VERSION ""

NS_ :

BS_:

BU_: Turbocharger OnBoardDataLogger OffBoardDiagnosticTool2 OffBoardDiagnosticTool1 FileServer ParkingBrakeController SeatControl2 FanDriveController SteeringColumnUnit CommunicationUnitRadio CommunicationUnitSatellite CommunicationUnitCellular PropulsionBatteryCharger ChassisController2 ChassisController1 EngineValveControl AuxiliaryHeater2 AuxiliaryHeater1 ClutchUnit RampControl InformationSystem1 SuspensionSystemController2 OilSensor VehicleDynamicStability ExhaustEmissionController TransmissionDisplay2 TransmissionDisplay1 ClimateControl2 WaterPumpController RearAxleSteeringController LightingOperatorControl SeatController1 IgnitionController2 IgnitionController1 TirePressureController CabController2 CabController1 PneumaticSystemController SuspensionSystemController1 HydraulicPumpController EnduranceBrakingSystem RetarderExhaustEngine2 OnBoardDiagnosticUnit HeadwayController RetarderExhaustEngine1 CabDisplay1 ManagementComputer VirtualTerminal OffVehicleGateway PowerTakeOffFront HitchControl AuxiliaryValveControl BodyController TractorTrailerBridge1 StarterSystem ElectricalSystem VehicleSecurity VehicleNavigation AerodynamicControl ElectricalChargingSystem ClimateControl1 TripRecorder InstrumentCluster SuspensionDriveAxle2 SuspensionDriveAxle1 SuspensionSteerAxle SteeringController FuelSystem CruiseControl RetarderDriveline RetarderEngine BrakesDriveAxle2 BrakesDriveAxle1 BrakesSystemController BrakesSteerAxle AxleDrive2 AxleDrive1 AxleSteering PowerTakeOff ShiftConsoleSecondary ShiftConsolePrimary Transmission2 Transmission1 Engine2 Engine1
VAL_TABLE_ vtsig_Disable_VGT_Braking 3 "Description for the value '0x3'" 2 "Error" 1 "True" 0 "False" ;
VAL_TABLE_ vtsig_CoastModeStatus 3 "Not Available" 2 "Error" 1 "Enabled" 0 "Disabled" ;
VAL_TABLE_ vtsig_TransmissionType 15 "Legacy Trans" 0 "Fuel Eco Trans" ;

BO_ 3221225472 VECTOR__INDEPENDENT_SIG_MSG: 0 Vector__XXX
 SG_ TransCoastModeStatus : 0|2@1+ (1,0) [0|0] "" Vector__XXX
 SG_ TrailerWeight : 0|16@1+ (2,0) [0|128510] "kg" Vector__XXX
 SG_ ReferenceTirePressSetting : 0|8@1+ (8,0) [0|2000] "kPa" Vector__XXX
 SG_ ReferenceTirePress : 0|8@1+ (8,0) [0|2000] "kPa" Vector__XXX
 SG_ TirePressThresholdDetection : 0|3@1+ (1,0) [0|7] "" Vector__XXX
 SG_ TireAirLeakageRate : 0|16@1+ (0.1,0) [0|6425.5] "Pa/s" Vector__XXX
 SG_ CTIWheelEndElectricalFault : 0|2@1+ (1,0) [0|3] "" Vector__XXX
 SG_ CTITireStatus : 0|2@1+ (1,0) [0|3] "" Vector__XXX
 SG_ CTIWheelSensorStatus : 0|2@1+ (1,0) [0|3] "" Vector__XXX
 SG_ TireTemp : 0|16@1+ (0.03125,-273) [-273|1734.96875] "deg C" Vector__XXX
 SG_ TirePress : 0|8@1+ (4,0) [0|1000] "kPa" Vector__XXX
 SG_ DTC2 : 0|32@1+ (1,0) [0|4294967295] "" Vector__XXX
 SG_ DTC3 : 0|32@1+ (1,0) [0|4294967295] "" Vector__XXX
 SG_ DTC4 : 0|32@1+ (1,0) [0|4294967295] "" Vector__XXX
 SG_ SPNConversionMethod_DTC2 : 0|1@1+ (1,0) [0|1] "" Vector__XXX
 SG_ FMI_DTC6 : 0|5@1+ (1,0) [0|32] "" Vector__XXX
 SG_ SPNConversionMethod_DTC7 : 0|1@1+ (1,0) [0|1] "" Vector__XXX
 SG_ SPN3_DTC7 : 0|3@1+ (1,0) [0|7] "" Vector__XXX

BO_ 2565935153 B2_SA_31: 3 Vector__XXX
 SG_ BrakeSwitch2 : 16|2@1+ (1,0) [0|3] "" Vector__XXX
 SG_ DemandedBrakeApplicationPressure : 0|16@1+ (0.1,0) [0|6425.5] "kPa" Vector__XXX

BO_ 2565935127 B2_SA_17: 3 Vector__XXX
 SG_ BrakeSwitch2 : 16|2@1+ (1,0) [0|3] "" Vector__XXX
 SG_ DemandedBrakeApplicationPressure : 0|16@1+ (0.1,0) [0|6425.5] "kPa" Vector__XXX

BO_ 2565935121 B2_SA_11: 3 Vector__XXX
 SG_ BrakeSwitch2 : 16|2@1+ (1,0) [0|3] "" Vector__XXX
 SG_ DemandedBrakeApplicationPressure : 0|16@1+ (0.1,0) [0|6425.5] "kPa" Vector__XXX

BO_ 2565935115 B2_SA_0B: 3 Vector__XXX
 SG_ BrakeSwitch2 : 16|2@1+ (1,0) [0|3] "" Vector__XXX
 SG_ DemandedBrakeApplicationPressure : 0|16@1+ (0.1,0) [0|6425.5] "kPa" Vector__XXX

BO_ 2565935104 B2_SA_00: 3 Vector__XXX
 SG_ BrakeSwitch2 : 16|2@1+ (1,0) [0|3] "" Vector__XXX
 SG_ DemandedBrakeApplicationPressure : 0|16@1+ (0.1,0) [0|6425.5] "kPa" Vector__XXX

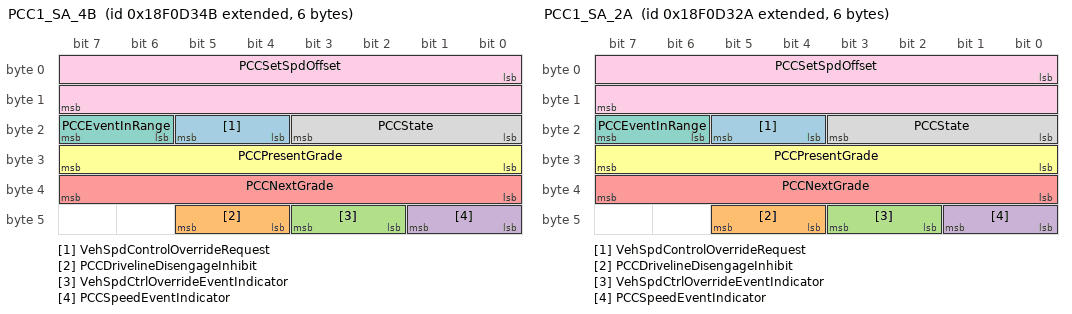
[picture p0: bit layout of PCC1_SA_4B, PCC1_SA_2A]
BO_ 2565919563 PCC1_SA_4B: 6 Vector__XXX
 SG_ VehSpdControlOverrideRequest : 20|2@1- (1,0) [0|0] "" Vector__XXX
 SG_ PCCDrivelineDisengageInhibit : 44|2@1- (1,0) [0|0] "" Vector__XXX
 SG_ VehSpdCtrlOverrideEventIndicator : 42|2@1- (1,0) [0|0] "" Vector__XXX
 SG_ PCCSpeedEventIndicator : 40|2@1- (1,0) [0|0] "" Vector__XXX
 SG_ PCCNextGrade : 32|8@1+ (0.125,-16) [0|0] "" Vector__XXX
 SG_ PCCPresentGrade : 24|8@1+ (0.125,-16) [0|0] "" Vector__XXX
 SG_ PCCEventInRange : 22|2@1- (1,0) [0|0] "" Vector__XXX
 SG_ PCCState : 16|4@1- (1,0) [0|0] "" Vector__XXX
 SG_ PCCSetSpdOffset : 0|16@1- (0.00390625,-125) [-125|126] "km/h" Vector__XXX

BO_ 2565919530 PCC1_SA_2A: 6 Vector__XXX
 SG_ VehSpdControlOverrideRequest : 20|2@1- (1,0) [0|0] "" Vector__XXX
 SG_ PCCDrivelineDisengageInhibit : 44|2@1- (1,0) [0|0] "" Vector__XXX
 SG_ VehSpdCtrlOverrideEventIndicator : 42|2@1- (1,0) [0|0] "" Vector__XXX
 SG_ PCCSpeedEventIndicator : 40|2@1- (1,0) [0|0] "" Vector__XXX
 SG_ PCCNextGrade : 32|8@1+ (0.125,-16) [0|0] "" Vector__XXX
 SG_ PCCPresentGrade : 24|8@1+ (0.125,-16) [0|0] "" Vector__XXX
 SG_ PCCEventInRange : 22|2@1- (1,0) [0|0] "" Vector__XXX
 SG_ PCCState : 16|4@1- (1,0) [0|0] "" Vector__XXX
 SG_ PCCSetSpdOffset : 0|16@1- (0.00390625,-125) [-125|126] "km/h" Vector__XXX

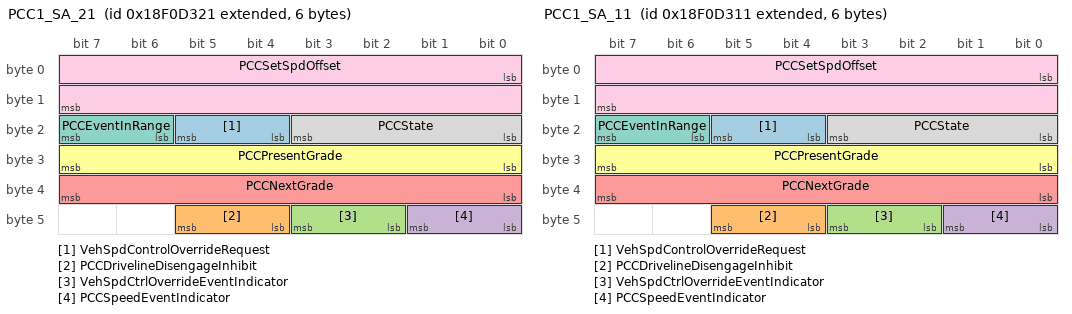
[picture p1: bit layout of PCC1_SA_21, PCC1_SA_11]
BO_ 2565919521 PCC1_SA_21: 6 Vector__XXX
 SG_ VehSpdControlOverrideRequest : 20|2@1- (1,0) [0|0] "" Vector__XXX
 SG_ PCCDrivelineDisengageInhibit : 44|2@1- (1,0) [0|0] "" Vector__XXX
 SG_ VehSpdCtrlOverrideEventIndicator : 42|2@1- (1,0) [0|0] "" Vector__XXX
 SG_ PCCSpeedEventIndicator : 40|2@1- (1,0) [0|0] "" Vector__XXX
 SG_ PCCNextGrade : 32|8@1+ (0.125,-16) [0|0] "" Vector__XXX
 SG_ PCCPresentGrade : 24|8@1+ (0.125,-16) [0|0] "" Vector__XXX
 SG_ PCCEventInRange : 22|2@1- (1,0) [0|0] "" Vector__XXX
 SG_ PCCState : 16|4@1- (1,0) [0|0] "" Vector__XXX
 SG_ PCCSetSpdOffset : 0|16@1- (0.00390625,-125) [-125|126] "km/h" Vector__XXX

BO_ 2565919505 PCC1_SA_11: 6 Vector__XXX
 SG_ VehSpdControlOverrideRequest : 20|2@1- (1,0) [0|0] "" Vector__XXX
 SG_ PCCDrivelineDisengageInhibit : 44|2@1- (1,0) [0|0] "" Vector__XXX
 SG_ VehSpdCtrlOverrideEventIndicator : 42|2@1- (1,0) [0|0] "" Vector__XXX
 SG_ PCCSpeedEventIndicator : 40|2@1- (1,0) [0|0] "" Vector__XXX
 SG_ PCCNextGrade : 32|8@1+ (0.125,-16) [0|0] "" Vector__XXX
 SG_ PCCPresentGrade : 24|8@1+ (0.125,-16) [0|0] "" Vector__XXX
 SG_ PCCEventInRange : 22|2@1- (1,0) [0|0] "" Vector__XXX
 SG_ PCCState : 16|4@1- (1,0) [0|0] "" Vector__XXX
 SG_ PCCSetSpdOffset : 0|16@1- (0.00390625,-125) [-125|126] "km/h" Vector__XXX

BO_ 2566705667 DM54_SA_03: 54 Vector__XXX
 SG_ DM54_SPNConversionMethod_DTC8 : 271|1@1+ (1,0) [0|1] "" Vector__XXX
 SG_ DM54_OccurenceCount_DTC8 : 264|7@1+ (1,0) [0|126] "" Vector__XXX
 SG_ DM54_SPN3_DTC8 : 261|3@1+ (1,0) [0|7] "" Vector__XXX
 SG_ DM54_FMI_DTC8 : 256|5@1+ (1,0) [0|32] "" Vector__XXX
 SG_ DM54_SPN2_DTC8 : 248|8@1+ (1,0) [0|255] "" Vector__XXX
 SG_ DM54_SPN1_DTC8 : 240|8@1+ (1,0) [0|255] "" Vector__XXX
 SG_ DM54_SPNConversionMethod_DTC7 : 239|1@1+ (1,0) [0|1] "" Vector__XXX
 SG_ DM54_OccurenceCount_DTC7 : 232|7@1+ (1,0) [0|126] "" Vector__XXX
 SG_ DM54_SPN3_DTC7 : 229|3@1+ (1,0) [0|7] "" Vector__XXX
 SG_ DM54_FMI_DTC7 : 224|5@1+ (1,0) [0|32] "" Vector__XXX
 SG_ DM54_SPN2_DTC7 : 216|8@1+ (1,0) [0|255] "" Vector__XXX
 SG_ DM54_SPN1_DTC7 : 208|8@1+ (1,0) [0|255] "" Vector__XXX
 SG_ DM54_SPNConversionMethod_DTC6 : 207|1@1+ (1,0) [0|1] "" Vector__XXX
 SG_ DM54_OccurenceCount_DTC6 : 200|7@1+ (1,0) [0|126] "" Vector__XXX
 SG_ DM54_SPN3_DTC6 : 197|3@1+ (1,0) [0|7] "" Vector__XXX
 SG_ DM54_FMI_DTC6 : 192|5@1+ (1,0) [0|32] "" Vector__XXX
 SG_ DM54_SPN2_DTC6 : 184|8@1+ (1,0) [0|255] "" Vector__XXX
 SG_ DM54_SPN1_DTC6 : 176|8@1+ (1,0) [0|255] "" Vector__XXX
 SG_ DM54_SPNConversionMethod_DTC5 : 175|1@1+ (1,0) [0|1] "" Vector__XXX
 SG_ DM54_OccurenceCount_DTC5 : 168|7@1+ (1,0) [0|126] "" Vector__XXX
 SG_ DM54_SPN3_DTC5 : 165|3@1+ (1,0) [0|7] "" Vector__XXX
 SG_ DM54_FMI_DTC5 : 160|5@1+ (1,0) [0|32] "" Vector__XXX
 SG_ DM54_SPN2_DTC5 : 152|8@1+ (1,0) [0|255] "" Vector__XXX
 SG_ DM54_SPN1_DTC5 : 144|8@1+ (1,0) [0|255] "" Vector__XXX
 SG_ DM54_SPNConversionMethod_DTC4 : 143|1@1+ (1,0) [0|1] "" Vector__XXX
 SG_ DM54_OccurenceCount_DTC4 : 136|7@1+ (1,0) [0|126] "" Vector__XXX
 SG_ DM54_SPN3_DTC4 : 133|3@1+ (1,0) [0|7] "" Vector__XXX
 SG_ DM54_FMI_DTC4 : 128|5@1+ (1,0) [0|32] "" Vector__XXX
 SG_ DM54_SPN2_DTC4 : 120|8@1+ (1,0) [0|255] "" Vector__XXX
 SG_ DM54_SPN1_DTC4 : 112|8@1+ (1,0) [0|255] "" Vector__XXX
 SG_ DM54_SPNConversionMethod_DTC3 : 111|1@1+ (1,0) [0|1] "" Vector__XXX
 SG_ DM54_OccurenceCount_DTC3 : 104|7@1+ (1,0) [0|126] "" Vector__XXX
 SG_ DM54_SPN3_DTC3 : 101|3@1+ (1,0) [0|7] "" Vector__XXX
 SG_ DM54_FMI_DTC3 : 96|5@1+ (1,0) [0|32] "" Vector__XXX
 SG_ DM54_SPN2_DTC3 : 88|8@1+ (1,0) [0|255] "" Vector__XXX
 SG_ DM54_SPN1_DTC3 : 80|8@1+ (1,0) [0|255] "" Vector__XXX
 SG_ DM54_SPNConversionMethod_DTC2 : 79|1@1+ (1,0) [0|1] "" Vector__XXX
 SG_ DM54_OccurenceCount_DTC2 : 72|7@1+ (1,0) [0|126] "" Vector__XXX
 SG_ DM54_SPN3_DTC2 : 69|3@1+ (1,0) [0|7] "" Vector__XXX
 SG_ DM54_FMI_DTC2 : 64|5@1+ (1,0) [0|32] "" Vector__XXX
 SG_ DM54_SPN2_DTC2 : 56|8@1+ (1,0) [0|255] "" Vector__XXX
 SG_ DM54_SPN1_DTC2 : 48|8@1+ (1,0) [0|255] "" Vector__XXX
 SG_ DM54_SPNConversionMethod_DTC1 : 47|1@1+ (1,0) [0|1] "" Vector__XXX
 SG_ DM54_OccurenceCount_DTC1 : 40|7@1+ (1,0) [0|126] "" Vector__XXX
 SG_ DM54_SPN3_DTC1 : 37|3@1+ (1,0) [0|7] "" Vector__XXX
 SG_ DM54_FMI_DTC1 : 32|5@1+ (1,0) [0|32] "" Vector__XXX
 SG_ DM54_SPN2_DTC1 : 24|8@1+ (1,0) [0|255] "" Vector__XXX
 SG_ DM54_SPN1_DTC1 : 16|8@1+ (1,0) [0|255] "" Vector__XXX
 SG_ DM54FlashMalfuncIndicatorLamp : 14|2@1+ (1,0) [0|3] "" Vector__XXX
 SG_ DM54FlashRedStopLamp : 12|2@1+ (1,0) [0|3] "" Vector__XXX
 SG_ DM54FlashAmberWarningLamp : 10|2@1+ (1,0) [0|3] "" Vector__XXX
 SG_ DM54FlashProtectLamp : 8|2@1+ (1,0) [0|3] "" Vector__XXX
 SG_ DM54MalfunctionIndicateLampState : 6|2@1+ (1,0) [0|3] "" Vector__XXX
 SG_ DM54RedStopLampState : 4|2@1+ (1,0) [0|3] "" Vector__XXX
 SG_ DM54AmberWarningLampStatus : 2|2@1+ (1,0) [0|3] "" Vector__XXX
 SG_ DM54ProtectLampStatus : 0|2@1+ (1,0) [0|3] "" Vector__XXX

BO_ 2566705411 DM53_SA_03: 54 Vector__XXX
 SG_ DM53_SPNConversionMethod_DTC8 : 271|1@1+ (1,0) [0|1] "" Vector__XXX
 SG_ DM53_OccurenceCount_DTC8 : 264|7@1+ (1,0) [0|126] "" Vector__XXX
 SG_ DM53_SPN3_DTC8 : 261|3@1+ (1,0) [0|7] "" Vector__XXX
 SG_ DM53_FMI_DTC8 : 256|5@1+ (1,0) [0|32] "" Vector__XXX
 SG_ DM53_SPN2_DTC8 : 248|8@1+ (1,0) [0|255] "" Vector__XXX
 SG_ DM53_SPN1_DTC8 : 240|8@1+ (1,0) [0|255] "" Vector__XXX
 SG_ DM53_SPNConversionMethod_DTC7 : 239|1@1+ (1,0) [0|1] "" Vector__XXX
 SG_ DM53_OccurenceCount_DTC7 : 232|7@1+ (1,0) [0|126] "" Vector__XXX
 SG_ DM53_SPN3_DTC7 : 229|3@1+ (1,0) [0|7] "" Vector__XXX
 SG_ DM53_FMI_DTC7 : 224|5@1+ (1,0) [0|32] "" Vector__XXX
 SG_ DM53_SPN2_DTC7 : 216|8@1+ (1,0) [0|255] "" Vector__XXX
 SG_ DM53_SPN1_DTC7 : 208|8@1+ (1,0) [0|255] "" Vector__XXX
 SG_ DM53_SPNConversionMethod_DTC6 : 207|1@1+ (1,0) [0|1] "" Vector__XXX
 SG_ DM53_OccurenceCount_DTC6 : 200|7@1+ (1,0) [0|126] "" Vector__XXX
 SG_ DM53_SPN3_DTC6 : 197|3@1+ (1,0) [0|7] "" Vector__XXX
 SG_ DM53_FMI_DTC6 : 192|5@1+ (1,0) [0|32] "" Vector__XXX
 SG_ DM53_SPN2_DTC6 : 184|8@1+ (1,0) [0|255] "" Vector__XXX
 SG_ DM53_SPN1_DTC6 : 176|8@1+ (1,0) [0|255] "" Vector__XXX
 SG_ DM53_SPNConversionMethod_DTC5 : 175|1@1+ (1,0) [0|1] "" Vector__XXX
 SG_ DM53_OccurenceCount_DTC5 : 168|7@1+ (1,0) [0|126] "" Vector__XXX
 SG_ DM53_SPN3_DTC5 : 165|3@1+ (1,0) [0|7] "" Vector__XXX
 SG_ DM53_FMI_DTC5 : 160|5@1+ (1,0) [0|32] "" Vector__XXX
 SG_ DM53_SPN2_DTC5 : 152|8@1+ (1,0) [0|255] "" Vector__XXX
 SG_ DM53_SPN1_DTC5 : 144|8@1+ (1,0) [0|255] "" Vector__XXX
 SG_ DM53_SPNConversionMethod_DTC4 : 143|1@1+ (1,0) [0|1] "" Vector__XXX
 SG_ DM53_OccurenceCount_DTC4 : 136|7@1+ (1,0) [0|126] "" Vector__XXX
 SG_ DM53_SPN3_DTC4 : 133|3@1+ (1,0) [0|7] "" Vector__XXX
 SG_ DM53_FMI_DTC4 : 128|5@1+ (1,0) [0|32] "" Vector__XXX
 SG_ DM53_SPN2_DTC4 : 120|8@1+ (1,0) [0|255] "" Vector__XXX
 SG_ DM53_SPN1_DTC4 : 112|8@1+ (1,0) [0|255] "" Vector__XXX
 SG_ DM53_SPNConversionMethod_DTC3 : 111|1@1+ (1,0) [0|1] "" Vector__XXX
 SG_ DM53_OccurenceCount_DTC3 : 104|7@1+ (1,0) [0|126] "" Vector__XXX
 SG_ DM53_SPN3_DTC3 : 101|3@1+ (1,0) [0|7] "" Vector__XXX
 SG_ DM53_FMI_DTC3 : 96|5@1+ (1,0) [0|32] "" Vector__XXX
 SG_ DM53_SPN2_DTC3 : 88|8@1+ (1,0) [0|255] "" Vector__XXX
 SG_ DM53_SPN1_DTC3 : 80|8@1+ (1,0) [0|255] "" Vector__XXX
 SG_ DM53_SPNConversionMethod_DTC2 : 79|1@1+ (1,0) [0|1] "" Vector__XXX
 SG_ DM53_OccurenceCount_DTC2 : 72|7@1+ (1,0) [0|126] "" Vector__XXX
 SG_ DM53_SPN3_DTC2 : 69|3@1+ (1,0) [0|7] "" Vector__XXX
 SG_ DM53_FMI_DTC2 : 64|5@1+ (1,0) [0|32] "" Vector__XXX
 SG_ DM53_SPN2_DTC2 : 56|8@1+ (1,0) [0|255] "" Vector__XXX
 SG_ DM53_SPN1_DTC2 : 48|8@1+ (1,0) [0|255] "" Vector__XXX
 SG_ DM53_SPNConversionMethod_DTC1 : 47|1@1+ (1,0) [0|1] "" Vector__XXX
 SG_ DM53_OccurenceCount_DTC1 : 40|7@1+ (1,0) [0|126] "" Vector__XXX
 SG_ DM53_SPN3_DTC1 : 37|3@1+ (1,0) [0|7] "" Vector__XXX
 SG_ DM53_FMI_DTC1 : 32|5@1+ (1,0) [0|32] "" Vector__XXX
 SG_ DM53_SPN2_DTC1 : 24|8@1+ (1,0) [0|255] "" Vector__XXX
 SG_ DM53_SPN1_DTC1 : 16|8@1+ (1,0) [0|255] "" Vector__XXX
 SG_ DM53FlashMalfuncIndicatorLamp : 14|2@1+ (1,0) [0|3] "" Vector__XXX
 SG_ DM53FlashRedStopLamp : 12|2@1+ (1,0) [0|3] "" Vector__XXX
 SG_ DM53FlashAmberWarningLamp : 10|2@1+ (1,0) [0|3] "" Vector__XXX
 SG_ DM53FlashProtectLamp : 8|2@1+ (1,0) [0|3] "" Vector__XXX
 SG_ DM53MalfunctionIndicateLampState : 6|2@1+ (1,0) [0|3] "" Vector__XXX
 SG_ DM53RedStopLampState : 4|2@1+ (1,0) [0|3] "" Vector__XXX
 SG_ DM53AmberWarningLampStatus : 2|2@1+ (1,0) [0|3] "" Vector__XXX
 SG_ DM53ProtectLampStatus : 0|2@1+ (1,0) [0|3] "" Vector__XXX

BO_ 2565935358 B2: 3 Vector__XXX
 SG_ BrakeSwitch2 : 16|2@1+ (1,0) [0|3] "" Vector__XXX
 SG_ DemandedBrakeApplicationPressure : 0|16@1+ (0.1,0) [0|6425.5] "kPa" Vector__XXX

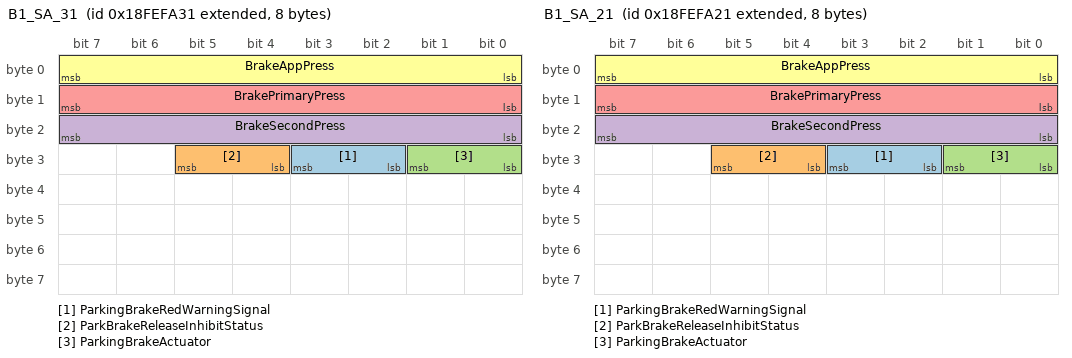
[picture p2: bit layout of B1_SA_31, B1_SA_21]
BO_ 2566847025 B1_SA_31: 8 Vector__XXX
 SG_ ParkingBrakeRedWarningSignal : 26|2@1+ (1,0) [0|3] "" Vector__XXX
 SG_ ParkBrakeReleaseInhibitStatus : 28|2@1+ (1,0) [0|3] "" Vector__XXX
 SG_ ParkingBrakeActuator : 24|2@1+ (1,0) [0|3] "" Vector__XXX
 SG_ BrakeSecondPress : 16|8@1+ (4,0) [0|1000] "kPa" Vector__XXX
 SG_ BrakePrimaryPress : 8|8@1+ (4,0) [0|1000] "kPa" Vector__XXX
 SG_ BrakeAppPress : 0|8@1+ (4,0) [0|1000] "kPa" Vector__XXX

BO_ 2566847009 B1_SA_21: 8 Vector__XXX
 SG_ ParkingBrakeRedWarningSignal : 26|2@1+ (1,0) [0|3] "" Vector__XXX
 SG_ ParkBrakeReleaseInhibitStatus : 28|2@1+ (1,0) [0|3] "" Vector__XXX
 SG_ ParkingBrakeActuator : 24|2@1+ (1,0) [0|3] "" Vector__XXX
 SG_ BrakeSecondPress : 16|8@1+ (4,0) [0|1000] "kPa" Vector__XXX
 SG_ BrakePrimaryPress : 8|8@1+ (4,0) [0|1000] "kPa" Vector__XXX
 SG_ BrakeAppPress : 0|8@1+ (4,0) [0|1000] "kPa" Vector__XXX

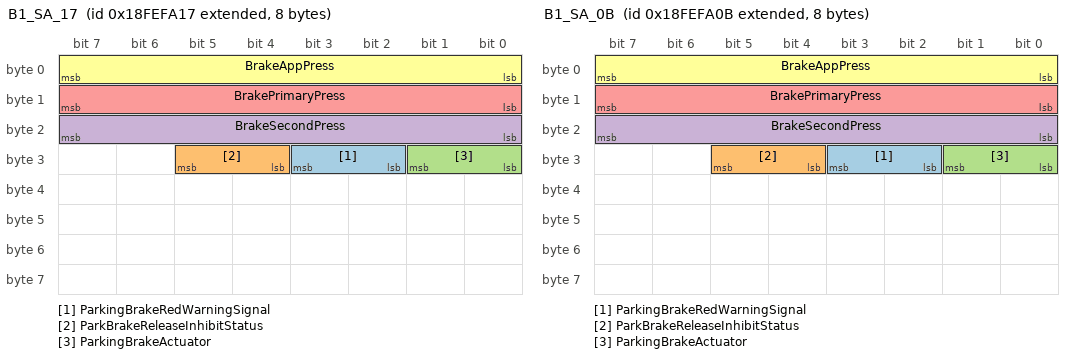
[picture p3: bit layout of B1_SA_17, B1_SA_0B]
BO_ 2566846999 B1_SA_17: 8 Vector__XXX
 SG_ ParkingBrakeRedWarningSignal : 26|2@1+ (1,0) [0|3] "" Vector__XXX
 SG_ ParkBrakeReleaseInhibitStatus : 28|2@1+ (1,0) [0|3] "" Vector__XXX
 SG_ ParkingBrakeActuator : 24|2@1+ (1,0) [0|3] "" Vector__XXX
 SG_ BrakeSecondPress : 16|8@1+ (4,0) [0|1000] "kPa" Vector__XXX
 SG_ BrakePrimaryPress : 8|8@1+ (4,0) [0|1000] "kPa" Vector__XXX
 SG_ BrakeAppPress : 0|8@1+ (4,0) [0|1000] "kPa" Vector__XXX

BO_ 2566846987 B1_SA_0B: 8 Vector__XXX
 SG_ ParkingBrakeRedWarningSignal : 26|2@1+ (1,0) [0|3] "" Vector__XXX
 SG_ ParkBrakeReleaseInhibitStatus : 28|2@1+ (1,0) [0|3] "" Vector__XXX
 SG_ ParkingBrakeActuator : 24|2@1+ (1,0) [0|3] "" Vector__XXX
 SG_ BrakeSecondPress : 16|8@1+ (4,0) [0|1000] "kPa" Vector__XXX
 SG_ BrakePrimaryPress : 8|8@1+ (4,0) [0|1000] "kPa" Vector__XXX
 SG_ BrakeAppPress : 0|8@1+ (4,0) [0|1000] "kPa" Vector__XXX

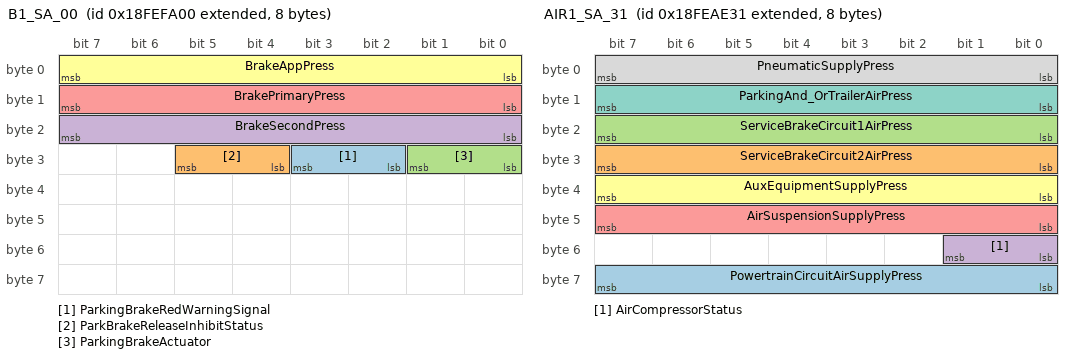
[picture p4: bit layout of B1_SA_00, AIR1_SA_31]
BO_ 2566846976 B1_SA_00: 8 Vector__XXX
 SG_ ParkingBrakeRedWarningSignal : 26|2@1+ (1,0) [0|3] "" Vector__XXX
 SG_ ParkBrakeReleaseInhibitStatus : 28|2@1+ (1,0) [0|3] "" Vector__XXX
 SG_ ParkingBrakeActuator : 24|2@1+ (1,0) [0|3] "" Vector__XXX
 SG_ BrakeSecondPress : 16|8@1+ (4,0) [0|1000] "kPa" Vector__XXX
 SG_ BrakePrimaryPress : 8|8@1+ (4,0) [0|1000] "kPa" Vector__XXX
 SG_ BrakeAppPress : 0|8@1+ (4,0) [0|1000] "kPa" Vector__XXX

BO_ 2566827569 AIR1_SA_31: 8 Vector__XXX
 SG_ PowertrainCircuitAirSupplyPress : 56|8@1+ (8,0) [0|2000] "kPa" Vector__XXX
 SG_ ServiceBrakeCircuit2AirPress : 24|8@1+ (8,0) [0|2000] "kPa" Vector__XXX
 SG_ ServiceBrakeCircuit1AirPress : 16|8@1+ (8,0) [0|2000] "kPa" Vector__XXX
 SG_ AirCompressorStatus : 48|2@1+ (1,0) [0|3] "" Vector__XXX
 SG_ AirSuspensionSupplyPress : 40|8@1+ (8,0) [0|2000] "kPa" Vector__XXX
 SG_ AuxEquipmentSupplyPress : 32|8@1+ (8,0) [0|2000] "kPa" Vector__XXX
 SG_ ParkingAnd_OrTrailerAirPress : 8|8@1+ (8,0) [0|2000] "kPa" Vector__XXX
 SG_ PneumaticSupplyPress : 0|8@1+ (8,0) [0|2000] "kPa" Vector__XXX

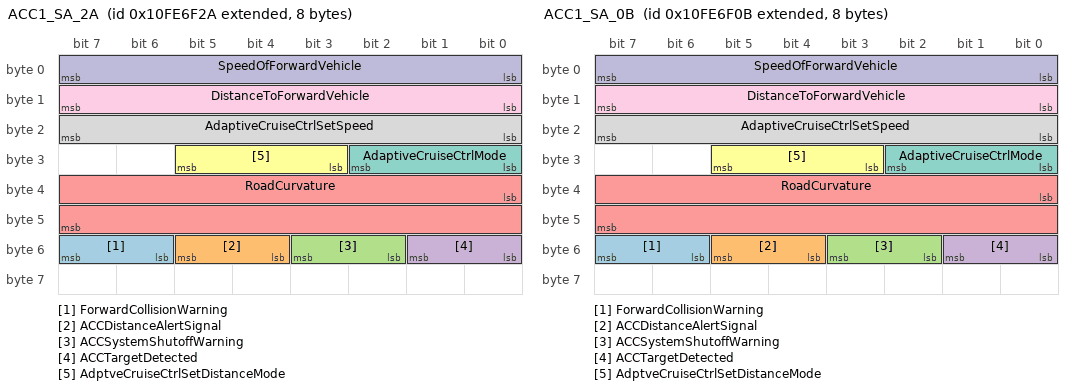
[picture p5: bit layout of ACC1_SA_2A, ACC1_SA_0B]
BO_ 2432593706 ACC1_SA_2A: 8 Vector__XXX
 SG_ ForwardCollisionWarning : 54|2@1+ (1,0) [0|3] "" Vector__XXX
 SG_ ACCDistanceAlertSignal : 52|2@1+ (1,0) [0|3] "" Vector__XXX
 SG_ ACCSystemShutoffWarning : 50|2@1+ (1,0) [0|3] "" Vector__XXX
 SG_ ACCTargetDetected : 48|2@1+ (1,0) [0|3] "" Vector__XXX
 SG_ RoadCurvature : 32|16@1+ (0.0078125,-250) [-250|251.992] "1/km" Vector__XXX
 SG_ AdptveCruiseCtrlSetDistanceMode : 27|3@1+ (1,0) [0|7] "" Vector__XXX
 SG_ AdaptiveCruiseCtrlMode : 24|3@1+ (1,0) [0|7] "" Vector__XXX
 SG_ AdaptiveCruiseCtrlSetSpeed : 16|8@1+ (1,0) [0|250] "km/h" Vector__XXX
 SG_ DistanceToForwardVehicle : 8|8@1+ (1,0) [0|250] "m" Vector__XXX
 SG_ SpeedOfForwardVehicle : 0|8@1+ (1,0) [0|250] "km/h" Vector__XXX

BO_ 2432593675 ACC1_SA_0B: 8 Vector__XXX
 SG_ ForwardCollisionWarning : 54|2@1+ (1,0) [0|3] "" Vector__XXX
 SG_ ACCDistanceAlertSignal : 52|2@1+ (1,0) [0|3] "" Vector__XXX
 SG_ ACCSystemShutoffWarning : 50|2@1+ (1,0) [0|3] "" Vector__XXX
 SG_ ACCTargetDetected : 48|2@1+ (1,0) [0|3] "" Vector__XXX
 SG_ RoadCurvature : 32|16@1+ (0.0078125,-250) [-250|251.992] "1/km" Vector__XXX
 SG_ AdptveCruiseCtrlSetDistanceMode : 27|3@1+ (1,0) [0|7] "" Vector__XXX
 SG_ AdaptiveCruiseCtrlMode : 24|3@1+ (1,0) [0|7] "" Vector__XXX
 SG_ AdaptiveCruiseCtrlSetSpeed : 16|8@1+ (1,0) [0|250] "km/h" Vector__XXX
 SG_ DistanceToForwardVehicle : 8|8@1+ (1,0) [0|250] "m" Vector__XXX
 SG_ SpeedOfForwardVehicle : 0|8@1+ (1,0) [0|250] "km/h" Vector__XXX

BO_ 2566840617 RC_SA_29: 19 Vector__XXX
 SG_ PercentTorqueAtPeakTorquePoint5 : 144|8@1+ (1,-125) [-125|125] "%" Vector__XXX
 SG_ ReferenceRetarderTorque : 128|16@1+ (1,0) [0|64255] "Nm" Vector__XXX
 SG_ RetarderSpeedAtPeakTorquePoint5 : 112|16@1+ (0.125,0) [0|8031.875] "rpm" Vector__XXX
 SG_ PercentTorqueAtPoint4 : 104|8@1+ (1,-125) [-125|125] "%" Vector__XXX
 SG_ RetarderSpeedAtPoint4 : 88|16@1+ (0.125,0) [0|8031.875] "rpm" Vector__XXX
 SG_ PercentTorqueAtPoint3 : 80|8@1+ (1,-125) [-125|125] "%" Vector__XXX
 SG_ RetarderSpeedAtPoint3 : 64|16@1+ (0.125,0) [0|8031.875] "rpm" Vector__XXX
 SG_ PercentTorqueAtMaxSpeedPoint2 : 56|8@1+ (1,-125) [-125|125] "%" Vector__XXX
 SG_ MaxRetarderSpeedPoint2 : 40|16@1+ (0.125,0) [0|8031.875] "rpm" Vector__XXX
 SG_ PercentTorqueAtIdlePoint1 : 32|8@1+ (1,-125) [-125|125] "%" Vector__XXX
 SG_ RetarderSpeedAtIdlePoint1 : 16|16@1+ (0.125,0) [0|8031.875] "rpm" Vector__XXX
 SG_ RetarderCtrlMethod : 8|8@1+ (1,0) [0|250] "steps" Vector__XXX
 SG_ RetarderLocation : 4|4@1+ (1,0) [0|15] "" Vector__XXX
 SG_ RetarderType : 0|4@1+ (1,0) [0|15] "" Vector__XXX

BO_ 2566840591 RC_SA_0F: 19 Vector__XXX
 SG_ PercentTorqueAtPeakTorquePoint5 : 144|8@1+ (1,-125) [-125|125] "%" Vector__XXX
 SG_ ReferenceRetarderTorque : 128|16@1+ (1,0) [0|64255] "Nm" Vector__XXX
 SG_ RetarderSpeedAtPeakTorquePoint5 : 112|16@1+ (0.125,0) [0|8031.875] "rpm" Vector__XXX
 SG_ PercentTorqueAtPoint4 : 104|8@1+ (1,-125) [-125|125] "%" Vector__XXX
 SG_ RetarderSpeedAtPoint4 : 88|16@1+ (0.125,0) [0|8031.875] "rpm" Vector__XXX
 SG_ PercentTorqueAtPoint3 : 80|8@1+ (1,-125) [-125|125] "%" Vector__XXX
 SG_ RetarderSpeedAtPoint3 : 64|16@1+ (0.125,0) [0|8031.875] "rpm" Vector__XXX
 SG_ PercentTorqueAtMaxSpeedPoint2 : 56|8@1+ (1,-125) [-125|125] "%" Vector__XXX
 SG_ MaxRetarderSpeedPoint2 : 40|16@1+ (0.125,0) [0|8031.875] "rpm" Vector__XXX
 SG_ PercentTorqueAtIdlePoint1 : 32|8@1+ (1,-125) [-125|125] "%" Vector__XXX
 SG_ RetarderSpeedAtIdlePoint1 : 16|16@1+ (0.125,0) [0|8031.875] "rpm" Vector__XXX
 SG_ RetarderCtrlMethod : 8|8@1+ (1,0) [0|250] "steps" Vector__XXX
 SG_ RetarderLocation : 4|4@1+ (1,0) [0|15] "" Vector__XXX
 SG_ RetarderType : 0|4@1+ (1,0) [0|15] "" Vector__XXX

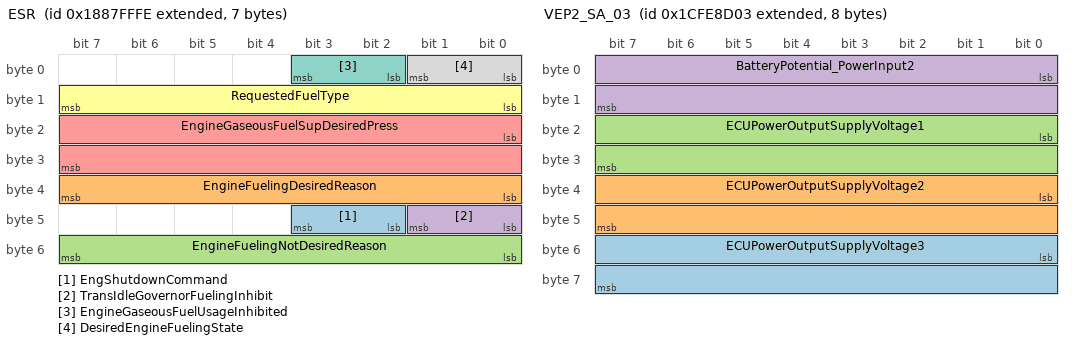
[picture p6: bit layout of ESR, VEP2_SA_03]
BO_ 2559049726 ESR: 7 Vector__XXX
 SG_ EngShutdownCommand : 42|2@1+ (1,0) [0|3] "" Vector__XXX
 SG_ EngineFuelingDesiredReason : 32|8@1+ (1,0) [0|255] "" Vector__XXX
 SG_ EngineFuelingNotDesiredReason : 48|8@1+ (1,0) [0|255] "" Vector__XXX
 SG_ TransIdleGovernorFuelingInhibit : 40|2@1+ (1,0) [0|3] "" Vector__XXX
 SG_ EngineGaseousFuelSupDesiredPress : 16|16@1+ (0.5,0) [0|32127.5] "kPa" Vector__XXX
 SG_ RequestedFuelType : 8|8@1+ (1,0) [0|255] "" Vector__XXX
 SG_ EngineGaseousFuelUsageInhibited : 2|2@1+ (1,0) [0|3] "" Vector__XXX
 SG_ DesiredEngineFuelingState : 0|2@1+ (1,0) [0|3] "" Vector__XXX

BO_ 2566759473 PTODE_SA_31: 8 Vector__XXX
 SG_ EnggmntSttusTransInputShaftPTO1 : 38|2@1+ (1,0) [0|3] "" Vector__XXX
 SG_ EnggmntSttusTransInputShaftPTO2 : 36|2@1+ (1,0) [0|3] "" Vector__XXX
 SG_ EnggmntSttusTransOutputShaftPTO : 34|2@1+ (1,0) [0|3] "" Vector__XXX
 SG_ EnggmntSttsTrnsfrCsOtptShaftPTO : 32|2@1+ (1,0) [0|3] "" Vector__XXX
 SG_ EnggmntCnsntTransInputShaftPTO1 : 22|2@1+ (1,0) [0|3] "" Vector__XXX
 SG_ EnggmntCnsntTransInputShaftPTO2 : 20|2@1+ (1,0) [0|3] "" Vector__XXX
 SG_ EnggmntCnsntTransOutputShaftPTO : 18|2@1+ (1,0) [0|3] "" Vector__XXX
 SG_ EnggmntCnsntTrnsfrCsOtptShftPTO : 16|2@1+ (1,0) [0|3] "" Vector__XXX
 SG_ EnableSwitchTransInputShaftPTO1 : 6|2@1+ (1,0) [0|3] "" Vector__XXX
 SG_ EnableSwitchTransInputShaftPTO2 : 4|2@1+ (1,0) [0|3] "" Vector__XXX
 SG_ EnableSwitchTransOutputShaftPTO : 2|2@1+ (1,0) [0|3] "" Vector__XXX
 SG_ EnblSwtchTrnsfrCsOutputShaftPTO : 0|2@1+ (1,0) [0|3] "" Vector__XXX
 SG_ EnggmntSttsPTOEngAccssoryDrive2 : 44|2@1+ (1,0) [0|3] "" Vector__XXX
 SG_ EnggmntSttsPTOEngAccssoryDrive1 : 42|2@1+ (1,0) [0|3] "" Vector__XXX
 SG_ EnggmntCnsntPTOEngAccssryDrive2 : 28|2@1+ (1,0) [0|3] "" Vector__XXX
 SG_ EnggmntCnsntPTOEngAccssryDrive1 : 26|2@1+ (1,0) [0|3] "" Vector__XXX
 SG_ EngagementStatusPTOEngFlywheel : 40|2@1+ (1,0) [0|3] "" Vector__XXX
 SG_ EngagementConsentPTOEngFlywheel : 24|2@1+ (1,0) [0|3] "" Vector__XXX
 SG_ EnblSwitchPTOEngAccessoryDrive2 : 12|2@1+ (1,0) [0|3] "" Vector__XXX
 SG_ EnblSwitchPTOEngAccessoryDrive1 : 10|2@1+ (1,0) [0|3] "" Vector__XXX
 SG_ EnableSwitchPTOEngFlywheel : 8|2@1+ (1,0) [0|3] "" Vector__XXX
 SG_ AtLeastOnePTOEngaged : 48|2@1+ (1,0) [0|3] "" Vector__XXX

BO_ 2566759463 PTODE_SA_27: 8 Vector__XXX
 SG_ EnggmntSttusTransInputShaftPTO1 : 38|2@1+ (1,0) [0|3] "" Vector__XXX
 SG_ EnggmntSttusTransInputShaftPTO2 : 36|2@1+ (1,0) [0|3] "" Vector__XXX
 SG_ EnggmntSttusTransOutputShaftPTO : 34|2@1+ (1,0) [0|3] "" Vector__XXX
 SG_ EnggmntSttsTrnsfrCsOtptShaftPTO : 32|2@1+ (1,0) [0|3] "" Vector__XXX
 SG_ EnggmntCnsntTransInputShaftPTO1 : 22|2@1+ (1,0) [0|3] "" Vector__XXX
 SG_ EnggmntCnsntTransInputShaftPTO2 : 20|2@1+ (1,0) [0|3] "" Vector__XXX
 SG_ EnggmntCnsntTransOutputShaftPTO : 18|2@1+ (1,0) [0|3] "" Vector__XXX
 SG_ EnggmntCnsntTrnsfrCsOtptShftPTO : 16|2@1+ (1,0) [0|3] "" Vector__XXX
 SG_ EnableSwitchTransInputShaftPTO1 : 6|2@1+ (1,0) [0|3] "" Vector__XXX
 SG_ EnableSwitchTransInputShaftPTO2 : 4|2@1+ (1,0) [0|3] "" Vector__XXX
 SG_ EnableSwitchTransOutputShaftPTO : 2|2@1+ (1,0) [0|3] "" Vector__XXX
 SG_ EnblSwtchTrnsfrCsOutputShaftPTO : 0|2@1+ (1,0) [0|3] "" Vector__XXX
 SG_ EnggmntSttsPTOEngAccssoryDrive2 : 44|2@1+ (1,0) [0|3] "" Vector__XXX
 SG_ EnggmntSttsPTOEngAccssoryDrive1 : 42|2@1+ (1,0) [0|3] "" Vector__XXX
 SG_ EnggmntCnsntPTOEngAccssryDrive2 : 28|2@1+ (1,0) [0|3] "" Vector__XXX
 SG_ EnggmntCnsntPTOEngAccssryDrive1 : 26|2@1+ (1,0) [0|3] "" Vector__XXX
 SG_ EngagementStatusPTOEngFlywheel : 40|2@1+ (1,0) [0|3] "" Vector__XXX
 SG_ EngagementConsentPTOEngFlywheel : 24|2@1+ (1,0) [0|3] "" Vector__XXX
 SG_ EnblSwitchPTOEngAccessoryDrive2 : 12|2@1+ (1,0) [0|3] "" Vector__XXX
 SG_ EnblSwitchPTOEngAccessoryDrive1 : 10|2@1+ (1,0) [0|3] "" Vector__XXX
 SG_ EnableSwitchPTOEngFlywheel : 8|2@1+ (1,0) [0|3] "" Vector__XXX
 SG_ AtLeastOnePTOEngaged : 48|2@1+ (1,0) [0|3] "" Vector__XXX

BO_ 2566759427 PTODE_SA_03: 8 Vector__XXX
 SG_ EnggmntSttusTransInputShaftPTO1 : 38|2@1+ (1,0) [0|3] "" Vector__XXX
 SG_ EnggmntSttusTransInputShaftPTO2 : 36|2@1+ (1,0) [0|3] "" Vector__XXX
 SG_ EnggmntSttusTransOutputShaftPTO : 34|2@1+ (1,0) [0|3] "" Vector__XXX
 SG_ EnggmntSttsTrnsfrCsOtptShaftPTO : 32|2@1+ (1,0) [0|3] "" Vector__XXX
 SG_ EnggmntCnsntTransInputShaftPTO1 : 22|2@1+ (1,0) [0|3] "" Vector__XXX
 SG_ EnggmntCnsntTransInputShaftPTO2 : 20|2@1+ (1,0) [0|3] "" Vector__XXX
 SG_ EnggmntCnsntTransOutputShaftPTO : 18|2@1+ (1,0) [0|3] "" Vector__XXX
 SG_ EnggmntCnsntTrnsfrCsOtptShftPTO : 16|2@1+ (1,0) [0|3] "" Vector__XXX
 SG_ EnableSwitchTransInputShaftPTO1 : 6|2@1+ (1,0) [0|3] "" Vector__XXX
 SG_ EnableSwitchTransInputShaftPTO2 : 4|2@1+ (1,0) [0|3] "" Vector__XXX
 SG_ EnableSwitchTransOutputShaftPTO : 2|2@1+ (1,0) [0|3] "" Vector__XXX
 SG_ EnblSwtchTrnsfrCsOutputShaftPTO : 0|2@1+ (1,0) [0|3] "" Vector__XXX
 SG_ EnggmntSttsPTOEngAccssoryDrive2 : 44|2@1+ (1,0) [0|3] "" Vector__XXX
 SG_ EnggmntSttsPTOEngAccssoryDrive1 : 42|2@1+ (1,0) [0|3] "" Vector__XXX
 SG_ EnggmntCnsntPTOEngAccssryDrive2 : 28|2@1+ (1,0) [0|3] "" Vector__XXX
 SG_ EnggmntCnsntPTOEngAccssryDrive1 : 26|2@1+ (1,0) [0|3] "" Vector__XXX
 SG_ EngagementStatusPTOEngFlywheel : 40|2@1+ (1,0) [0|3] "" Vector__XXX
 SG_ EngagementConsentPTOEngFlywheel : 24|2@1+ (1,0) [0|3] "" Vector__XXX
 SG_ EnblSwitchPTOEngAccessoryDrive2 : 12|2@1+ (1,0) [0|3] "" Vector__XXX
 SG_ EnblSwitchPTOEngAccessoryDrive1 : 10|2@1+ (1,0) [0|3] "" Vector__XXX
 SG_ EnableSwitchPTOEngFlywheel : 8|2@1+ (1,0) [0|3] "" Vector__XXX
 SG_ AtLeastOnePTOEngaged : 48|2@1+ (1,0) [0|3] "" Vector__XXX

BO_ 2633927939 VEP2_SA_03: 8 Vector__XXX
 SG_ ECUPowerOutputSupplyVoltage3 : 48|16@1+ (0.05,0) [0|3212.75] "V" Vector__XXX
 SG_ ECUPowerOutputSupplyVoltage2 : 32|16@1+ (0.05,0) [0|3212.75] "V" Vector__XXX
 SG_ ECUPowerOutputSupplyVoltage1 : 16|16@1+ (0.05,0) [0|3212.75] "V" Vector__XXX
 SG_ BatteryPotential_PowerInput2 : 0|16@1+ (0.05,0) [0|3212.75] "V" Vector__XXX

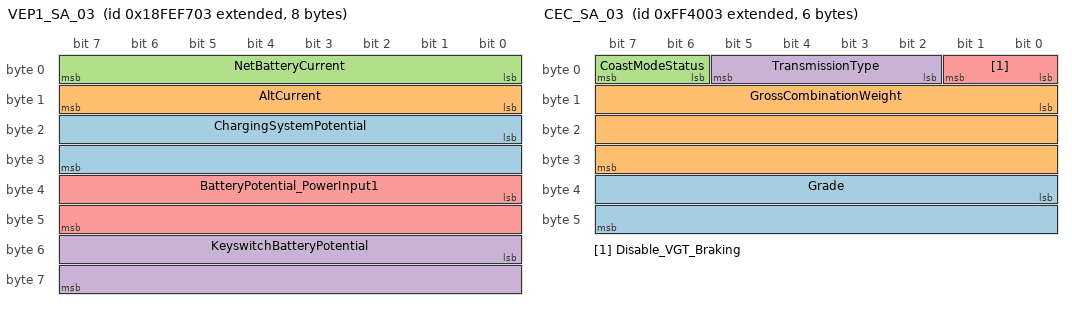
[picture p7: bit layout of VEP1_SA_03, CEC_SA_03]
BO_ 2566846211 VEP1_SA_03: 8 Vector__XXX
 SG_ ChargingSystemPotential : 16|16@1+ (0.05,0) [0|3212.75] "V" Vector__XXX
 SG_ AltCurrent : 8|8@1+ (1,0) [0|250] "A" Vector__XXX
 SG_ NetBatteryCurrent : 0|8@1+ (1,-125) [-125|125] "A" Vector__XXX
 SG_ KeyswitchBatteryPotential : 48|16@1+ (0.05,0) [0|3212.75] "V" Vector__XXX
 SG_ BatteryPotential_PowerInput1 : 32|16@1+ (0.05,0) [0|3212.75] "V" Vector__XXX

BO_ 2566841088 EC1_ISX: 39 Vector__XXX
 SG_ SupportTSC1CtrlPurposeGroup4 : 304|8@1+ (1,0) [0|255] "" Vector__XXX
 SG_ SupportTSC1CtrlPurposeGroup3 : 296|8@1+ (1,0) [0|255] "" Vector__XXX
 SG_ SupportTSC1CtrlPurposeGroup2 : 288|8@1+ (1,0) [0|255] "" Vector__XXX
 SG_ SupportTSC1CtrlPurposeGroup1 : 280|8@1+ (1,0) [0|255] "" Vector__XXX
 SG_ SupportVariableRateTSC1Message : 272|8@1+ (1,0) [0|255] "" Vector__XXX
 SG_ EngDefaultTorqueLimit : 256|16@1+ (1,0) [0|64255] "Nm" Vector__XXX
 SG_ EngMomentOfInertia : 240|16@1+ (0.004,0) [0|257.02] "kg-m²" Vector__XXX
 SG_ EngExRngRqdSpdCtrlRngUpperLimit : 224|16@1+ (0.125,0) [0|8031.875] "rpm" Vector__XXX
 SG_ EngRqdTorqueCtrlRangeUpperLimit : 216|8@1+ (1,-125) [-125|125] "%" Vector__XXX
 SG_ EngRqdTorqueCtrlRangeLowerLimit : 208|8@1+ (1,-125) [-125|125] "%" Vector__XXX
 SG_ EngRqedSpeedCtrlRangeUpperLimit : 200|8@1+ (10,0) [0|2500] "rpm" Vector__XXX
 SG_ EngRqedSpeedCtrlRangeLowerLimit : 192|8@1+ (10,0) [0|2500] "rpm" Vector__XXX
 SG_ EngMxMomentaryOverrideTimeLimit : 184|8@1+ (0.1,0) [0|25] "s" Vector__XXX
 SG_ EngMxMmntaryOverrideSpeedPoint7 : 168|16@1+ (0.125,0) [0|8031.875] "rpm" Vector__XXX
 SG_ EngReferenceTorque : 152|16@1+ (1,0) [0|64255] "Nm" Vector__XXX
 SG_ EngSpeedAtHighIdlePoint6 : 120|16@1+ (0.125,0) [0|8031.875] "rpm" Vector__XXX
 SG_ EngGainOfEndspeedGovernor : 136|16@1+ (0.00078125,0) [0|50.2] "%/rpm" Vector__XXX
 SG_ EngPercentTorqueAtPoint5 : 112|8@1+ (1,-125) [-125|125] "%" Vector__XXX
 SG_ EngSpeedAtPoint5 : 96|16@1+ (0.125,0) [0|8031.875] "rpm" Vector__XXX
 SG_ EngPercentTorqueAtPoint4 : 88|8@1+ (1,-125) [-125|125] "%" Vector__XXX
 SG_ EngSpeedAtPoint4 : 72|16@1+ (0.125,0) [0|8031.875] "rpm" Vector__XXX
 SG_ EngPercentTorqueAtPoint3 : 64|8@1+ (1,-125) [-125|125] "%" Vector__XXX
 SG_ EngSpeedAtPoint3 : 48|16@1+ (0.125,0) [0|8031.875] "rpm" Vector__XXX
 SG_ EngPercentTorqueAtPoint2 : 40|8@1+ (1,-125) [-125|125] "%" Vector__XXX
 SG_ EngSpeedAtPoint2 : 24|16@1+ (0.125,0) [0|8031.875] "rpm" Vector__XXX
 SG_ EngPercentTorqueAtIdlePoint1 : 16|8@1+ (1,-125) [-125|125] "%" Vector__XXX
 SG_ EngSpeedAtIdlePoint1 : 0|16@1+ (0.125,0) [0|8031.875] "rpm" Vector__XXX

BO_ 2566834947 DM2_SA_03: 54 Vector__XXX
 SG_ DM2_SPNConversionMethod_DTC1 : 47|1@1+ (1,0) [0|1] "" Vector__XXX
 SG_ DM2_SPNConversionMethod_DTC2 : 79|1@1+ (1,0) [0|1] "" Vector__XXX
 SG_ DM2_SPNConversionMethod_DTC3 : 111|1@1+ (1,0) [0|1] "" Vector__XXX
 SG_ DM2_SPNConversionMethod_DTC4 : 143|1@1+ (1,0) [0|1] "" Vector__XXX
 SG_ DM2_SPNConversionMethod_DTC5 : 175|1@1+ (1,0) [0|1] "" Vector__XXX
 SG_ DM2_SPNConversionMethod_DTC6 : 207|1@1+ (1,0) [0|1] "" Vector__XXX
 SG_ DM2_SPNConversionMethod_DTC7 : 239|1@1+ (1,0) [0|1] "" Vector__XXX
 SG_ DM2_SPNConversionMethod_DTC8 : 271|1@1+ (1,0) [0|1] "" Vector__XXX
 SG_ DM2_OccurenceCount_DTC8 : 264|7@1+ (1,0) [0|126] "" Vector__XXX
 SG_ DM2_OccurenceCount_DTC7 : 232|7@1+ (1,0) [0|126] "" Vector__XXX
 SG_ DM2_OccurenceCount_DTC6 : 200|7@1+ (1,0) [0|126] "" Vector__XXX
 SG_ DM2_OccurenceCount_DTC5 : 168|7@1+ (1,0) [0|126] "" Vector__XXX
 SG_ DM2_OccurenceCount_DTC4 : 136|7@1+ (1,0) [0|126] "" Vector__XXX
 SG_ DM2_OccurenceCount_DTC3 : 104|7@1+ (1,0) [0|126] "" Vector__XXX
 SG_ DM2_OccurenceCount_DTC2 : 72|7@1+ (1,0) [0|126] "" Vector__XXX
 SG_ DM2_OccurenceCount_DTC1 : 40|7@1+ (1,0) [0|126] "" Vector__XXX
 SG_ DM2_FMI_DTC8 : 256|5@1+ (1,0) [0|32] "" Vector__XXX
 SG_ DM2_FMI_DTC7 : 224|5@1+ (1,0) [0|32] "" Vector__XXX
 SG_ DM2_FMI_DTC6 : 192|5@1+ (1,0) [0|32] "" Vector__XXX
 SG_ DM2_FMI_DTC5 : 160|5@1+ (1,0) [0|32] "" Vector__XXX
 SG_ DM2_FMI_DTC4 : 128|5@1+ (1,0) [0|32] "" Vector__XXX
 SG_ DM2_FMI_DTC3 : 96|5@1+ (1,0) [0|32] "" Vector__XXX
 SG_ DM2_FMI_DTC2 : 64|5@1+ (1,0) [0|32] "" Vector__XXX
 SG_ DM2_FMI_DTC1 : 32|5@1+ (1,0) [0|32] "" Vector__XXX
 SG_ DM2_SPN1_DTC8 : 240|8@1+ (1,0) [0|255] "" Vector__XXX
 SG_ DM2_SPN3_DTC8 : 261|3@1+ (1,0) [0|7] "" Vector__XXX
 SG_ DM2_SPN3_DTC7 : 229|3@1+ (1,0) [0|7] "" Vector__XXX
 SG_ DM2_SPN3_DTC6 : 197|3@1+ (1,0) [0|7] "" Vector__XXX
 SG_ DM2_SPN3_DTC5 : 165|3@1+ (1,0) [0|7] "" Vector__XXX
 SG_ DM2_SPN3_DTC4 : 133|3@1+ (1,0) [0|7] "" Vector__XXX
 SG_ DM2_SPN3_DTC3 : 101|3@1+ (1,0) [0|7] "" Vector__XXX
 SG_ DM2_SPN3_DTC2 : 69|3@1+ (1,0) [0|7] "" Vector__XXX
 SG_ DM2_SPN3_DTC1 : 37|3@1+ (1,0) [0|7] "" Vector__XXX
 SG_ DM2_SPN2_DTC8 : 248|8@1+ (1,0) [0|255] "" Vector__XXX
 SG_ DM2_SPN2_DTC7 : 216|8@1+ (1,0) [0|255] "" Vector__XXX
 SG_ DM2_SPN2_DTC6 : 184|8@1+ (1,0) [0|255] "" Vector__XXX
 SG_ DM2_SPN2_DTC5 : 152|8@1+ (1,0) [0|255] "" Vector__XXX
 SG_ DM2_SPN2_DTC4 : 120|8@1+ (1,0) [0|255] "" Vector__XXX
 SG_ DM2_SPN2_DTC3 : 88|8@1+ (1,0) [0|255] "" Vector__XXX
 SG_ DM2_SPN2_DTC2 : 56|8@1+ (1,0) [0|255] "" Vector__XXX
 SG_ DM2_SPN2_DTC1 : 24|8@1+ (1,0) [0|255] "" Vector__XXX
 SG_ DM2_SPN1_DTC5 : 144|8@1+ (1,0) [0|255] "" Vector__XXX
 SG_ DM2_SPN1_DTC6 : 176|8@1+ (1,0) [0|255] "" Vector__XXX
 SG_ DM2_SPN1_DTC7 : 208|8@1+ (1,0) [0|255] "" Vector__XXX
 SG_ DM2_SPN1_DTC2 : 48|8@1+ (1,0) [0|255] "" Vector__XXX
 SG_ DM2_SPN1_DTC4 : 112|8@1+ (1,0) [0|255] "" Vector__XXX
 SG_ DM2_SPN1_DTC3 : 80|8@1+ (1,0) [0|255] "" Vector__XXX
 SG_ DM2_SPN1_DTC1 : 16|8@1+ (1,0) [0|255] "" Vector__XXX
 SG_ DM2FlashRedStopLamp : 12|2@1+ (1,0) [0|3] "" Vector__XXX
 SG_ DM2FlashProtectLamp : 8|2@1+ (1,0) [0|3] "" Vector__XXX
 SG_ DM2FlashMalfuncIndicatorLamp : 14|2@1+ (1,0) [0|3] "" Vector__XXX
 SG_ DM2FlashAmberWarningLamp : 10|2@1+ (1,0) [0|3] "" Vector__XXX
 SG_ DM2MalfunctionIndicatorLampState : 6|2@1+ (1,0) [0|3] "" Vector__XXX
 SG_ DM2AmberWarningLampStatus : 2|2@1+ (1,0) [0|3] "" Vector__XXX
 SG_ DM2RedStopLampState : 4|2@1+ (1,0) [0|3] "" Vector__XXX
 SG_ DM2ProtectLampStatus : 0|2@1+ (1,0) [0|3] "" Vector__XXX

BO_ 2566834691 DM1_SA_03: 54 Vector__XXX
 SG_ SPNConversionMethod_DTC1 : 47|1@1+ (1,0) [0|1] "" Vector__XXX
 SG_ SPNConversionMethod_DTC2 : 79|1@1+ (1,0) [0|1] "" Vector__XXX
 SG_ SPNConversionMethod_DTC3 : 111|1@1+ (1,0) [0|1] "" Vector__XXX
 SG_ SPNConversionMethod_DTC4 : 143|1@1+ (1,0) [0|1] "" Vector__XXX
 SG_ SPNConversionMethod_DTC5 : 175|1@1+ (1,0) [0|1] "" Vector__XXX
 SG_ SPNConversionMethod_DTC6 : 207|1@1+ (1,0) [0|1] "" Vector__XXX
 SG_ SPNConversionMethod_DTC7 : 239|1@1+ (1,0) [0|1] "" Vector__XXX
 SG_ SPNConversionMethod_DTC8 : 271|1@1+ (1,0) [0|1] "" Vector__XXX
 SG_ OccurenceCount_DTC8 : 264|7@1+ (1,0) [0|126] "" Vector__XXX
 SG_ OccurenceCount_DTC7 : 232|7@1+ (1,0) [0|126] "" Vector__XXX
 SG_ OccurenceCount_DTC6 : 200|7@1+ (1,0) [0|126] "" Vector__XXX
 SG_ OccurenceCount_DTC5 : 168|7@1+ (1,0) [0|126] "" Vector__XXX
 SG_ OccurenceCount_DTC4 : 136|7@1+ (1,0) [0|126] "" Vector__XXX
 SG_ OccurenceCount_DTC3 : 104|7@1+ (1,0) [0|126] "" Vector__XXX
 SG_ OccurenceCount_DTC2 : 72|7@1+ (1,0) [0|126] "" Vector__XXX
 SG_ OccurenceCount_DTC1 : 40|7@1+ (1,0) [0|126] "" Vector__XXX
 SG_ FMI_DTC8 : 256|5@1+ (1,0) [0|32] "" Vector__XXX
 SG_ FMI_DTC7 : 224|5@1+ (1,0) [0|32] "" Vector__XXX
 SG_ FMI_DTC6 : 192|5@1+ (1,0) [0|32] "" Vector__XXX
 SG_ FMI_DTC5 : 160|5@1+ (1,0) [0|32] "" Vector__XXX
 SG_ FMI_DTC4 : 128|5@1+ (1,0) [0|32] "" Vector__XXX
 SG_ FMI_DTC3 : 96|5@1+ (1,0) [0|32] "" Vector__XXX
 SG_ FMI_DTC2 : 64|5@1+ (1,0) [0|32] "" Vector__XXX
 SG_ FMI_DTC1 : 32|5@1+ (1,0) [0|32] "" Vector__XXX
 SG_ SPN1_DTC8 : 240|8@1+ (1,0) [0|255] "" Vector__XXX
 SG_ SPN3_DTC8 : 261|3@1+ (1,0) [0|7] "" Vector__XXX
 SG_ SPN3_DTC7 : 229|3@1+ (1,0) [0|7] "" Vector__XXX
 SG_ SPN3_DTC6 : 197|3@1+ (1,0) [0|7] "" Vector__XXX
 SG_ SPN3_DTC5 : 165|3@1+ (1,0) [0|7] "" Vector__XXX
 SG_ SPN3_DTC4 : 133|3@1+ (1,0) [0|7] "" Vector__XXX
 SG_ SPN3_DTC3 : 101|3@1+ (1,0) [0|7] "" Vector__XXX
 SG_ SPN3_DTC2 : 69|3@1+ (1,0) [0|7] "" Vector__XXX
 SG_ SPN3_DTC1 : 37|3@1+ (1,0) [0|7] "" Vector__XXX
 SG_ SPN2_DTC8 : 248|8@1+ (1,0) [0|255] "" Vector__XXX
 SG_ SPN2_DTC7 : 216|8@1+ (1,0) [0|255] "" Vector__XXX
 SG_ SPN2_DTC6 : 184|8@1+ (1,0) [0|255] "" Vector__XXX
 SG_ SPN2_DTC5 : 152|8@1+ (1,0) [0|255] "" Vector__XXX
 SG_ SPN2_DTC4 : 120|8@1+ (1,0) [0|255] "" Vector__XXX
 SG_ SPN2_DTC3 : 88|8@1+ (1,0) [0|255] "" Vector__XXX
 SG_ SPN2_DTC2 : 56|8@1+ (1,0) [0|255] "" Vector__XXX
 SG_ SPN2_DTC1 : 24|8@1+ (1,0) [0|255] "" Vector__XXX
 SG_ SPN1_DTC5 : 144|8@1+ (1,0) [0|255] "" Vector__XXX
 SG_ SPN1_DTC6 : 176|8@1+ (1,0) [0|255] "" Vector__XXX
 SG_ SPN1_DTC7 : 208|8@1+ (1,0) [0|255] "" Vector__XXX
 SG_ SPN1_DTC2 : 48|8@1+ (1,0) [0|255] "" Vector__XXX
 SG_ SPN1_DTC4 : 112|8@1+ (1,0) [0|255] "" Vector__XXX
 SG_ SPN1_DTC3 : 80|8@1+ (1,0) [0|255] "" Vector__XXX
 SG_ SPN1_DTC1 : 16|8@1+ (1,0) [0|1E+017] "" Vector__XXX
 SG_ FlashRedStopLamp : 12|2@1+ (1,0) [0|3] "" Vector__XXX
 SG_ FlashProtectLamp : 8|2@1+ (1,0) [0|3] "" Vector__XXX
 SG_ FlashMalfuncIndicatorLamp : 14|2@1+ (1,0) [0|3] "" Vector__XXX
 SG_ FlashAmberWarningLamp : 10|2@1+ (1,0) [0|3] "" Vector__XXX
 SG_ MalfunctionIndicatorLampState : 6|2@1+ (1,0) [0|3] "" Vector__XXX
 SG_ AmberWarningLampStatus : 2|2@1+ (1,0) [0|3] "" Vector__XXX
 SG_ RedStopLampState : 4|2@1+ (1,0) [0|3] "" Vector__XXX
 SG_ ProtectLampStatus : 0|2@1+ (1,0) [0|3] "" Vector__XXX

BO_ 2566834688 DM1_SA_00: 22 Vector__XXX
 SG_ DTC5 : 144|32@1+ (1,0) [0|4294967295] "" Vector__XXX
 SG_ DTC1 : 16|32@1+ (1,0) [0|4294967295] "" Vector__XXX
 SG_ FlashRedStopLamp : 12|2@1+ (1,0) [0|3] "" Vector__XXX
 SG_ FlashProtectLamp : 8|2@1+ (1,0) [0|3] "" Vector__XXX
 SG_ FlashMalfuncIndicatorLamp : 14|2@1+ (1,0) [0|3] "" Vector__XXX
 SG_ FlashAmberWarningLamp : 10|2@1+ (1,0) [0|3] "" Vector__XXX
 SG_ MalfunctionIndicatorLampStatus : 6|2@1+ (1,0) [0|3] "" Vector__XXX
 SG_ AmberWarningLampStatus : 2|2@1+ (1,0) [0|3] "" Vector__XXX
 SG_ RedStopLampState : 4|2@1+ (1,0) [0|3] "" Vector__XXX
 SG_ ProtectLampStatus : 0|2@1+ (1,0) [0|3] "" Vector__XXX
 SG_ DTC4 : 112|32@1+ (1,0) [0|4294967295] "" Vector__XXX
 SG_ DTC3 : 80|32@1+ (1,0) [0|4294967295] "" Vector__XXX
 SG_ DTC2 : 48|32@1+ (1,0) [0|4294967295] "" Vector__XXX

BO_ 2164211715 CEC_SA_03: 6 Vector__XXX
 SG_ Grade : 32|16@1+ (0.1,-100) [0|0] "%" Vector__XXX
 SG_ GrossCombinationWeight : 8|24@1+ (2,0) [0|32899070] "kg" Vector__XXX
 SG_ CoastModeStatus : 6|2@1+ (1,0) [0|0] "" Vector__XXX
 SG_ TransmissionType : 2|4@1+ (1,0) [0|0] "" Vector__XXX
 SG_ Disable_VGT_Braking : 0|2@1+ (1,0) [0|0] "" Vector__XXX

BO_ 2164151550 CEA: 3 Vector__XXX
 SG_ EngineCoastModeStatus : 16|2@1+ (1,0) [0|0] "" Vector__XXX
 SG_ VehicleAcceleration : 0|16@1+ (0.01,-320) [0|0] "m/s^2" Vector__XXX

BO_ 2566844721 CCVS_SA_31: 8 Vector__XXX
 SG_ ParkBrakeReleaseInhibitRq : 6|2@1+ (1,0) [0|3] "" Vector__XXX
 SG_ PTOGovernorState : 48|5@1+ (1,0) [0|31] "" Vector__XXX
 SG_ EngShutdownOverrideSwitch : 62|2@1+ (1,0) [0|3] "" Vector__XXX
 SG_ EngTestModeSwitch : 60|2@1+ (1,0) [0|3] "" Vector__XXX
 SG_ EngIdleDecrementSwitch : 58|2@1+ (1,0) [0|3] "" Vector__XXX
 SG_ EngIdleIncrementSwitch : 56|2@1+ (1,0) [0|3] "" Vector__XXX
 SG_ CruiseCtrlStates : 53|3@1+ (1,0) [0|7] "" Vector__XXX
 SG_ CruiseCtrlSetSpeed : 40|8@1+ (1,0) [0|250] "km/h" Vector__XXX
 SG_ CruiseCtrlAccelerateSwitch : 38|2@1+ (1,0) [0|3] "" Vector__XXX
 SG_ CruiseCtrlResumeSwitch : 36|2@1+ (1,0) [0|3] "" Vector__XXX
 SG_ CruiseCtrlCoastSwitch : 34|2@1+ (1,0) [0|3] "" Vector__XXX
 SG_ CruiseCtrlSetSwitch : 32|2@1+ (1,0) [0|3] "" Vector__XXX
 SG_ ClutchSwitch : 30|2@1+ (1,0) [0|3] "" Vector__XXX
 SG_ BrakeSwitch_SA31 : 28|2@1+ (1,0) [0|3] "" Vector__XXX
 SG_ CruiseCtrlEnableSwitch : 26|2@1+ (1,0) [0|3] "" Vector__XXX
 SG_ CruiseCtrlActive : 24|2@1+ (1,0) [0|3] "" Vector__XXX
 SG_ WheelBasedVehicleSpeed : 8|16@1+ (0.00390625,0) [0|250.996] "km/h" Vector__XXX
 SG_ CruiseCtrlPauseSwitch : 4|2@1+ (1,0) [0|3] "" Vector__XXX
 SG_ ParkingBrakeSwitch : 2|2@1+ (1,0) [0|3] "" Vector__XXX
 SG_ TwoSpeedAxleSwitch : 0|2@1+ (1,0) [0|3] "" Vector__XXX

BO_ 2566844711 CCVS_SA_27: 8 Vector__XXX
 SG_ ParkBrakeReleaseInhibitRq : 6|2@1+ (1,0) [0|3] "" Vector__XXX
 SG_ PTOGovernorState : 48|5@1+ (1,0) [0|31] "" Vector__XXX
 SG_ EngShutdownOverrideSwitch : 62|2@1+ (1,0) [0|3] "" Vector__XXX
 SG_ EngTestModeSwitch : 60|2@1+ (1,0) [0|3] "" Vector__XXX
 SG_ EngIdleDecrementSwitch : 58|2@1+ (1,0) [0|3] "" Vector__XXX
 SG_ EngIdleIncrementSwitch : 56|2@1+ (1,0) [0|3] "" Vector__XXX
 SG_ CruiseCtrlStates : 53|3@1+ (1,0) [0|7] "" Vector__XXX
 SG_ CruiseCtrlSetSpeed : 40|8@1+ (1,0) [0|250] "km/h" Vector__XXX
 SG_ CruiseCtrlAccelerateSwitch : 38|2@1+ (1,0) [0|3] "" Vector__XXX
 SG_ CruiseCtrlResumeSwitch : 36|2@1+ (1,0) [0|3] "" Vector__XXX
 SG_ CruiseCtrlCoastSwitch : 34|2@1+ (1,0) [0|3] "" Vector__XXX
 SG_ CruiseCtrlSetSwitch : 32|2@1+ (1,0) [0|3] "" Vector__XXX
 SG_ ClutchSwitch : 30|2@1+ (1,0) [0|3] "" Vector__XXX
 SG_ BrakeSwitch_SA27 : 28|2@1+ (1,0) [0|3] "" Vector__XXX
 SG_ CruiseCtrlEnableSwitch : 26|2@1+ (1,0) [0|3] "" Vector__XXX
 SG_ CruiseCtrlActive : 24|2@1+ (1,0) [0|3] "" Vector__XXX
 SG_ WheelBasedVehicleSpeed : 8|16@1+ (0.00390625,0) [0|250.996] "km/h" Vector__XXX
 SG_ CruiseCtrlPauseSwitch : 4|2@1+ (1,0) [0|3] "" Vector__XXX
 SG_ ParkingBrakeSwitch : 2|2@1+ (1,0) [0|3] "" Vector__XXX
 SG_ TwoSpeedAxleSwitch : 0|2@1+ (1,0) [0|3] "" Vector__XXX

CM_ BO_ 3221225472 "This is a message for not used signals, created by Vector CANdb++ DBC OLE DB Provider.";
CM_ SG_ 3221225472 TrailerWeight "Total mass of freight-carrying vehicle designed to be pulled by truck, including the weight of the contents.";
CM_ SG_ 3221225472 ReferenceTirePressSetting "Reference value of the tire pressure setting as basis for the tire pressure monitoring";
CM_ SG_ 3221225472 ReferenceTirePress "Reference value of the tire pressure as basis for the tire pressure monitoring";
CM_ SG_ 3221225472 TirePressThresholdDetection "Signal indicating the pressure level of the tire.";
CM_ SG_ 3221225472 TireAirLeakageRate "The pressure loss rate of a tire.";
CM_ SG_ 3221225472 CTIWheelEndElectricalFault "Indicates the status of electrical fault on CTI wheel interface.";
CM_ SG_ 3221225472 CTITireStatus "Indicates the status of the tire.";
CM_ SG_ 3221225472 CTIWheelSensorStatus "Indicates whether the wheel is being monitored by the CTI controller.";
CM_ SG_ 3221225472 TireTemp "Temperature at the surface of the tire sidewall.";
CM_ SG_ 3221225472 TirePress "Pressure at which air is contained in cavity formed by tire and rim.";
CM_ SG_ 3221225472 DTC2 "Diagnostic Trouble Code";
CM_ SG_ 3221225472 DTC3 "Diagnostic Trouble Code";
CM_ SG_ 3221225472 DTC4 "Diagnostic Trouble Code";
CM_ SG_ 3221225472 SPNConversionMethod_DTC2 "Diagnostic Trouble Code";
CM_ SG_ 3221225472 FMI_DTC6 "Diagnostic Trouble Code";
CM_ SG_ 3221225472 SPNConversionMethod_DTC7 "Diagnostic Trouble Code";
CM_ SG_ 3221225472 SPN3_DTC7 "Diagnostic Trouble Code";
CM_ BO_ 2565935153 "Brakes";
CM_ SG_ 2565935153 BrakeSwitch2 "Switch signal which indicates that the driver operated brake foot pedal is being pressed.";
CM_ SG_ 2565935153 DemandedBrakeApplicationPressure "Gage pressure of the compressed air or fluid in the vehicle braking system that is used to apply brake shoes (or pads) against the brake drums (or discs).";
CM_ BO_ 2565935127 "Brakes";
CM_ SG_ 2565935127 BrakeSwitch2 "Switch signal which indicates that the driver operated brake foot pedal is being pressed.";
CM_ SG_ 2565935127 DemandedBrakeApplicationPressure "Gage pressure of the compressed air or fluid in the vehicle braking system that is used to apply brake shoes (or pads) against the brake drums (or discs).";
CM_ BO_ 2565935121 "Brakes";
CM_ SG_ 2565935121 BrakeSwitch2 "Switch signal which indicates that the driver operated brake foot pedal is being pressed.";
CM_ SG_ 2565935121 DemandedBrakeApplicationPressure "Gage pressure of the compressed air or fluid in the vehicle braking system that is used to apply brake shoes (or pads) against the brake drums (or discs).";
CM_ BO_ 2565935115 "Brakes";
CM_ SG_ 2565935115 BrakeSwitch2 "Switch signal which indicates that the driver operated brake foot pedal is being pressed.";
CM_ SG_ 2565935115 DemandedBrakeApplicationPressure "Gage pressure of the compressed air or fluid in the vehicle braking system that is used to apply brake shoes (or pads) against the brake drums (or discs).";
CM_ BO_ 2565935104 "Brakes";
CM_ SG_ 2565935104 BrakeSwitch2 "Switch signal which indicates that the driver operated brake foot pedal is being pressed.";
CM_ SG_ 2565935104 DemandedBrakeApplicationPressure "Gage pressure of the compressed air or fluid in the vehicle braking system that is used to apply brake shoes (or pads) against the brake drums (or discs).";
CM_ BO_ 2566705667 "Active diagnostic trouble codes";
CM_ SG_ 2566705667 DM54_SPNConversionMethod_DTC8 "Diagnostic Trouble Code";
CM_ SG_ 2566705667 DM54_OccurenceCount_DTC8 "The 7 bit occurence count field contains the number of times a fault has gone from active to previously active.";
CM_ SG_ 2566705667 DM54_SPN3_DTC8 "SPN, 3 most significant bits";
CM_ SG_ 2566705667 DM54_FMI_DTC8 "The FMI defines the type of failure detected in the subsystem identified by an SPN.";
CM_ SG_ 2566705667 DM54_SPN2_DTC8 "SPN, second byte of SPN";
CM_ SG_ 2566705667 DM54_SPN1_DTC8 "SPN, 8 least significant bits";
CM_ SG_ 2566705667 DM54_SPNConversionMethod_DTC7 "Diagnostic Trouble Code";
CM_ SG_ 2566705667 DM54_OccurenceCount_DTC7 "The 7 bit occurence count field contains the number of times a fault has gone from active to previously active.";
CM_ SG_ 2566705667 DM54_SPN3_DTC7 "SPN, 3 most significant bits";
CM_ SG_ 2566705667 DM54_FMI_DTC7 "The FMI defines the type of failure detected in the subsystem identified by an SPN.";
CM_ SG_ 2566705667 DM54_SPN2_DTC7 "SPN, second byte of SPN";
CM_ SG_ 2566705667 DM54_SPN1_DTC7 "SPN, 8 least significant bits";
CM_ SG_ 2566705667 DM54_SPNConversionMethod_DTC6 "Diagnostic Trouble Code";
CM_ SG_ 2566705667 DM54_OccurenceCount_DTC6 "The 7 bit occurence count field contains the number of times a fault has gone from active to previously active.";
CM_ SG_ 2566705667 DM54_SPN3_DTC6 "SPN, 3 most significant bits";
CM_ SG_ 2566705667 DM54_FMI_DTC6 "The FMI defines the type of failure detected in the subsystem identified by an SPN.";
CM_ SG_ 2566705667 DM54_SPN2_DTC6 "SPN, second byte of SPN";
CM_ SG_ 2566705667 DM54_SPN1_DTC6 "SPN, 8 least significant bits";
CM_ SG_ 2566705667 DM54_SPNConversionMethod_DTC5 "Diagnostic Trouble Code";
CM_ SG_ 2566705667 DM54_OccurenceCount_DTC5 "The 7 bit occurence count field contains the number of times a fault has gone from active to previously active.";
CM_ SG_ 2566705667 DM54_SPN3_DTC5 "SPN, 3 most significant bits";
CM_ SG_ 2566705667 DM54_FMI_DTC5 "The FMI defines the type of failure detected in the subsystem identified by an SPN.";
CM_ SG_ 2566705667 DM54_SPN2_DTC5 "SPN, second byte of SPN";
CM_ SG_ 2566705667 DM54_SPN1_DTC5 "SPN, 8 least significant bits";
CM_ SG_ 2566705667 DM54_SPNConversionMethod_DTC4 "Diagnostic Trouble Code";
CM_ SG_ 2566705667 DM54_OccurenceCount_DTC4 "The 7 bit occurence count field contains the number of times a fault has gone from active to previously active.";
CM_ SG_ 2566705667 DM54_SPN3_DTC4 "SPN, 3 most significant bits";
CM_ SG_ 2566705667 DM54_FMI_DTC4 "The FMI defines the type of failure detected in the subsystem identified by an SPN.";
CM_ SG_ 2566705667 DM54_SPN2_DTC4 "SPN, second byte of SPN";
CM_ SG_ 2566705667 DM54_SPN1_DTC4 "SPN, 8 least significant bits";
CM_ SG_ 2566705667 DM54_SPNConversionMethod_DTC3 "Diagnostic Trouble Code";
CM_ SG_ 2566705667 DM54_OccurenceCount_DTC3 "The 7 bit occurence count field contains the number of times a fault has gone from active to previously active.";
CM_ SG_ 2566705667 DM54_SPN3_DTC3 "SPN, 3 most significant bits";
CM_ SG_ 2566705667 DM54_FMI_DTC3 "The FMI defines the type of failure detected in the subsystem identified by an SPN.";
CM_ SG_ 2566705667 DM54_SPN2_DTC3 "SPN, second byte of SPN";
CM_ SG_ 2566705667 DM54_SPN1_DTC3 "SPN, 8 least significant bits";
CM_ SG_ 2566705667 DM54_SPNConversionMethod_DTC2 "Diagnostic Trouble Code";
CM_ SG_ 2566705667 DM54_OccurenceCount_DTC2 "The 7 bit occurence count field contains the number of times a fault has gone from active to previously active.";
CM_ SG_ 2566705667 DM54_SPN3_DTC2 "SPN, 3 most significant bits";
CM_ SG_ 2566705667 DM54_FMI_DTC2 "The FMI defines the type of failure detected in the subsystem identified by an SPN.";
CM_ SG_ 2566705667 DM54_SPN2_DTC2 "SPN, second byte of SPN";
CM_ SG_ 2566705667 DM54_SPN1_DTC2 "SPN, 8 least significant bits";
CM_ SG_ 2566705667 DM54_SPNConversionMethod_DTC1 "Diagnostic Trouble Code";
CM_ SG_ 2566705667 DM54_OccurenceCount_DTC1 "The 7 bit occurence count field contains the number of times a fault has gone from active to previously active.";
CM_ SG_ 2566705667 DM54_SPN3_DTC1 "SPN, 3 most significant bits";
CM_ SG_ 2566705667 DM54_FMI_DTC1 "The FMI defines the type of failure detected in the subsystem identified by an SPN.";
CM_ SG_ 2566705667 DM54_SPN2_DTC1 "SPN, second byte of SPN";
CM_ SG_ 2566705667 DM54_SPN1_DTC1 "SPN, 8 least significant bits";
CM_ SG_ 2566705667 DM54FlashMalfuncIndicatorLamp "This parameter provides the capability to flash the MIL (SPN 3038).";
CM_ SG_ 2566705667 DM54FlashRedStopLamp "This parameter provides the capability to flash the RSL (SPN 3039).";
CM_ SG_ 2566705667 DM54FlashAmberWarningLamp "This parameter provides the capability to flash the AWL (SPN 3040). ";
CM_ SG_ 2566705667 DM54FlashProtectLamp "This parameter provides the capability to flash the engine protect lamp (SPN 3041).";
CM_ SG_ 2566705667 DM54MalfunctionIndicateLampState "A lamp used to relay only emissions-related trouble code information.";
CM_ SG_ 2566705667 DM54RedStopLampState "This lamp is uesed to relay trouble code information that is of a severe enought condition that it warrants stopping the vehicle.";
CM_ SG_ 2566705667 DM54AmberWarningLampStatus "This lamp is used to relay trouble code information that is reporting a problem with the vehicle system but the vehicle need
not be immediately stopped.";
CM_ SG_ 2566705667 DM54ProtectLampStatus "This lamp is used to relay trouble code informatio that is reporting a problem with a vehicle system that is most
probably not electronic subsystem related.";
CM_ BO_ 2566705411 "Active diagnostic trouble codes";
CM_ SG_ 2566705411 DM53_SPNConversionMethod_DTC8 "Diagnostic Trouble Code";
CM_ SG_ 2566705411 DM53_OccurenceCount_DTC8 "The 7 bit occurence count field contains the number of times a fault has gone from active to previously active.";
CM_ SG_ 2566705411 DM53_SPN3_DTC8 "SPN, 3 most significant bits";
CM_ SG_ 2566705411 DM53_FMI_DTC8 "The FMI defines the type of failure detected in the subsystem identified by an SPN.";
CM_ SG_ 2566705411 DM53_SPN2_DTC8 "SPN, second byte of SPN";
CM_ SG_ 2566705411 DM53_SPN1_DTC8 "SPN, 8 least significant bits";
CM_ SG_ 2566705411 DM53_SPNConversionMethod_DTC7 "Diagnostic Trouble Code";
CM_ SG_ 2566705411 DM53_OccurenceCount_DTC7 "The 7 bit occurence count field contains the number of times a fault has gone from active to previously active.";
CM_ SG_ 2566705411 DM53_SPN3_DTC7 "SPN, 3 most significant bits";
CM_ SG_ 2566705411 DM53_FMI_DTC7 "The FMI defines the type of failure detected in the subsystem identified by an SPN.";
CM_ SG_ 2566705411 DM53_SPN2_DTC7 "SPN, second byte of SPN";
CM_ SG_ 2566705411 DM53_SPN1_DTC7 "SPN, 8 least significant bits";
CM_ SG_ 2566705411 DM53_SPNConversionMethod_DTC6 "Diagnostic Trouble Code";
CM_ SG_ 2566705411 DM53_OccurenceCount_DTC6 "The 7 bit occurence count field contains the number of times a fault has gone from active to previously active.";
CM_ SG_ 2566705411 DM53_SPN3_DTC6 "SPN, 3 most significant bits";
CM_ SG_ 2566705411 DM53_FMI_DTC6 "The FMI defines the type of failure detected in the subsystem identified by an SPN.";
CM_ SG_ 2566705411 DM53_SPN2_DTC6 "SPN, second byte of SPN";
CM_ SG_ 2566705411 DM53_SPN1_DTC6 "SPN, 8 least significant bits";
CM_ SG_ 2566705411 DM53_SPNConversionMethod_DTC5 "Diagnostic Trouble Code";
CM_ SG_ 2566705411 DM53_OccurenceCount_DTC5 "The 7 bit occurence count field contains the number of times a fault has gone from active to previously active.";
CM_ SG_ 2566705411 DM53_SPN3_DTC5 "SPN, 3 most significant bits";
CM_ SG_ 2566705411 DM53_FMI_DTC5 "The FMI defines the type of failure detected in the subsystem identified by an SPN.";
CM_ SG_ 2566705411 DM53_SPN2_DTC5 "SPN, second byte of SPN";
CM_ SG_ 2566705411 DM53_SPN1_DTC5 "SPN, 8 least significant bits";
CM_ SG_ 2566705411 DM53_SPNConversionMethod_DTC4 "Diagnostic Trouble Code";
CM_ SG_ 2566705411 DM53_OccurenceCount_DTC4 "The 7 bit occurence count field contains the number of times a fault has gone from active to previously active.";
CM_ SG_ 2566705411 DM53_SPN3_DTC4 "SPN, 3 most significant bits";
CM_ SG_ 2566705411 DM53_FMI_DTC4 "The FMI defines the type of failure detected in the subsystem identified by an SPN.";
CM_ SG_ 2566705411 DM53_SPN2_DTC4 "SPN, second byte of SPN";
CM_ SG_ 2566705411 DM53_SPN1_DTC4 "SPN, 8 least significant bits";
CM_ SG_ 2566705411 DM53_SPNConversionMethod_DTC3 "Diagnostic Trouble Code";
CM_ SG_ 2566705411 DM53_OccurenceCount_DTC3 "The 7 bit occurence count field contains the number of times a fault has gone from active to previously active.";
CM_ SG_ 2566705411 DM53_SPN3_DTC3 "SPN, 3 most significant bits";
CM_ SG_ 2566705411 DM53_FMI_DTC3 "The FMI defines the type of failure detected in the subsystem identified by an SPN.";
CM_ SG_ 2566705411 DM53_SPN2_DTC3 "SPN, second byte of SPN";
CM_ SG_ 2566705411 DM53_SPN1_DTC3 "SPN, 8 least significant bits";
CM_ SG_ 2566705411 DM53_SPNConversionMethod_DTC2 "Diagnostic Trouble Code";
CM_ SG_ 2566705411 DM53_OccurenceCount_DTC2 "The 7 bit occurence count field contains the number of times a fault has gone from active to previously active.";
CM_ SG_ 2566705411 DM53_SPN3_DTC2 "SPN, 3 most significant bits";
CM_ SG_ 2566705411 DM53_FMI_DTC2 "The FMI defines the type of failure detected in the subsystem identified by an SPN.";
CM_ SG_ 2566705411 DM53_SPN2_DTC2 "SPN, second byte of SPN";
CM_ SG_ 2566705411 DM53_SPN1_DTC2 "SPN, 8 least significant bits";
CM_ SG_ 2566705411 DM53_SPNConversionMethod_DTC1 "Diagnostic Trouble Code";
CM_ SG_ 2566705411 DM53_OccurenceCount_DTC1 "The 7 bit occurence count field contains the number of times a fault has gone from active to previously active.";
CM_ SG_ 2566705411 DM53_SPN3_DTC1 "SPN, 3 most significant bits";
CM_ SG_ 2566705411 DM53_FMI_DTC1 "The FMI defines the type of failure detected in the subsystem identified by an SPN.";
CM_ SG_ 2566705411 DM53_SPN2_DTC1 "SPN, second byte of SPN";
CM_ SG_ 2566705411 DM53_SPN1_DTC1 "SPN, 8 least significant bits";
CM_ SG_ 2566705411 DM53FlashMalfuncIndicatorLamp "This parameter provides the capability to flash the MIL (SPN 3038).";
CM_ SG_ 2566705411 DM53FlashRedStopLamp "This parameter provides the capability to flash the RSL (SPN 3039).";
CM_ SG_ 2566705411 DM53FlashAmberWarningLamp "This parameter provides the capability to flash the AWL (SPN 3040). ";
CM_ SG_ 2566705411 DM53FlashProtectLamp "This parameter provides the capability to flash the engine protect lamp (SPN 3041).";
CM_ SG_ 2566705411 DM53MalfunctionIndicateLampState "A lamp used to relay only emissions-related trouble code information.";
CM_ SG_ 2566705411 DM53RedStopLampState "This lamp is uesed to relay trouble code information that is of a severe enought condition that it warrants stopping the vehicle.";
CM_ SG_ 2566705411 DM53AmberWarningLampStatus "This lamp is used to relay trouble code information that is reporting a problem with the vehicle system but the vehicle need
not be immediately stopped.";
CM_ SG_ 2566705411 DM53ProtectLampStatus "This lamp is used to relay trouble code informatio that is reporting a problem with a vehicle system that is most
probably not electronic subsystem related.";
CM_ BO_ 2565935358 "Brakes";
CM_ SG_ 2565935358 BrakeSwitch2 "Switch signal which indicates that the driver operated brake foot pedal is being pressed.";
CM_ SG_ 2565935358 DemandedBrakeApplicationPressure "Gage pressure of the compressed air or fluid in the vehicle braking system that is used to apply brake shoes (or pads) against the brake drums (or discs).";
CM_ BO_ 2566847025 "Brakes";
CM_ SG_ 2566847025 ParkingBrakeRedWarningSignal "This parameter commands the Parking Brake red optical warning signal.";
CM_ SG_ 2566847025 ParkBrakeReleaseInhibitStatus "This parameter provides reports on the status of the Park Brake Release Inhibit function.";
CM_ SG_ 2566847025 ParkingBrakeActuator "Signal which indicates the current state of the actuator(s) that control the parking brake (see also SPN 70).";
CM_ SG_ 2566847025 BrakeSecondPress "Gage pressure of air in the secondary, or service side, of the air brake system.";
CM_ SG_ 2566847025 BrakePrimaryPress "Gage pressure of air in the primary, or supply side, of the air brake system.";
CM_ SG_ 2566847025 BrakeAppPress "Gage pressure of compressed air or fluid in vehicle braking system measured at the brake chamber when brake shoe (or";
CM_ BO_ 2566847009 "Brakes";
CM_ SG_ 2566847009 ParkingBrakeRedWarningSignal "This parameter commands the Parking Brake red optical warning signal.";
CM_ SG_ 2566847009 ParkBrakeReleaseInhibitStatus "This parameter provides reports on the status of the Park Brake Release Inhibit function.";
CM_ SG_ 2566847009 ParkingBrakeActuator "Signal which indicates the current state of the actuator(s) that control the parking brake (see also SPN 70).";
CM_ SG_ 2566847009 BrakeSecondPress "Gage pressure of air in the secondary, or service side, of the air brake system.";
CM_ SG_ 2566847009 BrakePrimaryPress "Gage pressure of air in the primary, or supply side, of the air brake system.";
CM_ SG_ 2566847009 BrakeAppPress "Gage pressure of compressed air or fluid in vehicle braking system measured at the brake chamber when brake shoe (or";
CM_ BO_ 2566846999 "Brakes";
CM_ SG_ 2566846999 ParkingBrakeRedWarningSignal "This parameter commands the Parking Brake red optical warning signal.";
CM_ SG_ 2566846999 ParkBrakeReleaseInhibitStatus "This parameter provides reports on the status of the Park Brake Release Inhibit function.";
CM_ SG_ 2566846999 ParkingBrakeActuator "Signal which indicates the current state of the actuator(s) that control the parking brake (see also SPN 70).";
CM_ SG_ 2566846999 BrakeSecondPress "Gage pressure of air in the secondary, or service side, of the air brake system.";
CM_ SG_ 2566846999 BrakePrimaryPress "Gage pressure of air in the primary, or supply side, of the air brake system.";
CM_ SG_ 2566846999 BrakeAppPress "Gage pressure of compressed air or fluid in vehicle braking system measured at the brake chamber when brake shoe (or";
CM_ BO_ 2566846987 "Brakes";
CM_ SG_ 2566846987 ParkingBrakeRedWarningSignal "This parameter commands the Parking Brake red optical warning signal.";
CM_ SG_ 2566846987 ParkBrakeReleaseInhibitStatus "This parameter provides reports on the status of the Park Brake Release Inhibit function.";
CM_ SG_ 2566846987 ParkingBrakeActuator "Signal which indicates the current state of the actuator(s) that control the parking brake (see also SPN 70).";
CM_ SG_ 2566846987 BrakeSecondPress "Gage pressure of air in the secondary, or service side, of the air brake system.";
CM_ SG_ 2566846987 BrakePrimaryPress "Gage pressure of air in the primary, or supply side, of the air brake system.";
CM_ SG_ 2566846987 BrakeAppPress "Gage pressure of compressed air or fluid in vehicle braking system measured at the brake chamber when brake shoe (or";
CM_ BO_ 2566846976 "Brakes";
CM_ SG_ 2566846976 ParkingBrakeRedWarningSignal "This parameter commands the Parking Brake red optical warning signal.";
CM_ SG_ 2566846976 ParkBrakeReleaseInhibitStatus "This parameter provides reports on the status of the Park Brake Release Inhibit function.";
CM_ SG_ 2566846976 ParkingBrakeActuator "Signal which indicates the current state of the actuator(s) that control the parking brake (see also SPN 70).";
CM_ SG_ 2566846976 BrakeSecondPress "Gage pressure of air in the secondary, or service side, of the air brake system.";
CM_ SG_ 2566846976 BrakePrimaryPress "Gage pressure of air in the primary, or supply side, of the air brake system.";
CM_ SG_ 2566846976 BrakeAppPress "Gage pressure of compressed air or fluid in vehicle braking system measured at the brake chamber when brake shoe (or";
CM_ BO_ 2566827569 "Air Supply Pressure";
CM_ SG_ 2566827569 PowertrainCircuitAirSupplyPress "Supply pressure to carry the pressure information for the powertrain circuit. This circuit typically would feed powertrain components such as throttles, gearbox actuators and aftertreatment actuators for EGR and SCR systems.";
CM_ SG_ 2566827569 ServiceBrakeCircuit2AirPress "The pneumatic pressure in the secondary service brake circuit or reservoir, supplying the front axle.";
CM_ SG_ 2566827569 ServiceBrakeCircuit1AirPress "The pneumatic pressure in the primary service brake circuit or reservoir, supplying the rear axle.";
CM_ SG_ 2566827569 AirCompressorStatus "Indicates whether the air compressor is actively compressing air.";
CM_ SG_ 2566827569 AirSuspensionSupplyPress "The pneumatic pressure in the circuit for the electronically controlled air suspension system.";
CM_ SG_ 2566827569 AuxEquipmentSupplyPress "The pneumatic pressure in the auxiliary circuit.";
CM_ SG_ 2566827569 ParkingAnd_OrTrailerAirPress "The pneumatic pressure in the circuit or reservoir for the parking brake and/or the trailer supply.";
CM_ SG_ 2566827569 PneumaticSupplyPress "The pneumatic pressure in the main reservoir, sometimes referred to as the wet tank.";
CM_ BO_ 2432593706 "Adaptive Cruise Control";
CM_ SG_ 2432593706 ForwardCollisionWarning "This parameter indicates if a collision is imminent and strong driver reaction either by braking hard or by an avoidance";
CM_ SG_ 2432593706 ACCDistanceAlertSignal "Signal to indicate to the operator that the ACC system is not able to maintain the distance to the target.";
CM_ SG_ 2432593706 ACCSystemShutoffWarning "Signal to warn the driver of system deactivation due to non-driver actions.";
CM_ SG_ 2432593706 ACCTargetDetected "Signal to indicate to the driver that the ACC system has detected a target.";
CM_ SG_ 2432593706 RoadCurvature "Estimated value of the current road curvature for use by the adaptive cruise control system.";
CM_ SG_ 2432593706 AdptveCruiseCtrlSetDistanceMode "Selected distance mode for adaptive cruise control.";
CM_ SG_ 2432593706 AdaptiveCruiseCtrlMode "This parameter is used to indicate the current state, or mode, of operation by the Adaptive Cruise Control (ACC) device.";
CM_ SG_ 2432593706 AdaptiveCruiseCtrlSetSpeed "Value of the desired (chosen) velocity of the adaptive cruise control system.";
CM_ SG_ 2432593706 DistanceToForwardVehicle "Distance to the preceding vehicle situated within 250 m in the same lane and moving in the same direction.";
CM_ SG_ 2432593706 SpeedOfForwardVehicle "Absolute velocity of the preceding vehicle situated within 250 m in the same lane and moving in the same direction.";
CM_ BO_ 2432593675 "Adaptive Cruise Control";
CM_ SG_ 2432593675 ForwardCollisionWarning "This parameter indicates if a collision is imminent and strong driver reaction either by braking hard or by an avoidance";
CM_ SG_ 2432593675 ACCDistanceAlertSignal "Signal to indicate to the operator that the ACC system is not able to maintain the distance to the target.";
CM_ SG_ 2432593675 ACCSystemShutoffWarning "Signal to warn the driver of system deactivation due to non-driver actions.";
CM_ SG_ 2432593675 ACCTargetDetected "Signal to indicate to the driver that the ACC system has detected a target.";
CM_ SG_ 2432593675 RoadCurvature "Estimated value of the current road curvature for use by the adaptive cruise control system.";
CM_ SG_ 2432593675 AdptveCruiseCtrlSetDistanceMode "Selected distance mode for adaptive cruise control.";
CM_ SG_ 2432593675 AdaptiveCruiseCtrlMode "This parameter is used to indicate the current state, or mode, of operation by the Adaptive Cruise Control (ACC) device.";
CM_ SG_ 2432593675 AdaptiveCruiseCtrlSetSpeed "Value of the desired (chosen) velocity of the adaptive cruise control system.";
CM_ SG_ 2432593675 DistanceToForwardVehicle "Distance to the preceding vehicle situated within 250 m in the same lane and moving in the same direction.";
CM_ SG_ 2432593675 SpeedOfForwardVehicle "Absolute velocity of the preceding vehicle situated within 250 m in the same lane and moving in the same direction.";
CM_ BO_ 2566840617 "Retarder Configuration";
CM_ SG_ 2566840617 PercentTorqueAtPeakTorquePoint5 "The torque limit that indicates the available retarder torque which can be provided by the retarder at point 5 of the retarder";
CM_ SG_ 2566840617 ReferenceRetarderTorque "This parameter is the 100% reference value for all defined indicated retarder torque parameters.";
CM_ SG_ 2566840617 RetarderSpeedAtPeakTorquePoint5 "Please reference PGN 65249";
CM_ SG_ 2566840617 PercentTorqueAtPoint4 "The torque limit that indicates the available retarder torque which can be provided by the retarder at points 3 and 4 of the";
CM_ SG_ 2566840617 RetarderSpeedAtPoint4 "Retarder speed of point 4 of the engine retarder torque map.";
CM_ SG_ 2566840617 PercentTorqueAtPoint3 "The torque limit that indicates the available retarder torque which can be provided by the retarder at points 3 and 4 of the";
CM_ SG_ 2566840617 RetarderSpeedAtPoint3 "Retarder speed of point 3 of the engine retarder torque map.";
CM_ SG_ 2566840617 PercentTorqueAtMaxSpeedPoint2 "The torque limit that indicates the available retarder torque which can be provided by the retarder at its maximum speed.";
CM_ SG_ 2566840617 MaxRetarderSpeedPoint2 "Maximum speed of retarder (Please reference PGN 65249).";
CM_ SG_ 2566840617 PercentTorqueAtIdlePoint1 "The torque limit that indicates the available retarder torque which can be provided by the retarder at idle speed.";
CM_ SG_ 2566840617 RetarderSpeedAtIdlePoint1 "Please reference PGN 65249";
CM_ SG_ 2566840617 RetarderCtrlMethod "This parameter identifies the number of steps used by the retarder.";
CM_ SG_ 2566840617 RetarderLocation "This parameter defines whether the “torque/speed curve” defined by the retarder configuration message (PGN 65249) is";
CM_ SG_ 2566840617 RetarderType "A vehicle retarder is a supplementary device to the wheel brakes for the driver to better control the vehicle.";
CM_ BO_ 2566840591 "Retarder Configuration";
CM_ SG_ 2566840591 PercentTorqueAtPeakTorquePoint5 "The torque limit that indicates the available retarder torque which can be provided by the retarder at point 5 of the retarder";
CM_ SG_ 2566840591 ReferenceRetarderTorque "This parameter is the 100% reference value for all defined indicated retarder torque parameters.";
CM_ SG_ 2566840591 RetarderSpeedAtPeakTorquePoint5 "Please reference PGN 65249";
CM_ SG_ 2566840591 PercentTorqueAtPoint4 "The torque limit that indicates the available retarder torque which can be provided by the retarder at points 3 and 4 of the";
CM_ SG_ 2566840591 RetarderSpeedAtPoint4 "Retarder speed of point 4 of the engine retarder torque map.";
CM_ SG_ 2566840591 PercentTorqueAtPoint3 "The torque limit that indicates the available retarder torque which can be provided by the retarder at points 3 and 4 of the";
CM_ SG_ 2566840591 RetarderSpeedAtPoint3 "Retarder speed of point 3 of the engine retarder torque map.";
CM_ SG_ 2566840591 PercentTorqueAtMaxSpeedPoint2 "The torque limit that indicates the available retarder torque which can be provided by the retarder at its maximum speed.";
CM_ SG_ 2566840591 MaxRetarderSpeedPoint2 "Maximum speed of retarder (Please reference PGN 65249).";
CM_ SG_ 2566840591 PercentTorqueAtIdlePoint1 "The torque limit that indicates the available retarder torque which can be provided by the retarder at idle speed.";
CM_ SG_ 2566840591 RetarderSpeedAtIdlePoint1 "Please reference PGN 65249";
CM_ SG_ 2566840591 RetarderCtrlMethod "This parameter identifies the number of steps used by the retarder.";
CM_ SG_ 2566840591 RetarderLocation "This parameter defines whether the “torque/speed curve” defined by the retarder configuration message (PGN 65249) is";
CM_ SG_ 2566840591 RetarderType "A vehicle retarder is a supplementary device to the wheel brakes for the driver to better control the vehicle.";
CM_ BO_ 2559049726 "Engine State Requests";
CM_ SG_ 2559049726 EngShutdownCommand "Command to shut down the engine. If this parameter is received as 01, then the engine should behave as if the key switch was turned off.";
CM_ SG_ 2559049726 EngineFuelingDesiredReason "This parameter conveys the reason a device wants the engine running.";
CM_ SG_ 2559049726 EngineFuelingNotDesiredReason "This parameter conveys the reason a device wants the engine to inhibit fuelling.";
CM_ SG_ 2559049726 TransIdleGovernorFuelingInhibit "This parameter is a command provided to the Engine Control Module (ECM) from the Transmission Control Module (TCM) to inhibit idle governor fueling in the unlikely event that transmission has detected a failure preventing driveline disengagement.";
CM_ SG_ 2559049726 EngineGaseousFuelSupDesiredPress "Desired gage pressure of gaseous fuel supply to the engine.";
CM_ SG_ 2559049726 RequestedFuelType "Engine controller receives this request from another control module to select the type of fuel to be used for engine operation.";
CM_ SG_ 2559049726 EngineGaseousFuelUsageInhibited "Used to request that the engine should not be allowed to use gaseous fuel for engine cylinder combustion.";
CM_ SG_ 2559049726 DesiredEngineFuelingState "Devices send this request to the engine controller to:

(a) Shut off engine fueling, but remain prepared to re-start quickly by not shutting down the control system, or
(b) Keep the engine running.";
CM_ BO_ 2566759473 "PTO Drive Engagement";
CM_ SG_ 2566759473 EnggmntSttusTransInputShaftPTO1 "Reports if this specific PTO drive is engaged.";
CM_ SG_ 2566759473 EnggmntSttusTransInputShaftPTO2 "Reports if this specific PTO drive is engaged.";
CM_ SG_ 2566759473 EnggmntSttusTransOutputShaftPTO "Reports if this specific PTO drive is engaged.";
CM_ SG_ 2566759473 EnggmntSttsTrnsfrCsOtptShaftPTO "Reports if this specific PTO drive is engaged.";
CM_ SG_ 2566759473 EnggmntCnsntTransInputShaftPTO1 "Status of the transmission controller’s consent to engage the first or sole PTO drive mounted on the transmission case.";
CM_ SG_ 2566759473 EnggmntCnsntTransInputShaftPTO2 "Status of the transmission controller’s consent to engage the second PTO drive mounted on the transmission case.";
CM_ SG_ 2566759473 EnggmntCnsntTransOutputShaftPTO "Status of the transmission controller’s consent to engage the PTO drive connected to the transmission output shaft.";
CM_ SG_ 2566759473 EnggmntCnsntTrnsfrCsOtptShftPTO "Status of the transmission controller’s consent to engage the PTO drive connected to the transfer case output shaft.";
CM_ SG_ 2566759473 EnableSwitchTransInputShaftPTO1 "Status of the operator’s switch or other input which indicates the desire for engaging the first PTO drive mounted on the";
CM_ SG_ 2566759473 EnableSwitchTransInputShaftPTO2 "Status of the operator’s switch or other input which indicates the desire for engaging the second PTO drive mounted on";
CM_ SG_ 2566759473 EnableSwitchTransOutputShaftPTO "Status of the operator’s switch or other input which indicates the desire for engaging the PTO drive mounted on the";
CM_ SG_ 2566759473 EnblSwtchTrnsfrCsOutputShaftPTO "Status of the operator’s switch or other input which indicates the desire for engaging the PTO drive mounted on the output";
CM_ SG_ 2566759473 EnggmntSttsPTOEngAccssoryDrive2 "Engagement status of the PTO engine accessory drive 2";
CM_ SG_ 2566759473 EnggmntSttsPTOEngAccssoryDrive1 "Engagement status of the PTO engine accessory drive 1";
CM_ SG_ 2566759473 EnggmntCnsntPTOEngAccssryDrive2 "Engagement Consent status for the PTO engine accessory drive 2";
CM_ SG_ 2566759473 EnggmntCnsntPTOEngAccssryDrive1 "Engagement consent status for the PTO engine accessory drive 1";
CM_ SG_ 2566759473 EngagementStatusPTOEngFlywheel "Engagement status of the PTO Engine Flywheel";
CM_ SG_ 2566759473 EngagementConsentPTOEngFlywheel "Engagement Consent status for the PTO Engine Flywheel";
CM_ SG_ 2566759473 EnblSwitchPTOEngAccessoryDrive2 "Status of the PTO engine accessory drive 2 enable switch";
CM_ SG_ 2566759473 EnblSwitchPTOEngAccessoryDrive1 "Status of the PTO engine accessory drive 1 enable switch";
CM_ SG_ 2566759473 EnableSwitchPTOEngFlywheel "Status of the PTO Engine Flywheel enable switch";
CM_ SG_ 2566759473 AtLeastOnePTOEngaged "Indicates that at least one PTO is engaged";
CM_ BO_ 2566759463 "PTO Drive Engagement";
CM_ SG_ 2566759463 EnggmntSttusTransInputShaftPTO1 "Reports if this specific PTO drive is engaged.";
CM_ SG_ 2566759463 EnggmntSttusTransInputShaftPTO2 "Reports if this specific PTO drive is engaged.";
CM_ SG_ 2566759463 EnggmntSttusTransOutputShaftPTO "Reports if this specific PTO drive is engaged.";
CM_ SG_ 2566759463 EnggmntSttsTrnsfrCsOtptShaftPTO "Reports if this specific PTO drive is engaged.";
CM_ SG_ 2566759463 EnggmntCnsntTransInputShaftPTO1 "Status of the transmission controller’s consent to engage the first or sole PTO drive mounted on the transmission case.";
CM_ SG_ 2566759463 EnggmntCnsntTransInputShaftPTO2 "Status of the transmission controller’s consent to engage the second PTO drive mounted on the transmission case.";
CM_ SG_ 2566759463 EnggmntCnsntTransOutputShaftPTO "Status of the transmission controller’s consent to engage the PTO drive connected to the transmission output shaft.";
CM_ SG_ 2566759463 EnggmntCnsntTrnsfrCsOtptShftPTO "Status of the transmission controller’s consent to engage the PTO drive connected to the transfer case output shaft.";
CM_ SG_ 2566759463 EnableSwitchTransInputShaftPTO1 "Status of the operator’s switch or other input which indicates the desire for engaging the first PTO drive mounted on the";
CM_ SG_ 2566759463 EnableSwitchTransInputShaftPTO2 "Status of the operator’s switch or other input which indicates the desire for engaging the second PTO drive mounted on";
CM_ SG_ 2566759463 EnableSwitchTransOutputShaftPTO "Status of the operator’s switch or other input which indicates the desire for engaging the PTO drive mounted on the";
CM_ SG_ 2566759463 EnblSwtchTrnsfrCsOutputShaftPTO "Status of the operator’s switch or other input which indicates the desire for engaging the PTO drive mounted on the output";
CM_ SG_ 2566759463 EnggmntSttsPTOEngAccssoryDrive2 "Engagement status of the PTO engine accessory drive 2";
CM_ SG_ 2566759463 EnggmntSttsPTOEngAccssoryDrive1 "Engagement status of the PTO engine accessory drive 1";
CM_ SG_ 2566759463 EnggmntCnsntPTOEngAccssryDrive2 "Engagement Consent status for the PTO engine accessory drive 2";
CM_ SG_ 2566759463 EnggmntCnsntPTOEngAccssryDrive1 "Engagement consent status for the PTO engine accessory drive 1";
CM_ SG_ 2566759463 EngagementStatusPTOEngFlywheel "Engagement status of the PTO Engine Flywheel";
CM_ SG_ 2566759463 EngagementConsentPTOEngFlywheel "Engagement Consent status for the PTO Engine Flywheel";
CM_ SG_ 2566759463 EnblSwitchPTOEngAccessoryDrive2 "Status of the PTO engine accessory drive 2 enable switch";
CM_ SG_ 2566759463 EnblSwitchPTOEngAccessoryDrive1 "Status of the PTO engine accessory drive 1 enable switch";
CM_ SG_ 2566759463 EnableSwitchPTOEngFlywheel "Status of the PTO Engine Flywheel enable switch";
CM_ SG_ 2566759463 AtLeastOnePTOEngaged "Indicates that at least one PTO is engaged";
CM_ BO_ 2566759427 "PTO Drive Engagement";
CM_ SG_ 2566759427 EnggmntSttusTransInputShaftPTO1 "Reports if this specific PTO drive is engaged.";
CM_ SG_ 2566759427 EnggmntSttusTransInputShaftPTO2 "Reports if this specific PTO drive is engaged.";
CM_ SG_ 2566759427 EnggmntSttusTransOutputShaftPTO "Reports if this specific PTO drive is engaged.";
CM_ SG_ 2566759427 EnggmntSttsTrnsfrCsOtptShaftPTO "Reports if this specific PTO drive is engaged.";
CM_ SG_ 2566759427 EnggmntCnsntTransInputShaftPTO1 "Status of the transmission controller’s consent to engage the first or sole PTO drive mounted on the transmission case.";
CM_ SG_ 2566759427 EnggmntCnsntTransInputShaftPTO2 "Status of the transmission controller’s consent to engage the second PTO drive mounted on the transmission case.";
CM_ SG_ 2566759427 EnggmntCnsntTransOutputShaftPTO "Status of the transmission controller’s consent to engage the PTO drive connected to the transmission output shaft.";
CM_ SG_ 2566759427 EnggmntCnsntTrnsfrCsOtptShftPTO "Status of the transmission controller’s consent to engage the PTO drive connected to the transfer case output shaft.";
CM_ SG_ 2566759427 EnableSwitchTransInputShaftPTO1 "Status of the operator’s switch or other input which indicates the desire for engaging the first PTO drive mounted on the";
CM_ SG_ 2566759427 EnableSwitchTransInputShaftPTO2 "Status of the operator’s switch or other input which indicates the desire for engaging the second PTO drive mounted on";
CM_ SG_ 2566759427 EnableSwitchTransOutputShaftPTO "Status of the operator’s switch or other input which indicates the desire for engaging the PTO drive mounted on the";
CM_ SG_ 2566759427 EnblSwtchTrnsfrCsOutputShaftPTO "Status of the operator’s switch or other input which indicates the desire for engaging the PTO drive mounted on the output";
CM_ SG_ 2566759427 EnggmntSttsPTOEngAccssoryDrive2 "Engagement status of the PTO engine accessory drive 2";
CM_ SG_ 2566759427 EnggmntSttsPTOEngAccssoryDrive1 "Engagement status of the PTO engine accessory drive 1";
CM_ SG_ 2566759427 EnggmntCnsntPTOEngAccssryDrive2 "Engagement Consent status for the PTO engine accessory drive 2";
CM_ SG_ 2566759427 EnggmntCnsntPTOEngAccssryDrive1 "Engagement consent status for the PTO engine accessory drive 1";
CM_ SG_ 2566759427 EngagementStatusPTOEngFlywheel "Engagement status of the PTO Engine Flywheel";
CM_ SG_ 2566759427 EngagementConsentPTOEngFlywheel "Engagement Consent status for the PTO Engine Flywheel";
CM_ SG_ 2566759427 EnblSwitchPTOEngAccessoryDrive2 "Status of the PTO engine accessory drive 2 enable switch";
CM_ SG_ 2566759427 EnblSwitchPTOEngAccessoryDrive1 "Status of the PTO engine accessory drive 1 enable switch";
CM_ SG_ 2566759427 EnableSwitchPTOEngFlywheel "Status of the PTO Engine Flywheel enable switch";
CM_ SG_ 2566759427 AtLeastOnePTOEngaged "Indicates that at least one PTO is engaged";
CM_ BO_ 2633927939 "Vehicle Electrical Power 2";
CM_ SG_ 2633927939 ECUPowerOutputSupplyVoltage3 "The third power output from an ECM.";
CM_ SG_ 2633927939 ECUPowerOutputSupplyVoltage2 "The second power output from an ECM.";
CM_ SG_ 2633927939 ECUPowerOutputSupplyVoltage1 "The first power output from an ECM";
CM_ SG_ 2633927939 BatteryPotential_PowerInput2 "This parameter measures the second source of battery potential as measured at the input of the ECM/actuator etc.";
CM_ BO_ 2566846211 "Vehicle Electrical Power 1";
CM_ SG_ 2566846211 ChargingSystemPotential "Electrical potential measured at the charging system output.";
CM_ SG_ 2566846211 AltCurrent "Measure of electrical current flow from the alternator.";
CM_ SG_ 2566846211 NetBatteryCurrent "Net flow of electrical current into/out of the battery or batteries.";
CM_ SG_ 2566846211 KeyswitchBatteryPotential "Battery potential measured at the input of the electronic control unit supplied through a keyswitch or similar switching";
CM_ SG_ 2566846211 BatteryPotential_PowerInput1 "This parameter measures the first source of battery potential as measured at the input of the ECM/actuator etc.";
CM_ BO_ 2566841088 "Engine Configuration 1";
CM_ SG_ 2566841088 SupportTSC1CtrlPurposeGroup4 "This parameter indicates which TSC1 control purposes are supported in group 4 of 4.";
CM_ SG_ 2566841088 SupportTSC1CtrlPurposeGroup3 "This parameter indicates which TSC1 control purposes are supported in group 3 of 4.";
CM_ SG_ 2566841088 SupportTSC1CtrlPurposeGroup2 "This parameter indicates which TSC1 control purposes are supported in group 2 of 4.";
CM_ SG_ 2566841088 SupportTSC1CtrlPurposeGroup1 "This parameter indicates which TSC1 control purposes are supported in group 1 of 4.";
CM_ SG_ 2566841088 SupportVariableRateTSC1Message "This parameter indicates which TSC1 transmission rates are supported by the engine ECU in addition to the required";
CM_ SG_ 2566841088 EngDefaultTorqueLimit "Companion parameter to Transmission Torque Limit (SPN 1845).";
CM_ SG_ 2566841088 EngMomentOfInertia "Moment of inertia for the engine, including items driven full-time by the engine such as fuel, oil and cooling pumps.";
CM_ SG_ 2566841088 EngExRngRqdSpdCtrlRngUpperLimit "The maximum engine speed regardless of load that the engine will allow when operating in a speed control/limit mode,";
CM_ SG_ 2566841088 EngRqdTorqueCtrlRangeUpperLimit "The maximum engine torque that the engine will allow when operating in a torque control/limit mode.";
CM_ SG_ 2566841088 EngRqdTorqueCtrlRangeLowerLimit "The minimum engine torque that the engine will allow when operating in a torque control/limit mode.";
CM_ SG_ 2566841088 EngRqedSpeedCtrlRangeUpperLimit "The maximum engine speed regardless of load that the engine will allow when operating in a speed control/limit mode,";
CM_ SG_ 2566841088 EngRqedSpeedCtrlRangeLowerLimit "The minimum engine speed that the engine will allow when operating in a speed control/limit mode.";
CM_ SG_ 2566841088 EngMxMomentaryOverrideTimeLimit "The maximum time limit allowed to override the engine's high idle speed.";
CM_ SG_ 2566841088 EngMxMmntaryOverrideSpeedPoint7 "The maximum engine speed above high idle allowed by the engine control during a momentary high idle override.";
CM_ SG_ 2566841088 EngReferenceTorque "This parameter is the 100% reference value for all defined indicated engine torque parameters.";
CM_ SG_ 2566841088 EngSpeedAtHighIdlePoint6 "Engine speed of high idle (point 6) of the engine torque map (see PGN 65251 and supporting document).";
CM_ SG_ 2566841088 EngGainOfEndspeedGovernor "The endspeed governor is defined as a linear line with the following equations (Capital letters mean physical values, small";
CM_ SG_ 2566841088 EngPercentTorqueAtPoint5 "The torque limit that indicates the available engine torque which can be provided by the engine at point 3, 4, and 5 of the";
CM_ SG_ 2566841088 EngSpeedAtPoint5 "Engine speed of point 3, 4, and 5 of the engine torque map (see PGN 65251 and supporting document).";
CM_ SG_ 2566841088 EngPercentTorqueAtPoint4 "The torque limit that indicates the available engine torque which can be provided by the engine at point 3, 4, and 5 of the";
CM_ SG_ 2566841088 EngSpeedAtPoint4 "Engine speed of point 3, 4, and 5 of the engine torque map (see PGN 65251 and supporting document).";
CM_ SG_ 2566841088 EngPercentTorqueAtPoint3 "The torque limit that indicates the available engine torque which can be provided by the engine at point 3, 4, and 5 of the";
CM_ SG_ 2566841088 EngSpeedAtPoint3 "Engine speed of point 3, 4, and 5 of the engine torque map (see PGN 65251 and supporting document).";
CM_ SG_ 2566841088 EngPercentTorqueAtPoint2 "The torque limit that indicates the available engine torque which can be provided by the engine at point 2 of the engine";
CM_ SG_ 2566841088 EngSpeedAtPoint2 "Engine speed of point 2 of the engine torque map (see PGN 65251 and supporting document).";
CM_ SG_ 2566841088 EngPercentTorqueAtIdlePoint1 "The torque limit that indicates the available engine torque which can be provided by the engine at idle speed.";
CM_ SG_ 2566841088 EngSpeedAtIdlePoint1 "Stationary low idle speed of engine which includes influences due to engine temperature (after power up) and other";
CM_ BO_ 2566834947 "Active diagnostic trouble codes";
CM_ SG_ 2566834947 DM2_SPNConversionMethod_DTC1 "Diagnostic Trouble Code";
CM_ SG_ 2566834947 DM2_SPNConversionMethod_DTC2 "Diagnostic Trouble Code";
CM_ SG_ 2566834947 DM2_SPNConversionMethod_DTC3 "Diagnostic Trouble Code";
CM_ SG_ 2566834947 DM2_SPNConversionMethod_DTC4 "Diagnostic Trouble Code";
CM_ SG_ 2566834947 DM2_SPNConversionMethod_DTC5 "Diagnostic Trouble Code";
CM_ SG_ 2566834947 DM2_SPNConversionMethod_DTC6 "Diagnostic Trouble Code";
CM_ SG_ 2566834947 DM2_SPNConversionMethod_DTC7 "Diagnostic Trouble Code";
CM_ SG_ 2566834947 DM2_SPNConversionMethod_DTC8 "Diagnostic Trouble Code";
CM_ SG_ 2566834947 DM2_OccurenceCount_DTC8 "The 7 bit occurence count field contains the number of times a fault has gone from active to previously active.";
CM_ SG_ 2566834947 DM2_OccurenceCount_DTC7 "The 7 bit occurence count field contains the number of times a fault has gone from active to previously active.";
CM_ SG_ 2566834947 DM2_OccurenceCount_DTC6 "The 7 bit occurence count field contains the number of times a fault has gone from active to previously active.";
CM_ SG_ 2566834947 DM2_OccurenceCount_DTC5 "The 7 bit occurence count field contains the number of times a fault has gone from active to previously active.";
CM_ SG_ 2566834947 DM2_OccurenceCount_DTC4 "The 7 bit occurence count field contains the number of times a fault has gone from active to previously active.";
CM_ SG_ 2566834947 DM2_OccurenceCount_DTC3 "The 7 bit occurence count field contains the number of times a fault has gone from active to previously active.";
CM_ SG_ 2566834947 DM2_OccurenceCount_DTC2 "The 7 bit occurence count field contains the number of times a fault has gone from active to previously active.";
CM_ SG_ 2566834947 DM2_OccurenceCount_DTC1 "The 7 bit occurence count field contains the number of times a fault has gone from active to previously active.";
CM_ SG_ 2566834947 DM2_FMI_DTC8 "The FMI defines the type of failure detected in the subsystem identified by an SPN.";
CM_ SG_ 2566834947 DM2_FMI_DTC7 "The FMI defines the type of failure detected in the subsystem identified by an SPN.";
CM_ SG_ 2566834947 DM2_FMI_DTC6 "The FMI defines the type of failure detected in the subsystem identified by an SPN.";
CM_ SG_ 2566834947 DM2_FMI_DTC5 "The FMI defines the type of failure detected in the subsystem identified by an SPN.";
CM_ SG_ 2566834947 DM2_FMI_DTC4 "The FMI defines the type of failure detected in the subsystem identified by an SPN.";
CM_ SG_ 2566834947 DM2_FMI_DTC3 "The FMI defines the type of failure detected in the subsystem identified by an SPN.";
CM_ SG_ 2566834947 DM2_FMI_DTC2 "The FMI defines the type of failure detected in the subsystem identified by an SPN.";
CM_ SG_ 2566834947 DM2_FMI_DTC1 "The FMI defines the type of failure detected in the subsystem identified by an SPN.";
CM_ SG_ 2566834947 DM2_SPN1_DTC8 "SPN, 8 least significant bits";
CM_ SG_ 2566834947 DM2_SPN3_DTC8 "SPN, 3 most significant bits";
CM_ SG_ 2566834947 DM2_SPN3_DTC7 "SPN, 3 most significant bits";
CM_ SG_ 2566834947 DM2_SPN3_DTC6 "SPN, 3 most significant bits";
CM_ SG_ 2566834947 DM2_SPN3_DTC5 "SPN, 3 most significant bits";
CM_ SG_ 2566834947 DM2_SPN3_DTC4 "SPN, 3 most significant bits";
CM_ SG_ 2566834947 DM2_SPN3_DTC3 "SPN, 3 most significant bits";
CM_ SG_ 2566834947 DM2_SPN3_DTC2 "SPN, 3 most significant bits";
CM_ SG_ 2566834947 DM2_SPN3_DTC1 "SPN, 3 most significant bits";
CM_ SG_ 2566834947 DM2_SPN2_DTC8 "SPN, second byte of SPN";
CM_ SG_ 2566834947 DM2_SPN2_DTC7 "SPN, second byte of SPN";
CM_ SG_ 2566834947 DM2_SPN2_DTC6 "SPN, second byte of SPN";
CM_ SG_ 2566834947 DM2_SPN2_DTC5 "SPN, second byte of SPN";
CM_ SG_ 2566834947 DM2_SPN2_DTC4 "SPN, second byte of SPN";
CM_ SG_ 2566834947 DM2_SPN2_DTC3 "SPN, second byte of SPN";
CM_ SG_ 2566834947 DM2_SPN2_DTC2 "SPN, second byte of SPN";
CM_ SG_ 2566834947 DM2_SPN2_DTC1 "SPN, second byte of SPN";
CM_ SG_ 2566834947 DM2_SPN1_DTC5 "SPN, 8 least significant bits";
CM_ SG_ 2566834947 DM2_SPN1_DTC6 "SPN, 8 least significant bits";
CM_ SG_ 2566834947 DM2_SPN1_DTC7 "SPN, 8 least significant bits";
CM_ SG_ 2566834947 DM2_SPN1_DTC2 "SPN, 8 least significant bits";
CM_ SG_ 2566834947 DM2_SPN1_DTC4 "SPN, 8 least significant bits";
CM_ SG_ 2566834947 DM2_SPN1_DTC3 "SPN, 8 least significant bits";
CM_ SG_ 2566834947 DM2_SPN1_DTC1 "SPN, 8 least significant bits";
CM_ SG_ 2566834947 DM2FlashRedStopLamp "This parameter provides the capability to flash the RSL (SPN 3039).";
CM_ SG_ 2566834947 DM2FlashProtectLamp "This parameter provides the capability to flash the engine protect lamp (SPN 3041).";
CM_ SG_ 2566834947 DM2FlashMalfuncIndicatorLamp "This parameter provides the capability to flash the MIL (SPN 3038).";
CM_ SG_ 2566834947 DM2FlashAmberWarningLamp "This parameter provides the capability to flash the AWL (SPN 3040). ";
CM_ SG_ 2566834947 DM2MalfunctionIndicatorLampState "A lamp used to relay only emissions-related trouble code information.";
CM_ SG_ 2566834947 DM2AmberWarningLampStatus "This lamp is used to relay trouble code information that is reporting a problem with the vehicle system but the vehicle need
not be immediately stopped.";
CM_ SG_ 2566834947 DM2RedStopLampState "This lamp is uesed to relay trouble code information that is of a severe enought condition that it warrants stopping the vehicle.";
CM_ SG_ 2566834947 DM2ProtectLampStatus "This lamp is used to relay trouble code informatio that is reporting a problem with a vehicle system that is most
probably not electronic subsystem related.";
CM_ BO_ 2566834691 "Active diagnostic trouble codes";
CM_ SG_ 2566834691 SPNConversionMethod_DTC1 "Diagnostic Trouble Code";
CM_ SG_ 2566834691 SPNConversionMethod_DTC2 "Diagnostic Trouble Code";
CM_ SG_ 2566834691 SPNConversionMethod_DTC3 "Diagnostic Trouble Code";
CM_ SG_ 2566834691 SPNConversionMethod_DTC4 "Diagnostic Trouble Code";
CM_ SG_ 2566834691 SPNConversionMethod_DTC5 "Diagnostic Trouble Code";
CM_ SG_ 2566834691 SPNConversionMethod_DTC6 "Diagnostic Trouble Code";
CM_ SG_ 2566834691 SPNConversionMethod_DTC7 "Diagnostic Trouble Code";
CM_ SG_ 2566834691 SPNConversionMethod_DTC8 "Diagnostic Trouble Code";
CM_ SG_ 2566834691 OccurenceCount_DTC8 "The 7 bit occurence count field contains the number of times a fault has gone from active to previously active.";
CM_ SG_ 2566834691 OccurenceCount_DTC7 "The 7 bit occurence count field contains the number of times a fault has gone from active to previously active.";
CM_ SG_ 2566834691 OccurenceCount_DTC6 "The 7 bit occurence count field contains the number of times a fault has gone from active to previously active.";
CM_ SG_ 2566834691 OccurenceCount_DTC5 "The 7 bit occurence count field contains the number of times a fault has gone from active to previously active.";
CM_ SG_ 2566834691 OccurenceCount_DTC4 "The 7 bit occurence count field contains the number of times a fault has gone from active to previously active.";
CM_ SG_ 2566834691 OccurenceCount_DTC3 "The 7 bit occurence count field contains the number of times a fault has gone from active to previously active.";
CM_ SG_ 2566834691 OccurenceCount_DTC2 "The 7 bit occurence count field contains the number of times a fault has gone from active to previously active.";
CM_ SG_ 2566834691 OccurenceCount_DTC1 "The 7 bit occurence count field contains the number of times a fault has gone from active to previously active.";
CM_ SG_ 2566834691 FMI_DTC8 "The FMI defines the type of failure detected in the subsystem identified by an SPN.";
CM_ SG_ 2566834691 FMI_DTC7 "The FMI defines the type of failure detected in the subsystem identified by an SPN.";
CM_ SG_ 2566834691 FMI_DTC6 "The FMI defines the type of failure detected in the subsystem identified by an SPN.";
CM_ SG_ 2566834691 FMI_DTC5 "The FMI defines the type of failure detected in the subsystem identified by an SPN.";
CM_ SG_ 2566834691 FMI_DTC4 "The FMI defines the type of failure detected in the subsystem identified by an SPN.";
CM_ SG_ 2566834691 FMI_DTC3 "The FMI defines the type of failure detected in the subsystem identified by an SPN.";
CM_ SG_ 2566834691 FMI_DTC2 "The FMI defines the type of failure detected in the subsystem identified by an SPN.";
CM_ SG_ 2566834691 FMI_DTC1 "The FMI defines the type of failure detected in the subsystem identified by an SPN.";
CM_ SG_ 2566834691 SPN1_DTC8 "SPN, 8 least significant bits";
CM_ SG_ 2566834691 SPN3_DTC8 "SPN, 3 most significant bits";
CM_ SG_ 2566834691 SPN3_DTC7 "SPN, 3 most significant bits";
CM_ SG_ 2566834691 SPN3_DTC6 "SPN, 3 most significant bits";
CM_ SG_ 2566834691 SPN3_DTC5 "SPN, 3 most significant bits";
CM_ SG_ 2566834691 SPN3_DTC4 "SPN, 3 most significant bits";
CM_ SG_ 2566834691 SPN3_DTC3 "SPN, 3 most significant bits";
CM_ SG_ 2566834691 SPN3_DTC2 "SPN, 3 most significant bits";
CM_ SG_ 2566834691 SPN3_DTC1 "SPN, 3 most significant bits";
CM_ SG_ 2566834691 SPN2_DTC8 "SPN, second byte of SPN";
CM_ SG_ 2566834691 SPN2_DTC7 "SPN, second byte of SPN";
CM_ SG_ 2566834691 SPN2_DTC6 "SPN, second byte of SPN";
CM_ SG_ 2566834691 SPN2_DTC5 "SPN, second byte of SPN";
CM_ SG_ 2566834691 SPN2_DTC4 "SPN, second byte of SPN";
CM_ SG_ 2566834691 SPN2_DTC3 "SPN, second byte of SPN";
CM_ SG_ 2566834691 SPN2_DTC2 "SPN, second byte of SPN";
CM_ SG_ 2566834691 SPN2_DTC1 "SPN, second byte of SPN";
CM_ SG_ 2566834691 SPN1_DTC5 "SPN, 8 least significant bits";
CM_ SG_ 2566834691 SPN1_DTC6 "SPN, 8 least significant bits";
CM_ SG_ 2566834691 SPN1_DTC7 "SPN, 8 least significant bits";
CM_ SG_ 2566834691 SPN1_DTC2 "SPN, 8 least significant bits";
CM_ SG_ 2566834691 SPN1_DTC4 "SPN, 8 least significant bits";
CM_ SG_ 2566834691 SPN1_DTC3 "SPN, 8 least significant bits";
CM_ SG_ 2566834691 SPN1_DTC1 "SPN, 8 least significant bits";
CM_ SG_ 2566834691 FlashRedStopLamp "This parameter provides the capability to flash the RSL (SPN 3039).";
CM_ SG_ 2566834691 FlashProtectLamp "This parameter provides the capability to flash the engine protect lamp (SPN 3041).";
CM_ SG_ 2566834691 FlashMalfuncIndicatorLamp "This parameter provides the capability to flash the MIL (SPN 3038).";
CM_ SG_ 2566834691 FlashAmberWarningLamp "This parameter provides the capability to flash the AWL (SPN 3040). ";
CM_ SG_ 2566834691 MalfunctionIndicatorLampState "A lamp used to relay only emissions-related trouble code information.";
CM_ SG_ 2566834691 AmberWarningLampStatus "This lamp is used to relay trouble code information that is reporting a problem with the vehicle system but the vehicle need
not be immediately stopped.";
CM_ SG_ 2566834691 RedStopLampState "This lamp is uesed to relay trouble code information that is of a severe enought condition that it warrants stopping the vehicle.";
CM_ SG_ 2566834691 ProtectLampStatus "This lamp is used to relay trouble code informatio that is reporting a problem with a vehicle system that is most
probably not electronic subsystem related.";
CM_ BO_ 2566834688 "Active diagnostic trouble codes";
CM_ SG_ 2566834688 DTC5 "Diagnostic Trouble Code";
CM_ SG_ 2566834688 DTC1 "Diagnostic Trouble Code";
CM_ SG_ 2566834688 FlashRedStopLamp "This parameter provides the capability to flash the RSL (SPN 3039).";
CM_ SG_ 2566834688 FlashProtectLamp "This parameter provides the capability to flash the engine protect lamp (SPN 3041).";
CM_ SG_ 2566834688 FlashMalfuncIndicatorLamp "This parameter provides the capability to flash the MIL (SPN 3038).";
CM_ SG_ 2566834688 FlashAmberWarningLamp "This parameter provides the capability to flash the AWL (SPN 3040). ";
CM_ SG_ 2566834688 MalfunctionIndicatorLampStatus "A lamp used to relay only emissions-related trouble code information.";
CM_ SG_ 2566834688 AmberWarningLampStatus "This lamp is used to relay trouble code information that is reporting a problem with the vehicle system but the vehicle need
not be immediately stopped.";
CM_ SG_ 2566834688 RedStopLampState "This lamp is uesed to relay trouble code information that is of a severe enought condition that it warrants stopping the vehicle.";
CM_ SG_ 2566834688 ProtectLampStatus "This lamp is used to relay trouble code informatio that is reporting a problem with a vehicle system that is most
probably not electronic subsystem related.";
CM_ SG_ 2566834688 DTC4 "Diagnostic Trouble Code";
CM_ SG_ 2566834688 DTC3 "Diagnostic Trouble Code";
CM_ SG_ 2566834688 DTC2 "Diagnostic Trouble Code";
CM_ SG_ 2164211715 GrossCombinationWeight "Total weight of the truck and all the trailers with on-board scales.";
CM_ BO_ 2566844721 "Cruise Control/Vehicle Speed";
CM_ SG_ 2566844721 ParkBrakeReleaseInhibitRq "Park Brake Release Inhibit Request signals the desire that an applied park brake remain applied and limit the ability of the";
CM_ SG_ 2566844721 PTOGovernorState "This parameter is used to indicate the current state or mode of operation by the power takeoff (PTO) governor.";
CM_ SG_ 2566844721 EngShutdownOverrideSwitch "Switch signal which indicates the position of the engine shutdown override switch.";
CM_ SG_ 2566844721 EngTestModeSwitch "Switch signal which indicates the position of the engine test mode switch.";
CM_ SG_ 2566844721 EngIdleDecrementSwitch "Switch signal which indicates the position of the idle decrement switch.";
CM_ SG_ 2566844721 EngIdleIncrementSwitch "Switch signal which indicates the position of the idle increment switch.";
CM_ SG_ 2566844721 CruiseCtrlStates "This parameter is used to indicate the current state, or mode, of operation by the cruise control device.";
CM_ SG_ 2566844721 CruiseCtrlSetSpeed "Value of set (chosen) velocity of velocity control system.";
CM_ SG_ 2566844721 CruiseCtrlAccelerateSwitch "Switch signal of the cruise control activator which indicates that the activator is in the position “accelerate.";
CM_ SG_ 2566844721 CruiseCtrlResumeSwitch "Switch signal of the cruise control activator which indicates that the activator is in the position “resume.";
CM_ SG_ 2566844721 CruiseCtrlCoastSwitch "Switch signal of the cruise control activator which indicates that the activator is in the position “coast (decelerate).";
CM_ SG_ 2566844721 CruiseCtrlSetSwitch "Switch signal of the cruise control activator which indicates that the activator is in the position “set.";
CM_ SG_ 2566844721 ClutchSwitch "Switch signal which indicates that the clutch pedal is being pressed.";
CM_ SG_ 2566844721 BrakeSwitch_SA31 "Switch signal which indicates that the driver operated brake foot pedal is being pressed.";
CM_ SG_ 2566844721 CruiseCtrlEnableSwitch "Switch signal which indicates that it is possible to manage the cruise control function.";
CM_ SG_ 2566844721 CruiseCtrlActive "Cruise control is switched on.";
CM_ SG_ 2566844721 WheelBasedVehicleSpeed "Speed of the vehicle as calculated from wheel or tailshaft speed.";
CM_ SG_ 2566844721 CruiseCtrlPauseSwitch "Switch signal which indicates the position of the Cruise Control Pause Switch used on Remote Cruise Control applications.";
CM_ SG_ 2566844721 ParkingBrakeSwitch "Switch signal which indicates when the parking brake is set.";
CM_ SG_ 2566844721 TwoSpeedAxleSwitch "Switch signal which indicates the current axle range.";
CM_ BO_ 2566844711 "Cruise Control/Vehicle Speed";
CM_ SG_ 2566844711 ParkBrakeReleaseInhibitRq "Park Brake Release Inhibit Request signals the desire that an applied park brake remain applied and limit the ability of the";
CM_ SG_ 2566844711 PTOGovernorState "This parameter is used to indicate the current state or mode of operation by the power takeoff (PTO) governor.";
CM_ SG_ 2566844711 EngShutdownOverrideSwitch "Switch signal which indicates the position of the engine shutdown override switch.";
CM_ SG_ 2566844711 EngTestModeSwitch "Switch signal which indicates the position of the engine test mode switch.";
CM_ SG_ 2566844711 EngIdleDecrementSwitch "Switch signal which indicates the position of the idle decrement switch.";
CM_ SG_ 2566844711 EngIdleIncrementSwitch "Switch signal which indicates the position of the idle increment switch.";
CM_ SG_ 2566844711 CruiseCtrlStates "This parameter is used to indicate the current state, or mode, of operation by the cruise control device.";
CM_ SG_ 2566844711 CruiseCtrlSetSpeed "Value of set (chosen) velocity of velocity control system.";
CM_ SG_ 2566844711 CruiseCtrlAccelerateSwitch "Switch signal of the cruise control activator which indicates that the activator is in the position “accelerate.";
CM_ SG_ 2566844711 CruiseCtrlResumeSwitch "Switch signal of the cruise control activator which indicates that the activator is in the position “resume.";
CM_ SG_ 2566844711 CruiseCtrlCoastSwitch "Switch signal of the cruise control activator which indicates that the activator is in the position “coast (decelerate).";
CM_ SG_ 2566844711 CruiseCtrlSetSwitch "Switch signal of the cruise control activator which indicates that the activator is in the position “set.";
CM_ SG_ 2566844711 ClutchSwitch "Switch signal which indicates that the clutch pedal is being pressed.";
CM_ SG_ 2566844711 BrakeSwitch_SA27 "Switch signal which indicates that the driver operated brake foot pedal is being pressed.";
CM_ SG_ 2566844711 CruiseCtrlEnableSwitch "Switch signal which indicates that it is possible to manage the cruise control function.";
CM_ SG_ 2566844711 CruiseCtrlActive "Cruise control is switched on.";
CM_ SG_ 2566844711 WheelBasedVehicleSpeed "Speed of the vehicle as calculated from wheel or tailshaft speed.";
CM_ SG_ 2566844711 CruiseCtrlPauseSwitch "Switch signal which indicates the position of the Cruise Control Pause Switch used on Remote Cruise Control applications.";
CM_ SG_ 2566844711 ParkingBrakeSwitch "Switch signal which indicates when the parking brake is set.";
CM_ SG_ 2566844711 TwoSpeedAxleSwitch "Switch signal which indicates the current axle range.";
BA_DEF_ SG_  "SigType" ENUM  "Default","Range","RangeSigned","ASCII","Discrete","Control","ReferencePGN","DTC","StringDelimiter","StringLength","StringLengthControl";
BA_DEF_ SG_  "GenSigStartValue" INT 0 10000;
BA_DEF_ SG_  "GenSigSendType" ENUM  "Cyclic","OnWrite","reserved","OnChange","reserved","reserved","reserved","NoSigSendType";
BA_DEF_ SG_  "GenSigILSupport" ENUM  "Yes","No";
BA_DEF_ SG_  "GenSigEVName" STRING ;
BA_DEF_ SG_  "SPN" INT 0 524287;
BA_DEF_ BO_  "GenMsgStartDelayTime" INT 0 100000;
BA_DEF_ BO_  "GenMsgILSupport" ENUM  "Yes","No";
BA_DEF_ BO_  "GenMsgRequestable" INT 0 1;
BA_DEF_ BO_  "GenMsgSendType" ENUM  "cyclic","reserved","cyclicIfActive","reserved","reserved","reserved","reserved","reserved","noMsgSendType";
BA_DEF_ BO_  "VFrameFormat" ENUM  "StandardCAN","ExtendedCAN","reserved","J1939PG";
BA_DEF_ BO_  "GenMsgCycleTime" INT 0 3600000;
BA_DEF_ BU_  "NmStationAddress" INT 0 255;
BA_DEF_ BU_  "NmJ1939IndustryGroup" INT 0 7;
BA_DEF_ BU_  "NmJ1939System" INT 0 127;
BA_DEF_ BU_  "NmJ1939Function" INT 0 255;
BA_DEF_ BU_  "NmJ1939FunctionInstance" INT 0 7;
BA_DEF_ BU_  "NmJ1939ECUInstance" INT 0 3;
BA_DEF_  "DatabaseVersion" STRING ;
BA_DEF_  "BusType" STRING ;
BA_DEF_  "ProtocolType" STRING ;
BA_DEF_  "SAE_J1939_75_SpecVersion" STRING ;
BA_DEF_  "SAE_J1939_21_SpecVersion" STRING ;
BA_DEF_  "SAE_J1939_73_SpecVersion" STRING ;
BA_DEF_  "SAE_J1939_71_SpecVersion" STRING ;
BA_DEF_ SG_  "SystemSignalLongSymbol" STRING ;
BA_DEF_DEF_  "SigType" "Default";
BA_DEF_DEF_  "GenSigStartValue" 0;
BA_DEF_DEF_  "GenSigSendType" "NoSigSendType";
BA_DEF_DEF_  "GenSigILSupport" "Yes";
BA_DEF_DEF_  "GenSigEVName" "Env@Nodename_@Signame";
BA_DEF_DEF_  "SPN" 0;
BA_DEF_DEF_  "GenMsgStartDelayTime" 0;
BA_DEF_DEF_  "GenMsgILSupport" "Yes";
BA_DEF_DEF_  "GenMsgRequestable" 1;
BA_DEF_DEF_  "GenMsgSendType" "noMsgSendType";
BA_DEF_DEF_  "VFrameFormat" "J1939PG";
BA_DEF_DEF_  "GenMsgCycleTime" 0;
BA_DEF_DEF_  "NmStationAddress" 254;
BA_DEF_DEF_  "NmJ1939IndustryGroup" 0;
BA_DEF_DEF_  "NmJ1939System" 0;
BA_DEF_DEF_  "NmJ1939Function" 0;
BA_DEF_DEF_  "NmJ1939FunctionInstance" 0;
BA_DEF_DEF_  "NmJ1939ECUInstance" 0;
BA_DEF_DEF_  "DatabaseVersion" "";
BA_DEF_DEF_  "BusType" "";
BA_DEF_DEF_  "ProtocolType" "";
BA_DEF_DEF_  "SAE_J1939_75_SpecVersion" "";
BA_DEF_DEF_  "SAE_J1939_21_SpecVersion" "";
BA_DEF_DEF_  "SAE_J1939_73_SpecVersion" "";
BA_DEF_DEF_  "SAE_J1939_71_SpecVersion" "";
BA_DEF_DEF_  "SystemSignalLongSymbol" "";
BA_ "DatabaseVersion" "7.2";
BA_ "BusType" "CAN";
BA_ "ProtocolType" "J1939";
BA_ "SAE_J1939_75_SpecVersion" "2005-10";
BA_ "SAE_J1939_21_SpecVersion" "2006-10";
BA_ "SAE_J1939_73_SpecVersion" "2009-09";
BA_ "SAE_J1939_71_SpecVersion" "2009-09";
BA_ "NmStationAddress" BU_ Turbocharger 2;
BA_ "NmJ1939Function" BU_ Turbocharger 133;
BA_ "NmStationAddress" BU_ OnBoardDataLogger 251;
BA_ "NmJ1939Function" BU_ OnBoardDataLogger 130;
BA_ "NmStationAddress" BU_ OffBoardDiagnosticTool2 250;
BA_ "NmJ1939Function" BU_ OffBoardDiagnosticTool2 129;
BA_ "NmJ1939FunctionInstance" BU_ OffBoardDiagnosticTool2 1;
BA_ "NmStationAddress" BU_ OffBoardDiagnosticTool1 249;
BA_ "NmJ1939Function" BU_ OffBoardDiagnosticTool1 129;
BA_ "NmStationAddress" BU_ FileServer 248;
BA_ "NmJ1939Function" BU_ FileServer 61;
BA_ "NmStationAddress" BU_ ParkingBrakeController 80;
BA_ "NmJ1939Function" BU_ ParkingBrakeController 9;
BA_ "NmStationAddress" BU_ SeatControl2 79;
BA_ "NmJ1939Function" BU_ SeatControl2 40;
BA_ "NmStationAddress" BU_ FanDriveController 78;
BA_ "NmJ1939Function" BU_ FanDriveController 58;
BA_ "NmStationAddress" BU_ SteeringColumnUnit 77;
BA_ "NmJ1939Function" BU_ SteeringColumnUnit 57;
BA_ "NmStationAddress" BU_ CommunicationUnitRadio 76;
BA_ "NmJ1939Function" BU_ CommunicationUnitRadio 56;
BA_ "NmStationAddress" BU_ CommunicationUnitSatellite 75;
BA_ "NmJ1939Function" BU_ CommunicationUnitSatellite 55;
BA_ "NmStationAddress" BU_ CommunicationUnitCellular 74;
BA_ "NmJ1939Function" BU_ CommunicationUnitCellular 54;
BA_ "NmStationAddress" BU_ PropulsionBatteryCharger 73;
BA_ "NmJ1939Function" BU_ PropulsionBatteryCharger 31;
BA_ "NmStationAddress" BU_ ChassisController2 72;
BA_ "NmJ1939Function" BU_ ChassisController2 52;
BA_ "NmJ1939FunctionInstance" BU_ ChassisController2 1;
BA_ "NmStationAddress" BU_ ChassisController1 71;
BA_ "NmJ1939Function" BU_ ChassisController1 52;
BA_ "NmStationAddress" BU_ EngineValveControl 70;
BA_ "NmJ1939Function" BU_ EngineValveControl 63;
BA_ "NmStationAddress" BU_ AuxiliaryHeater2 69;
BA_ "NmJ1939Function" BU_ AuxiliaryHeater2 50;
BA_ "NmJ1939FunctionInstance" BU_ AuxiliaryHeater2 1;
BA_ "NmStationAddress" BU_ AuxiliaryHeater1 68;
BA_ "NmJ1939Function" BU_ AuxiliaryHeater1 50;
BA_ "NmStationAddress" BU_ ClutchUnit 67;
BA_ "NmJ1939Function" BU_ ClutchUnit 49;
BA_ "NmStationAddress" BU_ RampControl 66;
BA_ "NmJ1939Function" BU_ RampControl 48;
BA_ "NmStationAddress" BU_ InformationSystem1 65;
BA_ "NmJ1939Function" BU_ InformationSystem1 47;
BA_ "NmStationAddress" BU_ SuspensionSystemController2 64;
BA_ "NmJ1939Function" BU_ SuspensionSystemController2 35;
BA_ "NmStationAddress" BU_ OilSensor 63;
BA_ "NmJ1939Function" BU_ OilSensor 46;
BA_ "NmStationAddress" BU_ VehicleDynamicStability 62;
BA_ "NmJ1939Function" BU_ VehicleDynamicStability 45;
BA_ "NmStationAddress" BU_ ExhaustEmissionController 61;
BA_ "NmJ1939Function" BU_ ExhaustEmissionController 44;
BA_ "NmStationAddress" BU_ TransmissionDisplay2 60;
BA_ "NmJ1939Function" BU_ TransmissionDisplay2 43;
BA_ "NmStationAddress" BU_ TransmissionDisplay1 59;
BA_ "NmJ1939Function" BU_ TransmissionDisplay1 43;
BA_ "NmStationAddress" BU_ ClimateControl2 58;
BA_ "NmJ1939Function" BU_ ClimateControl2 21;
BA_ "NmStationAddress" BU_ WaterPumpController 57;
BA_ "NmJ1939Function" BU_ WaterPumpController 42;
BA_ "NmStationAddress" BU_ RearAxleSteeringController 56;
BA_ "NmStationAddress" BU_ LightingOperatorControl 55;
BA_ "NmJ1939Function" BU_ LightingOperatorControl 41;
BA_ "NmStationAddress" BU_ SeatController1 54;
BA_ "NmJ1939Function" BU_ SeatController1 40;
BA_ "NmStationAddress" BU_ IgnitionController2 53;
BA_ "NmJ1939Function" BU_ IgnitionController2 39;
BA_ "NmJ1939FunctionInstance" BU_ IgnitionController2 1;
BA_ "NmStationAddress" BU_ IgnitionController1 52;
BA_ "NmJ1939Function" BU_ IgnitionController1 39;
BA_ "NmStationAddress" BU_ TirePressureController 51;
BA_ "NmJ1939Function" BU_ TirePressureController 38;
BA_ "NmStationAddress" BU_ CabController2 50;
BA_ "NmJ1939Function" BU_ CabController2 37;
BA_ "NmStationAddress" BU_ CabController1 49;
BA_ "NmJ1939Function" BU_ CabController1 37;
BA_ "NmStationAddress" BU_ PneumaticSystemController 48;
BA_ "NmJ1939Function" BU_ PneumaticSystemController 36;
BA_ "NmStationAddress" BU_ SuspensionSystemController1 47;
BA_ "NmJ1939Function" BU_ SuspensionSystemController1 35;
BA_ "NmStationAddress" BU_ HydraulicPumpController 46;
BA_ "NmJ1939Function" BU_ HydraulicPumpController 34;
BA_ "NmStationAddress" BU_ EnduranceBrakingSystem 45;
BA_ "NmJ1939Function" BU_ EnduranceBrakingSystem 64;
BA_ "NmStationAddress" BU_ RetarderExhaustEngine2 44;
BA_ "NmJ1939Function" BU_ RetarderExhaustEngine2 12;
BA_ "NmJ1939FunctionInstance" BU_ RetarderExhaustEngine2 1;
BA_ "NmStationAddress" BU_ OnBoardDiagnosticUnit 43;
BA_ "NmJ1939Function" BU_ OnBoardDiagnosticUnit 62;
BA_ "NmStationAddress" BU_ HeadwayController 42;
BA_ "NmJ1939Function" BU_ HeadwayController 32;
BA_ "NmStationAddress" BU_ RetarderExhaustEngine1 41;
BA_ "NmJ1939Function" BU_ RetarderExhaustEngine1 12;
BA_ "NmStationAddress" BU_ CabDisplay1 40;
BA_ "NmJ1939Function" BU_ CabDisplay1 60;
BA_ "NmStationAddress" BU_ ManagementComputer 39;
BA_ "NmJ1939Function" BU_ ManagementComputer 30;
BA_ "NmStationAddress" BU_ VirtualTerminal 38;
BA_ "NmJ1939Function" BU_ VirtualTerminal 29;
BA_ "NmStationAddress" BU_ OffVehicleGateway 37;
BA_ "NmJ1939Function" BU_ OffVehicleGateway 28;
BA_ "NmStationAddress" BU_ PowerTakeOffFront 36;
BA_ "NmJ1939Function" BU_ PowerTakeOffFront 27;
BA_ "NmStationAddress" BU_ HitchControl 35;
BA_ "NmStationAddress" BU_ AuxiliaryValveControl 34;
BA_ "NmStationAddress" BU_ BodyController 33;
BA_ "NmJ1939Function" BU_ BodyController 26;
BA_ "NmStationAddress" BU_ TractorTrailerBridge1 32;
BA_ "NmStationAddress" BU_ StarterSystem 31;
BA_ "NmJ1939Function" BU_ StarterSystem 59;
BA_ "NmStationAddress" BU_ ElectricalSystem 30;
BA_ "NmJ1939Function" BU_ ElectricalSystem 67;
BA_ "NmStationAddress" BU_ VehicleSecurity 29;
BA_ "NmJ1939Function" BU_ VehicleSecurity 24;
BA_ "NmStationAddress" BU_ VehicleNavigation 28;
BA_ "NmJ1939Function" BU_ VehicleNavigation 23;
BA_ "NmStationAddress" BU_ AerodynamicControl 27;
BA_ "NmJ1939Function" BU_ AerodynamicControl 22;
BA_ "NmStationAddress" BU_ ElectricalChargingSystem 26;
BA_ "NmJ1939Function" BU_ ElectricalChargingSystem 53;
BA_ "NmStationAddress" BU_ ClimateControl1 25;
BA_ "NmJ1939Function" BU_ ClimateControl1 21;
BA_ "NmStationAddress" BU_ TripRecorder 24;
BA_ "NmJ1939Function" BU_ TripRecorder 20;
BA_ "NmStationAddress" BU_ InstrumentCluster 23;
BA_ "NmJ1939Function" BU_ InstrumentCluster 19;
BA_ "NmStationAddress" BU_ SuspensionDriveAxle2 22;
BA_ "NmJ1939Function" BU_ SuspensionDriveAxle2 18;
BA_ "NmJ1939FunctionInstance" BU_ SuspensionDriveAxle2 1;
BA_ "NmStationAddress" BU_ SuspensionDriveAxle1 21;
BA_ "NmJ1939Function" BU_ SuspensionDriveAxle1 18;
BA_ "NmStationAddress" BU_ SuspensionSteerAxle 20;
BA_ "NmJ1939Function" BU_ SuspensionSteerAxle 17;
BA_ "NmStationAddress" BU_ SteeringController 19;
BA_ "NmJ1939Function" BU_ SteeringController 16;
BA_ "NmStationAddress" BU_ FuelSystem 18;
BA_ "NmJ1939Function" BU_ FuelSystem 15;
BA_ "NmStationAddress" BU_ CruiseControl 17;
BA_ "NmJ1939Function" BU_ CruiseControl 14;
BA_ "NmStationAddress" BU_ RetarderDriveline 16;
BA_ "NmJ1939Function" BU_ RetarderDriveline 13;
BA_ "NmStationAddress" BU_ RetarderEngine 15;
BA_ "NmJ1939Function" BU_ RetarderEngine 12;
BA_ "NmStationAddress" BU_ BrakesDriveAxle2 14;
BA_ "NmJ1939Function" BU_ BrakesDriveAxle2 11;
BA_ "NmJ1939FunctionInstance" BU_ BrakesDriveAxle2 1;
BA_ "NmStationAddress" BU_ BrakesDriveAxle1 13;
BA_ "NmJ1939Function" BU_ BrakesDriveAxle1 11;
BA_ "NmStationAddress" BU_ BrakesSystemController 11;
BA_ "NmJ1939Function" BU_ BrakesSystemController 9;
BA_ "NmStationAddress" BU_ BrakesSteerAxle 12;
BA_ "NmJ1939Function" BU_ BrakesSteerAxle 10;
BA_ "NmStationAddress" BU_ AxleDrive2 10;
BA_ "NmJ1939Function" BU_ AxleDrive2 8;
BA_ "NmJ1939FunctionInstance" BU_ AxleDrive2 1;
BA_ "NmStationAddress" BU_ AxleDrive1 9;
BA_ "NmJ1939Function" BU_ AxleDrive1 8;
BA_ "NmStationAddress" BU_ AxleSteering 8;
BA_ "NmJ1939Function" BU_ AxleSteering 7;
BA_ "NmStationAddress" BU_ PowerTakeOff 7;
BA_ "NmJ1939Function" BU_ PowerTakeOff 6;
BA_ "NmStationAddress" BU_ ShiftConsoleSecondary 6;
BA_ "NmJ1939Function" BU_ ShiftConsoleSecondary 5;
BA_ "NmJ1939FunctionInstance" BU_ ShiftConsoleSecondary 1;
BA_ "NmStationAddress" BU_ ShiftConsolePrimary 5;
BA_ "NmJ1939Function" BU_ ShiftConsolePrimary 5;
BA_ "NmStationAddress" BU_ Transmission2 4;
BA_ "NmJ1939Function" BU_ Transmission2 3;
BA_ "NmJ1939ECUInstance" BU_ Transmission2 1;
BA_ "NmStationAddress" BU_ Transmission1 3;
BA_ "NmJ1939Function" BU_ Transmission1 3;
BA_ "NmStationAddress" BU_ Engine2 1;
BA_ "NmJ1939FunctionInstance" BU_ Engine2 1;
BA_ "NmStationAddress" BU_ Engine1 0;
BA_ "GenMsgCycleTime" BO_ 2565935153 1000;
BA_ "GenMsgSendType" BO_ 2565935153 0;
BA_ "GenMsgCycleTime" BO_ 2565935127 1000;
BA_ "GenMsgSendType" BO_ 2565935127 0;
BA_ "GenMsgCycleTime" BO_ 2565935121 1000;
BA_ "GenMsgSendType" BO_ 2565935121 0;
BA_ "GenMsgCycleTime" BO_ 2565935115 1000;
BA_ "GenMsgSendType" BO_ 2565935115 0;
BA_ "GenMsgCycleTime" BO_ 2565935104 1000;
BA_ "GenMsgSendType" BO_ 2565935104 0;
BA_ "GenMsgCycleTime" BO_ 2565935358 1000;
BA_ "GenMsgSendType" BO_ 2565935358 0;
BA_ "GenMsgSendType" BO_ 2566847025 0;
BA_ "GenMsgCycleTime" BO_ 2566847025 1000;
BA_ "GenMsgSendType" BO_ 2566847009 0;
BA_ "GenMsgCycleTime" BO_ 2566847009 1000;
BA_ "GenMsgSendType" BO_ 2566846999 0;
BA_ "GenMsgCycleTime" BO_ 2566846999 1000;
BA_ "GenMsgSendType" BO_ 2566846987 0;
BA_ "GenMsgCycleTime" BO_ 2566846987 1000;
BA_ "GenMsgSendType" BO_ 2566846976 0;
BA_ "GenMsgCycleTime" BO_ 2566846976 1000;
BA_ "GenMsgCycleTime" BO_ 2566827569 1000;
BA_ "GenMsgSendType" BO_ 2566827569 0;
BA_ "GenMsgSendType" BO_ 2432593706 0;
BA_ "GenMsgCycleTime" BO_ 2432593706 100;
BA_ "GenMsgSendType" BO_ 2432593675 0;
BA_ "GenMsgCycleTime" BO_ 2432593675 100;
BA_ "GenMsgSendType" BO_ 2566759473 0;
BA_ "GenMsgCycleTime" BO_ 2566759473 100;
BA_ "GenMsgSendType" BO_ 2566759463 0;
BA_ "GenMsgCycleTime" BO_ 2566759463 100;
BA_ "GenMsgSendType" BO_ 2566759427 0;
BA_ "GenMsgCycleTime" BO_ 2566759427 100;
BA_ "GenMsgCycleTime" BO_ 2566846211 1000;
BA_ "GenMsgSendType" BO_ 2566846211 0;
BA_ "GenMsgSendType" BO_ 2566844721 0;
BA_ "GenMsgCycleTime" BO_ 2566844721 100;
BA_ "GenMsgSendType" BO_ 2566844711 0;
BA_ "GenMsgCycleTime" BO_ 2566844711 100;
BA_ "SigType" SG_ 3221225472 TrailerWeight 1;
BA_ "SPN" SG_ 3221225472 TrailerWeight 180;
BA_ "SigType" SG_ 3221225472 ReferenceTirePressSetting 1;
BA_ "SPN" SG_ 3221225472 ReferenceTirePressSetting 3193;
BA_ "SigType" SG_ 3221225472 ReferenceTirePress 1;
BA_ "SPN" SG_ 3221225472 ReferenceTirePress 3191;
BA_ "SigType" SG_ 3221225472 TirePressThresholdDetection 4;
BA_ "SPN" SG_ 3221225472 TirePressThresholdDetection 2587;
BA_ "SigType" SG_ 3221225472 TireAirLeakageRate 1;
BA_ "SPN" SG_ 3221225472 TireAirLeakageRate 2586;
BA_ "SigType" SG_ 3221225472 CTIWheelEndElectricalFault 4;
BA_ "SPN" SG_ 3221225472 CTIWheelEndElectricalFault 1697;
BA_ "SigType" SG_ 3221225472 CTITireStatus 4;
BA_ "SPN" SG_ 3221225472 CTITireStatus 1698;
BA_ "SigType" SG_ 3221225472 CTIWheelSensorStatus 4;
BA_ "SPN" SG_ 3221225472 CTIWheelSensorStatus 1699;
BA_ "SigType" SG_ 3221225472 TireTemp 1;
BA_ "SPN" SG_ 3221225472 TireTemp 242;
BA_ "SigType" SG_ 3221225472 TirePress 1;
BA_ "SPN" SG_ 3221225472 TirePress 241;
BA_ "SigType" SG_ 3221225472 DTC2 7;
BA_ "SigType" SG_ 3221225472 DTC3 7;
BA_ "SigType" SG_ 3221225472 DTC4 7;
BA_ "SigType" SG_ 3221225472 SPNConversionMethod_DTC2 7;
BA_ "SigType" SG_ 3221225472 FMI_DTC6 7;
BA_ "SigType" SG_ 3221225472 SPNConversionMethod_DTC7 7;
BA_ "SigType" SG_ 3221225472 SPN3_DTC7 7;
BA_ "SPN" SG_ 2565935153 BrakeSwitch2 603;
BA_ "SigType" SG_ 2565935153 BrakeSwitch2 4;
BA_ "SPN" SG_ 2565935153 DemandedBrakeApplicationPressure 8484;
BA_ "SigType" SG_ 2565935153 DemandedBrakeApplicationPressure 1;
BA_ "SPN" SG_ 2565935127 BrakeSwitch2 603;
BA_ "SigType" SG_ 2565935127 BrakeSwitch2 4;
BA_ "SPN" SG_ 2565935127 DemandedBrakeApplicationPressure 8484;
BA_ "SigType" SG_ 2565935127 DemandedBrakeApplicationPressure 1;
BA_ "SPN" SG_ 2565935121 BrakeSwitch2 603;
BA_ "SigType" SG_ 2565935121 BrakeSwitch2 4;
BA_ "SPN" SG_ 2565935121 DemandedBrakeApplicationPressure 8484;
BA_ "SigType" SG_ 2565935121 DemandedBrakeApplicationPressure 1;
BA_ "SPN" SG_ 2565935115 BrakeSwitch2 603;
BA_ "SigType" SG_ 2565935115 BrakeSwitch2 4;
BA_ "SPN" SG_ 2565935115 DemandedBrakeApplicationPressure 8484;
BA_ "SigType" SG_ 2565935115 DemandedBrakeApplicationPressure 1;
BA_ "SPN" SG_ 2565935104 BrakeSwitch2 603;
BA_ "SigType" SG_ 2565935104 BrakeSwitch2 4;
BA_ "SPN" SG_ 2565935104 DemandedBrakeApplicationPressure 8484;
BA_ "SigType" SG_ 2565935104 DemandedBrakeApplicationPressure 1;
BA_ "SigType" SG_ 2566705667 DM54_SPNConversionMethod_DTC8 1;
BA_ "SigType" SG_ 2566705667 DM54_OccurenceCount_DTC8 1;
BA_ "SigType" SG_ 2566705667 DM54_SPN3_DTC8 1;
BA_ "SigType" SG_ 2566705667 DM54_FMI_DTC8 1;
BA_ "SigType" SG_ 2566705667 DM54_SPN2_DTC8 1;
BA_ "SigType" SG_ 2566705667 DM54_SPN1_DTC8 1;
BA_ "SigType" SG_ 2566705667 DM54_SPNConversionMethod_DTC7 1;
BA_ "SigType" SG_ 2566705667 DM54_OccurenceCount_DTC7 1;
BA_ "SigType" SG_ 2566705667 DM54_SPN3_DTC7 1;
BA_ "SigType" SG_ 2566705667 DM54_FMI_DTC7 1;
BA_ "SigType" SG_ 2566705667 DM54_SPN2_DTC7 1;
BA_ "SigType" SG_ 2566705667 DM54_SPN1_DTC7 1;
BA_ "SigType" SG_ 2566705667 DM54_SPNConversionMethod_DTC6 1;
BA_ "SigType" SG_ 2566705667 DM54_OccurenceCount_DTC6 1;
BA_ "SigType" SG_ 2566705667 DM54_SPN3_DTC6 1;
BA_ "SigType" SG_ 2566705667 DM54_FMI_DTC6 1;
BA_ "SigType" SG_ 2566705667 DM54_SPN2_DTC6 1;
BA_ "SigType" SG_ 2566705667 DM54_SPN1_DTC6 1;
BA_ "SigType" SG_ 2566705667 DM54_SPNConversionMethod_DTC5 1;
BA_ "SigType" SG_ 2566705667 DM54_OccurenceCount_DTC5 1;
BA_ "SigType" SG_ 2566705667 DM54_SPN3_DTC5 1;
BA_ "SigType" SG_ 2566705667 DM54_FMI_DTC5 1;
BA_ "SigType" SG_ 2566705667 DM54_SPN2_DTC5 1;
BA_ "SigType" SG_ 2566705667 DM54_SPN1_DTC5 1;
BA_ "SigType" SG_ 2566705667 DM54_SPNConversionMethod_DTC4 1;
BA_ "SigType" SG_ 2566705667 DM54_OccurenceCount_DTC4 1;
BA_ "SigType" SG_ 2566705667 DM54_SPN3_DTC4 1;
BA_ "SigType" SG_ 2566705667 DM54_FMI_DTC4 1;
BA_ "SigType" SG_ 2566705667 DM54_SPN2_DTC4 1;
BA_ "SigType" SG_ 2566705667 DM54_SPN1_DTC4 1;
BA_ "SigType" SG_ 2566705667 DM54_SPNConversionMethod_DTC3 1;
BA_ "SigType" SG_ 2566705667 DM54_OccurenceCount_DTC3 1;
BA_ "SigType" SG_ 2566705667 DM54_SPN3_DTC3 1;
BA_ "SigType" SG_ 2566705667 DM54_FMI_DTC3 1;
BA_ "SigType" SG_ 2566705667 DM54_SPN2_DTC3 1;
BA_ "SigType" SG_ 2566705667 DM54_SPN1_DTC3 1;
BA_ "SigType" SG_ 2566705667 DM54_SPNConversionMethod_DTC2 1;
BA_ "SigType" SG_ 2566705667 DM54_OccurenceCount_DTC2 1;
BA_ "SigType" SG_ 2566705667 DM54_SPN3_DTC2 1;
BA_ "SigType" SG_ 2566705667 DM54_FMI_DTC2 1;
BA_ "SigType" SG_ 2566705667 DM54_SPN2_DTC2 1;
BA_ "SigType" SG_ 2566705667 DM54_SPN1_DTC2 1;
BA_ "SigType" SG_ 2566705667 DM54_SPNConversionMethod_DTC1 1;
BA_ "SigType" SG_ 2566705667 DM54_OccurenceCount_DTC1 1;
BA_ "SigType" SG_ 2566705667 DM54_SPN3_DTC1 1;
BA_ "SigType" SG_ 2566705667 DM54_FMI_DTC1 1;
BA_ "SigType" SG_ 2566705667 DM54_SPN2_DTC1 1;
BA_ "SigType" SG_ 2566705667 DM54_SPN1_DTC1 1;
BA_ "SigType" SG_ 2566705667 DM54FlashMalfuncIndicatorLamp 4;
BA_ "SigType" SG_ 2566705667 DM54FlashRedStopLamp 4;
BA_ "SigType" SG_ 2566705667 DM54FlashAmberWarningLamp 4;
BA_ "SigType" SG_ 2566705667 DM54FlashProtectLamp 4;
BA_ "SigType" SG_ 2566705667 DM54MalfunctionIndicateLampState 4;
BA_ "SigType" SG_ 2566705667 DM54RedStopLampState 4;
BA_ "SigType" SG_ 2566705667 DM54AmberWarningLampStatus 4;
BA_ "SigType" SG_ 2566705667 DM54ProtectLampStatus 4;
BA_ "SPN" SG_ 2566705667 DM54ProtectLampStatus 987;
BA_ "SigType" SG_ 2566705411 DM53_SPNConversionMethod_DTC8 1;
BA_ "SigType" SG_ 2566705411 DM53_OccurenceCount_DTC8 1;
BA_ "SigType" SG_ 2566705411 DM53_SPN3_DTC8 1;
BA_ "SigType" SG_ 2566705411 DM53_FMI_DTC8 1;
BA_ "SigType" SG_ 2566705411 DM53_SPN2_DTC8 1;
BA_ "SigType" SG_ 2566705411 DM53_SPN1_DTC8 1;
BA_ "SigType" SG_ 2566705411 DM53_SPNConversionMethod_DTC7 1;
BA_ "SigType" SG_ 2566705411 DM53_OccurenceCount_DTC7 1;
BA_ "SigType" SG_ 2566705411 DM53_SPN3_DTC7 1;
BA_ "SigType" SG_ 2566705411 DM53_FMI_DTC7 1;
BA_ "SigType" SG_ 2566705411 DM53_SPN2_DTC7 1;
BA_ "SigType" SG_ 2566705411 DM53_SPN1_DTC7 1;
BA_ "SigType" SG_ 2566705411 DM53_SPNConversionMethod_DTC6 1;
BA_ "SigType" SG_ 2566705411 DM53_OccurenceCount_DTC6 1;
BA_ "SigType" SG_ 2566705411 DM53_SPN3_DTC6 1;
BA_ "SigType" SG_ 2566705411 DM53_FMI_DTC6 1;
BA_ "SigType" SG_ 2566705411 DM53_SPN2_DTC6 1;
BA_ "SigType" SG_ 2566705411 DM53_SPN1_DTC6 1;
BA_ "SigType" SG_ 2566705411 DM53_SPNConversionMethod_DTC5 1;
BA_ "SigType" SG_ 2566705411 DM53_OccurenceCount_DTC5 1;
BA_ "SigType" SG_ 2566705411 DM53_SPN3_DTC5 1;
BA_ "SigType" SG_ 2566705411 DM53_FMI_DTC5 1;
BA_ "SigType" SG_ 2566705411 DM53_SPN2_DTC5 1;
BA_ "SigType" SG_ 2566705411 DM53_SPN1_DTC5 1;
BA_ "SigType" SG_ 2566705411 DM53_SPNConversionMethod_DTC4 1;
BA_ "SigType" SG_ 2566705411 DM53_OccurenceCount_DTC4 1;
BA_ "SigType" SG_ 2566705411 DM53_SPN3_DTC4 1;
BA_ "SigType" SG_ 2566705411 DM53_FMI_DTC4 1;
BA_ "SigType" SG_ 2566705411 DM53_SPN2_DTC4 1;
BA_ "SigType" SG_ 2566705411 DM53_SPN1_DTC4 1;
BA_ "SigType" SG_ 2566705411 DM53_SPNConversionMethod_DTC3 1;
BA_ "SigType" SG_ 2566705411 DM53_OccurenceCount_DTC3 1;
BA_ "SigType" SG_ 2566705411 DM53_SPN3_DTC3 1;
BA_ "SigType" SG_ 2566705411 DM53_FMI_DTC3 1;
BA_ "SigType" SG_ 2566705411 DM53_SPN2_DTC3 1;
BA_ "SigType" SG_ 2566705411 DM53_SPN1_DTC3 1;
BA_ "SigType" SG_ 2566705411 DM53_SPNConversionMethod_DTC2 1;
BA_ "SigType" SG_ 2566705411 DM53_OccurenceCount_DTC2 1;
BA_ "SigType" SG_ 2566705411 DM53_SPN3_DTC2 1;
BA_ "SigType" SG_ 2566705411 DM53_FMI_DTC2 1;
BA_ "SigType" SG_ 2566705411 DM53_SPN2_DTC2 1;
BA_ "SigType" SG_ 2566705411 DM53_SPN1_DTC2 1;
BA_ "SigType" SG_ 2566705411 DM53_SPNConversionMethod_DTC1 1;
BA_ "SigType" SG_ 2566705411 DM53_OccurenceCount_DTC1 1;
BA_ "SigType" SG_ 2566705411 DM53_SPN3_DTC1 1;
BA_ "SigType" SG_ 2566705411 DM53_FMI_DTC1 1;
BA_ "SigType" SG_ 2566705411 DM53_SPN2_DTC1 1;
BA_ "SigType" SG_ 2566705411 DM53_SPN1_DTC1 1;
BA_ "SigType" SG_ 2566705411 DM53FlashMalfuncIndicatorLamp 4;
BA_ "SigType" SG_ 2566705411 DM53FlashRedStopLamp 4;
BA_ "SigType" SG_ 2566705411 DM53FlashAmberWarningLamp 4;
BA_ "SigType" SG_ 2566705411 DM53FlashProtectLamp 4;
BA_ "SigType" SG_ 2566705411 DM53MalfunctionIndicateLampState 4;
BA_ "SigType" SG_ 2566705411 DM53RedStopLampState 4;
BA_ "SigType" SG_ 2566705411 DM53AmberWarningLampStatus 4;
BA_ "SigType" SG_ 2566705411 DM53ProtectLampStatus 4;
BA_ "SPN" SG_ 2566705411 DM53ProtectLampStatus 987;
BA_ "SPN" SG_ 2565935358 BrakeSwitch2 603;
BA_ "SigType" SG_ 2565935358 BrakeSwitch2 4;
BA_ "SPN" SG_ 2565935358 DemandedBrakeApplicationPressure 8484;
BA_ "SigType" SG_ 2565935358 DemandedBrakeApplicationPressure 1;
BA_ "SigType" SG_ 2566847025 ParkingBrakeRedWarningSignal 4;
BA_ "SPN" SG_ 2566847025 ParkingBrakeRedWarningSignal 3557;
BA_ "SigType" SG_ 2566847025 ParkBrakeReleaseInhibitStatus 4;
BA_ "SPN" SG_ 2566847025 ParkBrakeReleaseInhibitStatus 3808;
BA_ "SigType" SG_ 2566847025 ParkingBrakeActuator 4;
BA_ "SPN" SG_ 2566847025 ParkingBrakeActuator 619;
BA_ "SigType" SG_ 2566847025 BrakeSecondPress 1;
BA_ "SPN" SG_ 2566847025 BrakeSecondPress 118;
BA_ "SigType" SG_ 2566847025 BrakePrimaryPress 1;
BA_ "SPN" SG_ 2566847025 BrakePrimaryPress 117;
BA_ "SigType" SG_ 2566847025 BrakeAppPress 1;
BA_ "SPN" SG_ 2566847025 BrakeAppPress 116;
BA_ "SigType" SG_ 2566847009 ParkingBrakeRedWarningSignal 4;
BA_ "SPN" SG_ 2566847009 ParkingBrakeRedWarningSignal 3557;
BA_ "SigType" SG_ 2566847009 ParkBrakeReleaseInhibitStatus 4;
BA_ "SPN" SG_ 2566847009 ParkBrakeReleaseInhibitStatus 3808;
BA_ "SigType" SG_ 2566847009 ParkingBrakeActuator 4;
BA_ "SPN" SG_ 2566847009 ParkingBrakeActuator 619;
BA_ "SigType" SG_ 2566847009 BrakeSecondPress 1;
BA_ "SPN" SG_ 2566847009 BrakeSecondPress 118;
BA_ "SigType" SG_ 2566847009 BrakePrimaryPress 1;
BA_ "SPN" SG_ 2566847009 BrakePrimaryPress 117;
BA_ "SigType" SG_ 2566847009 BrakeAppPress 1;
BA_ "SPN" SG_ 2566847009 BrakeAppPress 116;
BA_ "SigType" SG_ 2566846999 ParkingBrakeRedWarningSignal 4;
BA_ "SPN" SG_ 2566846999 ParkingBrakeRedWarningSignal 3557;
BA_ "SigType" SG_ 2566846999 ParkBrakeReleaseInhibitStatus 4;
BA_ "SPN" SG_ 2566846999 ParkBrakeReleaseInhibitStatus 3808;
BA_ "SigType" SG_ 2566846999 ParkingBrakeActuator 4;
BA_ "SPN" SG_ 2566846999 ParkingBrakeActuator 619;
BA_ "SigType" SG_ 2566846999 BrakeSecondPress 1;
BA_ "SPN" SG_ 2566846999 BrakeSecondPress 118;
BA_ "SigType" SG_ 2566846999 BrakePrimaryPress 1;
BA_ "SPN" SG_ 2566846999 BrakePrimaryPress 117;
BA_ "SigType" SG_ 2566846999 BrakeAppPress 1;
BA_ "SPN" SG_ 2566846999 BrakeAppPress 116;
BA_ "SigType" SG_ 2566846987 ParkingBrakeRedWarningSignal 4;
BA_ "SPN" SG_ 2566846987 ParkingBrakeRedWarningSignal 3557;
BA_ "SigType" SG_ 2566846987 ParkBrakeReleaseInhibitStatus 4;
BA_ "SPN" SG_ 2566846987 ParkBrakeReleaseInhibitStatus 3808;
BA_ "SigType" SG_ 2566846987 ParkingBrakeActuator 4;
BA_ "SPN" SG_ 2566846987 ParkingBrakeActuator 619;
BA_ "SigType" SG_ 2566846987 BrakeSecondPress 1;
BA_ "SPN" SG_ 2566846987 BrakeSecondPress 118;
BA_ "SigType" SG_ 2566846987 BrakePrimaryPress 1;
BA_ "SPN" SG_ 2566846987 BrakePrimaryPress 117;
BA_ "SigType" SG_ 2566846987 BrakeAppPress 1;
BA_ "SPN" SG_ 2566846987 BrakeAppPress 116;
BA_ "SigType" SG_ 2566846976 ParkingBrakeRedWarningSignal 4;
BA_ "SPN" SG_ 2566846976 ParkingBrakeRedWarningSignal 3557;
BA_ "SigType" SG_ 2566846976 ParkBrakeReleaseInhibitStatus 4;
BA_ "SPN" SG_ 2566846976 ParkBrakeReleaseInhibitStatus 3808;
BA_ "SigType" SG_ 2566846976 ParkingBrakeActuator 4;
BA_ "SPN" SG_ 2566846976 ParkingBrakeActuator 619;
BA_ "SigType" SG_ 2566846976 BrakeSecondPress 1;
BA_ "SPN" SG_ 2566846976 BrakeSecondPress 118;
BA_ "SigType" SG_ 2566846976 BrakePrimaryPress 1;
BA_ "SPN" SG_ 2566846976 BrakePrimaryPress 117;
BA_ "SigType" SG_ 2566846976 BrakeAppPress 1;
BA_ "SPN" SG_ 2566846976 BrakeAppPress 116;
BA_ "SPN" SG_ 2566827569 PowertrainCircuitAirSupplyPress 6305;
BA_ "SigType" SG_ 2566827569 PowertrainCircuitAirSupplyPress 1;
BA_ "SigType" SG_ 2566827569 ServiceBrakeCircuit2AirPress 1;
BA_ "SPN" SG_ 2566827569 ServiceBrakeCircuit2AirPress 1088;
BA_ "SigType" SG_ 2566827569 ServiceBrakeCircuit1AirPress 1;
BA_ "SPN" SG_ 2566827569 ServiceBrakeCircuit1AirPress 1087;
BA_ "SigType" SG_ 2566827569 AirCompressorStatus 4;
BA_ "SPN" SG_ 2566827569 AirCompressorStatus 1351;
BA_ "SigType" SG_ 2566827569 AirSuspensionSupplyPress 1;
BA_ "SPN" SG_ 2566827569 AirSuspensionSupplyPress 1090;
BA_ "SigType" SG_ 2566827569 AuxEquipmentSupplyPress 1;
BA_ "SPN" SG_ 2566827569 AuxEquipmentSupplyPress 1089;
BA_ "SigType" SG_ 2566827569 ParkingAnd_OrTrailerAirPress 1;
BA_ "SPN" SG_ 2566827569 ParkingAnd_OrTrailerAirPress 1086;
BA_ "SigType" SG_ 2566827569 PneumaticSupplyPress 1;
BA_ "SPN" SG_ 2566827569 PneumaticSupplyPress 46;
BA_ "SigType" SG_ 2432593706 ForwardCollisionWarning 4;
BA_ "SPN" SG_ 2432593706 ForwardCollisionWarning 5022;
BA_ "SigType" SG_ 2432593706 ACCDistanceAlertSignal 4;
BA_ "SPN" SG_ 2432593706 ACCDistanceAlertSignal 1796;
BA_ "SigType" SG_ 2432593706 ACCSystemShutoffWarning 4;
BA_ "SPN" SG_ 2432593706 ACCSystemShutoffWarning 1797;
BA_ "SigType" SG_ 2432593706 ACCTargetDetected 4;
BA_ "SPN" SG_ 2432593706 ACCTargetDetected 1798;
BA_ "SigType" SG_ 2432593706 RoadCurvature 1;
BA_ "SPN" SG_ 2432593706 RoadCurvature 1591;
BA_ "SPN" SG_ 2432593706 AdptveCruiseCtrlSetDistanceMode 1589;
BA_ "SPN" SG_ 2432593706 AdaptiveCruiseCtrlMode 1590;
BA_ "SigType" SG_ 2432593706 AdaptiveCruiseCtrlSetSpeed 1;
BA_ "SPN" SG_ 2432593706 AdaptiveCruiseCtrlSetSpeed 1588;
BA_ "SigType" SG_ 2432593706 DistanceToForwardVehicle 1;
BA_ "SPN" SG_ 2432593706 DistanceToForwardVehicle 1587;
BA_ "SigType" SG_ 2432593706 SpeedOfForwardVehicle 1;
BA_ "SPN" SG_ 2432593706 SpeedOfForwardVehicle 1586;
BA_ "SigType" SG_ 2432593675 ForwardCollisionWarning 4;
BA_ "SPN" SG_ 2432593675 ForwardCollisionWarning 5022;
BA_ "SigType" SG_ 2432593675 ACCDistanceAlertSignal 4;
BA_ "SPN" SG_ 2432593675 ACCDistanceAlertSignal 1796;
BA_ "SigType" SG_ 2432593675 ACCSystemShutoffWarning 4;
BA_ "SPN" SG_ 2432593675 ACCSystemShutoffWarning 1797;
BA_ "SigType" SG_ 2432593675 ACCTargetDetected 4;
BA_ "SPN" SG_ 2432593675 ACCTargetDetected 1798;
BA_ "SigType" SG_ 2432593675 RoadCurvature 1;
BA_ "SPN" SG_ 2432593675 RoadCurvature 1591;
BA_ "SPN" SG_ 2432593675 AdptveCruiseCtrlSetDistanceMode 1589;
BA_ "SPN" SG_ 2432593675 AdaptiveCruiseCtrlMode 1590;
BA_ "SigType" SG_ 2432593675 AdaptiveCruiseCtrlSetSpeed 1;
BA_ "SPN" SG_ 2432593675 AdaptiveCruiseCtrlSetSpeed 1588;
BA_ "SigType" SG_ 2432593675 DistanceToForwardVehicle 1;
BA_ "SPN" SG_ 2432593675 DistanceToForwardVehicle 1587;
BA_ "SigType" SG_ 2432593675 SpeedOfForwardVehicle 1;
BA_ "SPN" SG_ 2432593675 SpeedOfForwardVehicle 1586;
BA_ "SigType" SG_ 2566840617 PercentTorqueAtPeakTorquePoint5 1;
BA_ "SPN" SG_ 2566840617 PercentTorqueAtPeakTorquePoint5 555;
BA_ "SigType" SG_ 2566840617 ReferenceRetarderTorque 1;
BA_ "SPN" SG_ 2566840617 ReferenceRetarderTorque 556;
BA_ "SigType" SG_ 2566840617 RetarderSpeedAtPeakTorquePoint5 1;
BA_ "SPN" SG_ 2566840617 RetarderSpeedAtPeakTorquePoint5 547;
BA_ "SigType" SG_ 2566840617 PercentTorqueAtPoint4 1;
BA_ "SPN" SG_ 2566840617 PercentTorqueAtPoint4 554;
BA_ "SigType" SG_ 2566840617 RetarderSpeedAtPoint4 1;
BA_ "SPN" SG_ 2566840617 RetarderSpeedAtPoint4 550;
BA_ "SigType" SG_ 2566840617 PercentTorqueAtPoint3 1;
BA_ "SPN" SG_ 2566840617 PercentTorqueAtPoint3 553;
BA_ "SigType" SG_ 2566840617 RetarderSpeedAtPoint3 1;
BA_ "SPN" SG_ 2566840617 RetarderSpeedAtPoint3 549;
BA_ "SigType" SG_ 2566840617 PercentTorqueAtMaxSpeedPoint2 1;
BA_ "SPN" SG_ 2566840617 PercentTorqueAtMaxSpeedPoint2 552;
BA_ "SigType" SG_ 2566840617 MaxRetarderSpeedPoint2 1;
BA_ "SPN" SG_ 2566840617 MaxRetarderSpeedPoint2 548;
BA_ "SigType" SG_ 2566840617 PercentTorqueAtIdlePoint1 1;
BA_ "SPN" SG_ 2566840617 PercentTorqueAtIdlePoint1 551;
BA_ "SigType" SG_ 2566840617 RetarderSpeedAtIdlePoint1 1;
BA_ "SPN" SG_ 2566840617 RetarderSpeedAtIdlePoint1 546;
BA_ "SigType" SG_ 2566840617 RetarderCtrlMethod 1;
BA_ "SPN" SG_ 2566840617 RetarderCtrlMethod 557;
BA_ "SigType" SG_ 2566840617 RetarderLocation 4;
BA_ "SPN" SG_ 2566840617 RetarderLocation 902;
BA_ "SigType" SG_ 2566840617 RetarderType 4;
BA_ "SPN" SG_ 2566840617 RetarderType 901;
BA_ "SigType" SG_ 2566840591 PercentTorqueAtPeakTorquePoint5 1;
BA_ "SPN" SG_ 2566840591 PercentTorqueAtPeakTorquePoint5 555;
BA_ "SigType" SG_ 2566840591 ReferenceRetarderTorque 1;
BA_ "SPN" SG_ 2566840591 ReferenceRetarderTorque 556;
BA_ "SigType" SG_ 2566840591 RetarderSpeedAtPeakTorquePoint5 1;
BA_ "SPN" SG_ 2566840591 RetarderSpeedAtPeakTorquePoint5 547;
BA_ "SigType" SG_ 2566840591 PercentTorqueAtPoint4 1;
BA_ "SPN" SG_ 2566840591 PercentTorqueAtPoint4 554;
BA_ "SigType" SG_ 2566840591 RetarderSpeedAtPoint4 1;
BA_ "SPN" SG_ 2566840591 RetarderSpeedAtPoint4 550;
BA_ "SigType" SG_ 2566840591 PercentTorqueAtPoint3 1;
BA_ "SPN" SG_ 2566840591 PercentTorqueAtPoint3 553;
BA_ "SigType" SG_ 2566840591 RetarderSpeedAtPoint3 1;
BA_ "SPN" SG_ 2566840591 RetarderSpeedAtPoint3 549;
BA_ "SigType" SG_ 2566840591 PercentTorqueAtMaxSpeedPoint2 1;
BA_ "SPN" SG_ 2566840591 PercentTorqueAtMaxSpeedPoint2 552;
BA_ "SigType" SG_ 2566840591 MaxRetarderSpeedPoint2 1;
BA_ "SPN" SG_ 2566840591 MaxRetarderSpeedPoint2 548;
BA_ "SigType" SG_ 2566840591 PercentTorqueAtIdlePoint1 1;
BA_ "SPN" SG_ 2566840591 PercentTorqueAtIdlePoint1 551;
BA_ "SigType" SG_ 2566840591 RetarderSpeedAtIdlePoint1 1;
BA_ "SPN" SG_ 2566840591 RetarderSpeedAtIdlePoint1 546;
BA_ "SigType" SG_ 2566840591 RetarderCtrlMethod 1;
BA_ "SPN" SG_ 2566840591 RetarderCtrlMethod 557;
BA_ "SigType" SG_ 2566840591 RetarderLocation 4;
BA_ "SPN" SG_ 2566840591 RetarderLocation 902;
BA_ "SigType" SG_ 2566840591 RetarderType 4;
BA_ "SPN" SG_ 2566840591 RetarderType 901;
BA_ "SigType" SG_ 2559049726 EngShutdownCommand 4;
BA_ "SPN" SG_ 2559049726 EngShutdownCommand 8614;
BA_ "SPN" SG_ 2559049726 EngineFuelingDesiredReason 7889;
BA_ "SigType" SG_ 2559049726 EngineFuelingDesiredReason 1;
BA_ "SPN" SG_ 2559049726 EngineFuelingNotDesiredReason 7855;
BA_ "SigType" SG_ 2559049726 EngineFuelingNotDesiredReason 1;
BA_ "SPN" SG_ 2559049726 TransIdleGovernorFuelingInhibit 7829;
BA_ "SigType" SG_ 2559049726 TransIdleGovernorFuelingInhibit 4;
BA_ "SPN" SG_ 2559049726 EngineGaseousFuelSupDesiredPress 7789;
BA_ "SigType" SG_ 2559049726 EngineGaseousFuelSupDesiredPress 1;
BA_ "SPN" SG_ 2559049726 RequestedFuelType 6317;
BA_ "SigType" SG_ 2559049726 RequestedFuelType 1;
BA_ "SPN" SG_ 2559049726 EngineGaseousFuelUsageInhibited 6833;
BA_ "SigType" SG_ 2559049726 EngineGaseousFuelUsageInhibited 4;
BA_ "SPN" SG_ 2559049726 DesiredEngineFuelingState 5793;
BA_ "SigType" SG_ 2559049726 DesiredEngineFuelingState 4;
BA_ "SigType" SG_ 2566759473 EnggmntSttusTransInputShaftPTO1 4;
BA_ "SPN" SG_ 2566759473 EnggmntSttusTransInputShaftPTO1 3460;
BA_ "SigType" SG_ 2566759473 EnggmntSttusTransInputShaftPTO2 4;
BA_ "SPN" SG_ 2566759473 EnggmntSttusTransInputShaftPTO2 3461;
BA_ "SigType" SG_ 2566759473 EnggmntSttusTransOutputShaftPTO 4;
BA_ "SPN" SG_ 2566759473 EnggmntSttusTransOutputShaftPTO 3462;
BA_ "SigType" SG_ 2566759473 EnggmntSttsTrnsfrCsOtptShaftPTO 4;
BA_ "SPN" SG_ 2566759473 EnggmntSttsTrnsfrCsOtptShaftPTO 3463;
BA_ "SigType" SG_ 2566759473 EnggmntCnsntTransInputShaftPTO1 4;
BA_ "SPN" SG_ 2566759473 EnggmntCnsntTransInputShaftPTO1 3456;
BA_ "SigType" SG_ 2566759473 EnggmntCnsntTransInputShaftPTO2 4;
BA_ "SPN" SG_ 2566759473 EnggmntCnsntTransInputShaftPTO2 3457;
BA_ "SigType" SG_ 2566759473 EnggmntCnsntTransOutputShaftPTO 4;
BA_ "SPN" SG_ 2566759473 EnggmntCnsntTransOutputShaftPTO 3458;
BA_ "SigType" SG_ 2566759473 EnggmntCnsntTrnsfrCsOtptShftPTO 4;
BA_ "SPN" SG_ 2566759473 EnggmntCnsntTrnsfrCsOtptShftPTO 3459;
BA_ "SigType" SG_ 2566759473 EnableSwitchTransInputShaftPTO1 4;
BA_ "SPN" SG_ 2566759473 EnableSwitchTransInputShaftPTO1 3452;
BA_ "SigType" SG_ 2566759473 EnableSwitchTransInputShaftPTO2 4;
BA_ "SPN" SG_ 2566759473 EnableSwitchTransInputShaftPTO2 3453;
BA_ "SigType" SG_ 2566759473 EnableSwitchTransOutputShaftPTO 4;
BA_ "SPN" SG_ 2566759473 EnableSwitchTransOutputShaftPTO 3454;
BA_ "SigType" SG_ 2566759473 EnblSwtchTrnsfrCsOutputShaftPTO 4;
BA_ "SPN" SG_ 2566759473 EnblSwtchTrnsfrCsOutputShaftPTO 3455;
BA_ "SigType" SG_ 2566759473 EnggmntSttsPTOEngAccssoryDrive2 4;
BA_ "SPN" SG_ 2566759473 EnggmntSttsPTOEngAccssoryDrive2 3947;
BA_ "SigType" SG_ 2566759473 EnggmntSttsPTOEngAccssoryDrive1 4;
BA_ "SPN" SG_ 2566759473 EnggmntSttsPTOEngAccssoryDrive1 3944;
BA_ "SigType" SG_ 2566759473 EnggmntCnsntPTOEngAccssryDrive2 4;
BA_ "SPN" SG_ 2566759473 EnggmntCnsntPTOEngAccssryDrive2 3946;
BA_ "SigType" SG_ 2566759473 EnggmntCnsntPTOEngAccssryDrive1 4;
BA_ "SPN" SG_ 2566759473 EnggmntCnsntPTOEngAccssryDrive1 3943;
BA_ "SigType" SG_ 2566759473 EngagementStatusPTOEngFlywheel 4;
BA_ "SPN" SG_ 2566759473 EngagementStatusPTOEngFlywheel 3941;
BA_ "SigType" SG_ 2566759473 EngagementConsentPTOEngFlywheel 4;
BA_ "SPN" SG_ 2566759473 EngagementConsentPTOEngFlywheel 3940;
BA_ "SigType" SG_ 2566759473 EnblSwitchPTOEngAccessoryDrive2 4;
BA_ "SPN" SG_ 2566759473 EnblSwitchPTOEngAccessoryDrive2 3945;
BA_ "SigType" SG_ 2566759473 EnblSwitchPTOEngAccessoryDrive1 4;
BA_ "SPN" SG_ 2566759473 EnblSwitchPTOEngAccessoryDrive1 3942;
BA_ "SigType" SG_ 2566759473 EnableSwitchPTOEngFlywheel 4;
BA_ "SPN" SG_ 2566759473 EnableSwitchPTOEngFlywheel 3939;
BA_ "SigType" SG_ 2566759473 AtLeastOnePTOEngaged 4;
BA_ "SPN" SG_ 2566759473 AtLeastOnePTOEngaged 3948;
BA_ "SigType" SG_ 2566759463 EnggmntSttusTransInputShaftPTO1 4;
BA_ "SPN" SG_ 2566759463 EnggmntSttusTransInputShaftPTO1 3460;
BA_ "SigType" SG_ 2566759463 EnggmntSttusTransInputShaftPTO2 4;
BA_ "SPN" SG_ 2566759463 EnggmntSttusTransInputShaftPTO2 3461;
BA_ "SigType" SG_ 2566759463 EnggmntSttusTransOutputShaftPTO 4;
BA_ "SPN" SG_ 2566759463 EnggmntSttusTransOutputShaftPTO 3462;
BA_ "SigType" SG_ 2566759463 EnggmntSttsTrnsfrCsOtptShaftPTO 4;
BA_ "SPN" SG_ 2566759463 EnggmntSttsTrnsfrCsOtptShaftPTO 3463;
BA_ "SigType" SG_ 2566759463 EnggmntCnsntTransInputShaftPTO1 4;
BA_ "SPN" SG_ 2566759463 EnggmntCnsntTransInputShaftPTO1 3456;
BA_ "SigType" SG_ 2566759463 EnggmntCnsntTransInputShaftPTO2 4;
BA_ "SPN" SG_ 2566759463 EnggmntCnsntTransInputShaftPTO2 3457;
BA_ "SigType" SG_ 2566759463 EnggmntCnsntTransOutputShaftPTO 4;
BA_ "SPN" SG_ 2566759463 EnggmntCnsntTransOutputShaftPTO 3458;
BA_ "SigType" SG_ 2566759463 EnggmntCnsntTrnsfrCsOtptShftPTO 4;
BA_ "SPN" SG_ 2566759463 EnggmntCnsntTrnsfrCsOtptShftPTO 3459;
BA_ "SigType" SG_ 2566759463 EnableSwitchTransInputShaftPTO1 4;
BA_ "SPN" SG_ 2566759463 EnableSwitchTransInputShaftPTO1 3452;
BA_ "SigType" SG_ 2566759463 EnableSwitchTransInputShaftPTO2 4;
BA_ "SPN" SG_ 2566759463 EnableSwitchTransInputShaftPTO2 3453;
BA_ "SigType" SG_ 2566759463 EnableSwitchTransOutputShaftPTO 4;
BA_ "SPN" SG_ 2566759463 EnableSwitchTransOutputShaftPTO 3454;
BA_ "SigType" SG_ 2566759463 EnblSwtchTrnsfrCsOutputShaftPTO 4;
BA_ "SPN" SG_ 2566759463 EnblSwtchTrnsfrCsOutputShaftPTO 3455;
BA_ "SigType" SG_ 2566759463 EnggmntSttsPTOEngAccssoryDrive2 4;
BA_ "SPN" SG_ 2566759463 EnggmntSttsPTOEngAccssoryDrive2 3947;
BA_ "SigType" SG_ 2566759463 EnggmntSttsPTOEngAccssoryDrive1 4;
BA_ "SPN" SG_ 2566759463 EnggmntSttsPTOEngAccssoryDrive1 3944;
BA_ "SigType" SG_ 2566759463 EnggmntCnsntPTOEngAccssryDrive2 4;
BA_ "SPN" SG_ 2566759463 EnggmntCnsntPTOEngAccssryDrive2 3946;
BA_ "SigType" SG_ 2566759463 EnggmntCnsntPTOEngAccssryDrive1 4;
BA_ "SPN" SG_ 2566759463 EnggmntCnsntPTOEngAccssryDrive1 3943;
BA_ "SigType" SG_ 2566759463 EngagementStatusPTOEngFlywheel 4;
BA_ "SPN" SG_ 2566759463 EngagementStatusPTOEngFlywheel 3941;
BA_ "SigType" SG_ 2566759463 EngagementConsentPTOEngFlywheel 4;
BA_ "SPN" SG_ 2566759463 EngagementConsentPTOEngFlywheel 3940;
BA_ "SigType" SG_ 2566759463 EnblSwitchPTOEngAccessoryDrive2 4;
BA_ "SPN" SG_ 2566759463 EnblSwitchPTOEngAccessoryDrive2 3945;
BA_ "SigType" SG_ 2566759463 EnblSwitchPTOEngAccessoryDrive1 4;
BA_ "SPN" SG_ 2566759463 EnblSwitchPTOEngAccessoryDrive1 3942;
BA_ "SigType" SG_ 2566759463 EnableSwitchPTOEngFlywheel 4;
BA_ "SPN" SG_ 2566759463 EnableSwitchPTOEngFlywheel 3939;
BA_ "SigType" SG_ 2566759463 AtLeastOnePTOEngaged 4;
BA_ "SPN" SG_ 2566759463 AtLeastOnePTOEngaged 3948;
BA_ "SigType" SG_ 2566759427 EnggmntSttusTransInputShaftPTO1 4;
BA_ "SPN" SG_ 2566759427 EnggmntSttusTransInputShaftPTO1 3460;
BA_ "SigType" SG_ 2566759427 EnggmntSttusTransInputShaftPTO2 4;
BA_ "SPN" SG_ 2566759427 EnggmntSttusTransInputShaftPTO2 3461;
BA_ "SigType" SG_ 2566759427 EnggmntSttusTransOutputShaftPTO 4;
BA_ "SPN" SG_ 2566759427 EnggmntSttusTransOutputShaftPTO 3462;
BA_ "SigType" SG_ 2566759427 EnggmntSttsTrnsfrCsOtptShaftPTO 4;
BA_ "SPN" SG_ 2566759427 EnggmntSttsTrnsfrCsOtptShaftPTO 3463;
BA_ "SigType" SG_ 2566759427 EnggmntCnsntTransInputShaftPTO1 4;
BA_ "SPN" SG_ 2566759427 EnggmntCnsntTransInputShaftPTO1 3456;
BA_ "SigType" SG_ 2566759427 EnggmntCnsntTransInputShaftPTO2 4;
BA_ "SPN" SG_ 2566759427 EnggmntCnsntTransInputShaftPTO2 3457;
BA_ "SigType" SG_ 2566759427 EnggmntCnsntTransOutputShaftPTO 4;
BA_ "SPN" SG_ 2566759427 EnggmntCnsntTransOutputShaftPTO 3458;
BA_ "SigType" SG_ 2566759427 EnggmntCnsntTrnsfrCsOtptShftPTO 4;
BA_ "SPN" SG_ 2566759427 EnggmntCnsntTrnsfrCsOtptShftPTO 3459;
BA_ "SigType" SG_ 2566759427 EnableSwitchTransInputShaftPTO1 4;
BA_ "SPN" SG_ 2566759427 EnableSwitchTransInputShaftPTO1 3452;
BA_ "SigType" SG_ 2566759427 EnableSwitchTransInputShaftPTO2 4;
BA_ "SPN" SG_ 2566759427 EnableSwitchTransInputShaftPTO2 3453;
BA_ "SigType" SG_ 2566759427 EnableSwitchTransOutputShaftPTO 4;
BA_ "SPN" SG_ 2566759427 EnableSwitchTransOutputShaftPTO 3454;
BA_ "SigType" SG_ 2566759427 EnblSwtchTrnsfrCsOutputShaftPTO 4;
BA_ "SPN" SG_ 2566759427 EnblSwtchTrnsfrCsOutputShaftPTO 3455;
BA_ "SigType" SG_ 2566759427 EnggmntSttsPTOEngAccssoryDrive2 4;
BA_ "SPN" SG_ 2566759427 EnggmntSttsPTOEngAccssoryDrive2 3947;
BA_ "SigType" SG_ 2566759427 EnggmntSttsPTOEngAccssoryDrive1 4;
BA_ "SPN" SG_ 2566759427 EnggmntSttsPTOEngAccssoryDrive1 3944;
BA_ "SigType" SG_ 2566759427 EnggmntCnsntPTOEngAccssryDrive2 4;
BA_ "SPN" SG_ 2566759427 EnggmntCnsntPTOEngAccssryDrive2 3946;
BA_ "SigType" SG_ 2566759427 EnggmntCnsntPTOEngAccssryDrive1 4;
BA_ "SPN" SG_ 2566759427 EnggmntCnsntPTOEngAccssryDrive1 3943;
BA_ "SigType" SG_ 2566759427 EngagementStatusPTOEngFlywheel 4;
BA_ "SPN" SG_ 2566759427 EngagementStatusPTOEngFlywheel 3941;
BA_ "SigType" SG_ 2566759427 EngagementConsentPTOEngFlywheel 4;
BA_ "SPN" SG_ 2566759427 EngagementConsentPTOEngFlywheel 3940;
BA_ "SigType" SG_ 2566759427 EnblSwitchPTOEngAccessoryDrive2 4;
BA_ "SPN" SG_ 2566759427 EnblSwitchPTOEngAccessoryDrive2 3945;
BA_ "SigType" SG_ 2566759427 EnblSwitchPTOEngAccessoryDrive1 4;
BA_ "SPN" SG_ 2566759427 EnblSwitchPTOEngAccessoryDrive1 3942;
BA_ "SigType" SG_ 2566759427 EnableSwitchPTOEngFlywheel 4;
BA_ "SPN" SG_ 2566759427 EnableSwitchPTOEngFlywheel 3939;
BA_ "SigType" SG_ 2566759427 AtLeastOnePTOEngaged 4;
BA_ "SPN" SG_ 2566759427 AtLeastOnePTOEngaged 3948;
BA_ "SigType" SG_ 2633927939 ECUPowerOutputSupplyVoltage3 1;
BA_ "SPN" SG_ 2633927939 ECUPowerOutputSupplyVoltage3 3599;
BA_ "SigType" SG_ 2633927939 ECUPowerOutputSupplyVoltage2 1;
BA_ "SPN" SG_ 2633927939 ECUPowerOutputSupplyVoltage2 3598;
BA_ "SigType" SG_ 2633927939 ECUPowerOutputSupplyVoltage1 1;
BA_ "SPN" SG_ 2633927939 ECUPowerOutputSupplyVoltage1 3597;
BA_ "SigType" SG_ 2633927939 BatteryPotential_PowerInput2 1;
BA_ "SPN" SG_ 2633927939 BatteryPotential_PowerInput2 444;
BA_ "SigType" SG_ 2566846211 ChargingSystemPotential 1;
BA_ "SPN" SG_ 2566846211 ChargingSystemPotential 167;
BA_ "SigType" SG_ 2566846211 AltCurrent 1;
BA_ "SPN" SG_ 2566846211 AltCurrent 115;
BA_ "SigType" SG_ 2566846211 NetBatteryCurrent 1;
BA_ "SPN" SG_ 2566846211 NetBatteryCurrent 114;
BA_ "SigType" SG_ 2566846211 KeyswitchBatteryPotential 1;
BA_ "SPN" SG_ 2566846211 KeyswitchBatteryPotential 158;
BA_ "SigType" SG_ 2566846211 BatteryPotential_PowerInput1 1;
BA_ "SPN" SG_ 2566846211 BatteryPotential_PowerInput1 168;
BA_ "SigType" SG_ 2566841088 SupportTSC1CtrlPurposeGroup4 1;
BA_ "SPN" SG_ 2566841088 SupportTSC1CtrlPurposeGroup4 3348;
BA_ "SigType" SG_ 2566841088 SupportTSC1CtrlPurposeGroup3 1;
BA_ "SPN" SG_ 2566841088 SupportTSC1CtrlPurposeGroup3 3347;
BA_ "SigType" SG_ 2566841088 SupportTSC1CtrlPurposeGroup2 1;
BA_ "SPN" SG_ 2566841088 SupportTSC1CtrlPurposeGroup2 3346;
BA_ "SigType" SG_ 2566841088 SupportTSC1CtrlPurposeGroup1 1;
BA_ "SPN" SG_ 2566841088 SupportTSC1CtrlPurposeGroup1 3345;
BA_ "SigType" SG_ 2566841088 SupportVariableRateTSC1Message 1;
BA_ "SPN" SG_ 2566841088 SupportVariableRateTSC1Message 3344;
BA_ "SigType" SG_ 2566841088 EngDefaultTorqueLimit 1;
BA_ "SPN" SG_ 2566841088 EngDefaultTorqueLimit 1846;
BA_ "SigType" SG_ 2566841088 EngMomentOfInertia 1;
BA_ "SPN" SG_ 2566841088 EngMomentOfInertia 1794;
BA_ "SigType" SG_ 2566841088 EngExRngRqdSpdCtrlRngUpperLimit 1;
BA_ "SPN" SG_ 2566841088 EngExRngRqdSpdCtrlRngUpperLimit 1712;
BA_ "SigType" SG_ 2566841088 EngRqdTorqueCtrlRangeUpperLimit 1;
BA_ "SPN" SG_ 2566841088 EngRqdTorqueCtrlRangeUpperLimit 538;
BA_ "SigType" SG_ 2566841088 EngRqdTorqueCtrlRangeLowerLimit 1;
BA_ "SPN" SG_ 2566841088 EngRqdTorqueCtrlRangeLowerLimit 537;
BA_ "SigType" SG_ 2566841088 EngRqedSpeedCtrlRangeUpperLimit 1;
BA_ "SPN" SG_ 2566841088 EngRqedSpeedCtrlRangeUpperLimit 536;
BA_ "SigType" SG_ 2566841088 EngRqedSpeedCtrlRangeLowerLimit 1;
BA_ "SPN" SG_ 2566841088 EngRqedSpeedCtrlRangeLowerLimit 535;
BA_ "SigType" SG_ 2566841088 EngMxMomentaryOverrideTimeLimit 1;
BA_ "SPN" SG_ 2566841088 EngMxMomentaryOverrideTimeLimit 534;
BA_ "SigType" SG_ 2566841088 EngMxMmntaryOverrideSpeedPoint7 1;
BA_ "SPN" SG_ 2566841088 EngMxMmntaryOverrideSpeedPoint7 533;
BA_ "SigType" SG_ 2566841088 EngReferenceTorque 1;
BA_ "SPN" SG_ 2566841088 EngReferenceTorque 544;
BA_ "SigType" SG_ 2566841088 EngSpeedAtHighIdlePoint6 1;
BA_ "SPN" SG_ 2566841088 EngSpeedAtHighIdlePoint6 532;
BA_ "SigType" SG_ 2566841088 EngGainOfEndspeedGovernor 1;
BA_ "SPN" SG_ 2566841088 EngGainOfEndspeedGovernor 545;
BA_ "SigType" SG_ 2566841088 EngPercentTorqueAtPoint5 1;
BA_ "SPN" SG_ 2566841088 EngPercentTorqueAtPoint5 543;
BA_ "SigType" SG_ 2566841088 EngSpeedAtPoint5 1;
BA_ "SPN" SG_ 2566841088 EngSpeedAtPoint5 531;
BA_ "SigType" SG_ 2566841088 EngPercentTorqueAtPoint4 1;
BA_ "SPN" SG_ 2566841088 EngPercentTorqueAtPoint4 542;
BA_ "SigType" SG_ 2566841088 EngSpeedAtPoint4 1;
BA_ "SPN" SG_ 2566841088 EngSpeedAtPoint4 530;
BA_ "SigType" SG_ 2566841088 EngPercentTorqueAtPoint3 1;
BA_ "SPN" SG_ 2566841088 EngPercentTorqueAtPoint3 541;
BA_ "SigType" SG_ 2566841088 EngSpeedAtPoint3 1;
BA_ "SPN" SG_ 2566841088 EngSpeedAtPoint3 529;
BA_ "SigType" SG_ 2566841088 EngPercentTorqueAtPoint2 1;
BA_ "SPN" SG_ 2566841088 EngPercentTorqueAtPoint2 540;
BA_ "SigType" SG_ 2566841088 EngSpeedAtPoint2 1;
BA_ "SPN" SG_ 2566841088 EngSpeedAtPoint2 528;
BA_ "SigType" SG_ 2566841088 EngPercentTorqueAtIdlePoint1 1;
BA_ "SPN" SG_ 2566841088 EngPercentTorqueAtIdlePoint1 539;
BA_ "SigType" SG_ 2566841088 EngSpeedAtIdlePoint1 1;
BA_ "SPN" SG_ 2566841088 EngSpeedAtIdlePoint1 188;
BA_ "SigType" SG_ 2566834947 DM2_SPNConversionMethod_DTC1 1;
BA_ "SigType" SG_ 2566834947 DM2_SPNConversionMethod_DTC2 1;
BA_ "SigType" SG_ 2566834947 DM2_SPNConversionMethod_DTC3 1;
BA_ "SigType" SG_ 2566834947 DM2_SPNConversionMethod_DTC4 1;
BA_ "SigType" SG_ 2566834947 DM2_SPNConversionMethod_DTC5 1;
BA_ "SigType" SG_ 2566834947 DM2_SPNConversionMethod_DTC6 1;
BA_ "SigType" SG_ 2566834947 DM2_SPNConversionMethod_DTC7 1;
BA_ "SigType" SG_ 2566834947 DM2_SPNConversionMethod_DTC8 1;
BA_ "SigType" SG_ 2566834947 DM2_OccurenceCount_DTC8 1;
BA_ "SigType" SG_ 2566834947 DM2_OccurenceCount_DTC7 1;
BA_ "SigType" SG_ 2566834947 DM2_OccurenceCount_DTC6 1;
BA_ "SigType" SG_ 2566834947 DM2_OccurenceCount_DTC5 1;
BA_ "SigType" SG_ 2566834947 DM2_OccurenceCount_DTC4 1;
BA_ "SigType" SG_ 2566834947 DM2_OccurenceCount_DTC3 1;
BA_ "SigType" SG_ 2566834947 DM2_OccurenceCount_DTC2 1;
BA_ "SigType" SG_ 2566834947 DM2_OccurenceCount_DTC1 1;
BA_ "SigType" SG_ 2566834947 DM2_FMI_DTC8 1;
BA_ "SigType" SG_ 2566834947 DM2_FMI_DTC7 1;
BA_ "SigType" SG_ 2566834947 DM2_FMI_DTC6 1;
BA_ "SigType" SG_ 2566834947 DM2_FMI_DTC5 1;
BA_ "SigType" SG_ 2566834947 DM2_FMI_DTC4 1;
BA_ "SigType" SG_ 2566834947 DM2_FMI_DTC3 1;
BA_ "SigType" SG_ 2566834947 DM2_FMI_DTC2 1;
BA_ "SigType" SG_ 2566834947 DM2_FMI_DTC1 1;
BA_ "SigType" SG_ 2566834947 DM2_SPN1_DTC8 1;
BA_ "SigType" SG_ 2566834947 DM2_SPN3_DTC8 1;
BA_ "SigType" SG_ 2566834947 DM2_SPN3_DTC7 1;
BA_ "SigType" SG_ 2566834947 DM2_SPN3_DTC6 1;
BA_ "SigType" SG_ 2566834947 DM2_SPN3_DTC5 1;
BA_ "SigType" SG_ 2566834947 DM2_SPN3_DTC4 1;
BA_ "SigType" SG_ 2566834947 DM2_SPN3_DTC3 1;
BA_ "SigType" SG_ 2566834947 DM2_SPN3_DTC2 1;
BA_ "SigType" SG_ 2566834947 DM2_SPN3_DTC1 1;
BA_ "SigType" SG_ 2566834947 DM2_SPN2_DTC8 1;
BA_ "SigType" SG_ 2566834947 DM2_SPN2_DTC7 1;
BA_ "SigType" SG_ 2566834947 DM2_SPN2_DTC6 1;
BA_ "SigType" SG_ 2566834947 DM2_SPN2_DTC5 1;
BA_ "SigType" SG_ 2566834947 DM2_SPN2_DTC4 1;
BA_ "SigType" SG_ 2566834947 DM2_SPN2_DTC3 1;
BA_ "SigType" SG_ 2566834947 DM2_SPN2_DTC2 1;
BA_ "SigType" SG_ 2566834947 DM2_SPN2_DTC1 1;
BA_ "SigType" SG_ 2566834947 DM2_SPN1_DTC5 1;
BA_ "SigType" SG_ 2566834947 DM2_SPN1_DTC6 1;
BA_ "SigType" SG_ 2566834947 DM2_SPN1_DTC7 1;
BA_ "SigType" SG_ 2566834947 DM2_SPN1_DTC2 1;
BA_ "SigType" SG_ 2566834947 DM2_SPN1_DTC4 1;
BA_ "SigType" SG_ 2566834947 DM2_SPN1_DTC3 1;
BA_ "SigType" SG_ 2566834947 DM2_SPN1_DTC1 1;
BA_ "SigType" SG_ 2566834947 DM2FlashRedStopLamp 4;
BA_ "SigType" SG_ 2566834947 DM2FlashProtectLamp 4;
BA_ "SigType" SG_ 2566834947 DM2FlashMalfuncIndicatorLamp 4;
BA_ "SigType" SG_ 2566834947 DM2FlashAmberWarningLamp 4;
BA_ "SigType" SG_ 2566834947 DM2MalfunctionIndicatorLampState 4;
BA_ "SigType" SG_ 2566834947 DM2AmberWarningLampStatus 4;
BA_ "SigType" SG_ 2566834947 DM2RedStopLampState 4;
BA_ "SigType" SG_ 2566834947 DM2ProtectLampStatus 4;
BA_ "SigType" SG_ 2566834691 SPNConversionMethod_DTC1 1;
BA_ "SigType" SG_ 2566834691 SPNConversionMethod_DTC2 1;
BA_ "SigType" SG_ 2566834691 SPNConversionMethod_DTC3 1;
BA_ "SigType" SG_ 2566834691 SPNConversionMethod_DTC4 1;
BA_ "SigType" SG_ 2566834691 SPNConversionMethod_DTC5 1;
BA_ "SigType" SG_ 2566834691 SPNConversionMethod_DTC6 1;
BA_ "SigType" SG_ 2566834691 SPNConversionMethod_DTC7 1;
BA_ "SigType" SG_ 2566834691 SPNConversionMethod_DTC8 1;
BA_ "SigType" SG_ 2566834691 OccurenceCount_DTC8 1;
BA_ "SigType" SG_ 2566834691 OccurenceCount_DTC7 1;
BA_ "SigType" SG_ 2566834691 OccurenceCount_DTC6 1;
BA_ "SigType" SG_ 2566834691 OccurenceCount_DTC5 1;
BA_ "SigType" SG_ 2566834691 OccurenceCount_DTC4 1;
BA_ "SigType" SG_ 2566834691 OccurenceCount_DTC3 1;
BA_ "SigType" SG_ 2566834691 OccurenceCount_DTC2 1;
BA_ "SigType" SG_ 2566834691 OccurenceCount_DTC1 1;
BA_ "SigType" SG_ 2566834691 FMI_DTC8 1;
BA_ "SigType" SG_ 2566834691 FMI_DTC7 1;
BA_ "SigType" SG_ 2566834691 FMI_DTC6 1;
BA_ "SigType" SG_ 2566834691 FMI_DTC5 1;
BA_ "SigType" SG_ 2566834691 FMI_DTC4 1;
BA_ "SigType" SG_ 2566834691 FMI_DTC3 1;
BA_ "SigType" SG_ 2566834691 FMI_DTC2 1;
BA_ "SigType" SG_ 2566834691 FMI_DTC1 1;
BA_ "SigType" SG_ 2566834691 SPN1_DTC8 1;
BA_ "SigType" SG_ 2566834691 SPN3_DTC8 1;
BA_ "SigType" SG_ 2566834691 SPN3_DTC7 1;
BA_ "SigType" SG_ 2566834691 SPN3_DTC6 1;
BA_ "SigType" SG_ 2566834691 SPN3_DTC5 1;
BA_ "SigType" SG_ 2566834691 SPN3_DTC4 1;
BA_ "SigType" SG_ 2566834691 SPN3_DTC3 1;
BA_ "SigType" SG_ 2566834691 SPN3_DTC2 1;
BA_ "SigType" SG_ 2566834691 SPN3_DTC1 1;
BA_ "SigType" SG_ 2566834691 SPN2_DTC8 1;
BA_ "SigType" SG_ 2566834691 SPN2_DTC7 1;
BA_ "SigType" SG_ 2566834691 SPN2_DTC6 1;
BA_ "SigType" SG_ 2566834691 SPN2_DTC5 1;
BA_ "SigType" SG_ 2566834691 SPN2_DTC4 1;
BA_ "SigType" SG_ 2566834691 SPN2_DTC3 1;
BA_ "SigType" SG_ 2566834691 SPN2_DTC2 1;
BA_ "SigType" SG_ 2566834691 SPN2_DTC1 1;
BA_ "SigType" SG_ 2566834691 SPN1_DTC5 1;
BA_ "SigType" SG_ 2566834691 SPN1_DTC6 1;
BA_ "SigType" SG_ 2566834691 SPN1_DTC7 1;
BA_ "SigType" SG_ 2566834691 SPN1_DTC2 1;
BA_ "SigType" SG_ 2566834691 SPN1_DTC4 1;
BA_ "SigType" SG_ 2566834691 SPN1_DTC3 1;
BA_ "SigType" SG_ 2566834691 SPN1_DTC1 1;
BA_ "SigType" SG_ 2566834691 FlashRedStopLamp 4;
BA_ "SigType" SG_ 2566834691 FlashProtectLamp 4;
BA_ "SigType" SG_ 2566834691 FlashMalfuncIndicatorLamp 4;
BA_ "SigType" SG_ 2566834691 FlashAmberWarningLamp 4;
BA_ "SigType" SG_ 2566834691 MalfunctionIndicatorLampState 4;
BA_ "SigType" SG_ 2566834691 AmberWarningLampStatus 4;
BA_ "SigType" SG_ 2566834691 RedStopLampState 4;
BA_ "SigType" SG_ 2566834691 ProtectLampStatus 4;
BA_ "SigType" SG_ 2566834688 DTC5 7;
BA_ "SigType" SG_ 2566834688 DTC1 7;
BA_ "SigType" SG_ 2566834688 FlashRedStopLamp 4;
BA_ "SPN" SG_ 2566834688 FlashRedStopLamp 3039;
BA_ "SigType" SG_ 2566834688 FlashProtectLamp 4;
BA_ "SPN" SG_ 2566834688 FlashProtectLamp 3041;
BA_ "SigType" SG_ 2566834688 FlashMalfuncIndicatorLamp 4;
BA_ "SPN" SG_ 2566834688 FlashMalfuncIndicatorLamp 3038;
BA_ "SigType" SG_ 2566834688 FlashAmberWarningLamp 4;
BA_ "SPN" SG_ 2566834688 FlashAmberWarningLamp 3040;
BA_ "SigType" SG_ 2566834688 MalfunctionIndicatorLampStatus 4;
BA_ "SPN" SG_ 2566834688 MalfunctionIndicatorLampStatus 1213;
BA_ "SigType" SG_ 2566834688 AmberWarningLampStatus 4;
BA_ "SPN" SG_ 2566834688 AmberWarningLampStatus 624;
BA_ "SigType" SG_ 2566834688 RedStopLampState 4;
BA_ "SPN" SG_ 2566834688 RedStopLampState 623;
BA_ "SigType" SG_ 2566834688 ProtectLampStatus 4;
BA_ "SPN" SG_ 2566834688 ProtectLampStatus 987;
BA_ "SigType" SG_ 2566834688 DTC4 7;
BA_ "SigType" SG_ 2566834688 DTC3 7;
BA_ "SigType" SG_ 2566834688 DTC2 7;
BA_ "GenSigStartValue" SG_ 2164211715 Grade 1000;
BA_ "SigType" SG_ 2164211715 GrossCombinationWeight 1;
BA_ "SPN" SG_ 2164211715 GrossCombinationWeight 417;
BA_ "SigType" SG_ 2566844721 ParkBrakeReleaseInhibitRq 4;
BA_ "SPN" SG_ 2566844721 ParkBrakeReleaseInhibitRq 3807;
BA_ "SigType" SG_ 2566844721 PTOGovernorState 4;
BA_ "SPN" SG_ 2566844721 PTOGovernorState 976;
BA_ "SigType" SG_ 2566844721 EngShutdownOverrideSwitch 4;
BA_ "SPN" SG_ 2566844721 EngShutdownOverrideSwitch 1237;
BA_ "SigType" SG_ 2566844721 EngTestModeSwitch 4;
BA_ "SPN" SG_ 2566844721 EngTestModeSwitch 966;
BA_ "SigType" SG_ 2566844721 EngIdleDecrementSwitch 4;
BA_ "SPN" SG_ 2566844721 EngIdleDecrementSwitch 967;
BA_ "SigType" SG_ 2566844721 EngIdleIncrementSwitch 4;
BA_ "SPN" SG_ 2566844721 EngIdleIncrementSwitch 968;
BA_ "SPN" SG_ 2566844721 CruiseCtrlStates 527;
BA_ "SigType" SG_ 2566844721 CruiseCtrlSetSpeed 1;
BA_ "SPN" SG_ 2566844721 CruiseCtrlSetSpeed 86;
BA_ "SigType" SG_ 2566844721 CruiseCtrlAccelerateSwitch 4;
BA_ "SPN" SG_ 2566844721 CruiseCtrlAccelerateSwitch 602;
BA_ "SigType" SG_ 2566844721 CruiseCtrlResumeSwitch 4;
BA_ "SPN" SG_ 2566844721 CruiseCtrlResumeSwitch 601;
BA_ "SigType" SG_ 2566844721 CruiseCtrlCoastSwitch 4;
BA_ "SPN" SG_ 2566844721 CruiseCtrlCoastSwitch 600;
BA_ "SigType" SG_ 2566844721 CruiseCtrlSetSwitch 4;
BA_ "SPN" SG_ 2566844721 CruiseCtrlSetSwitch 599;
BA_ "SigType" SG_ 2566844721 ClutchSwitch 4;
BA_ "SPN" SG_ 2566844721 ClutchSwitch 598;
BA_ "SigType" SG_ 2566844721 BrakeSwitch_SA31 4;
BA_ "SPN" SG_ 2566844721 BrakeSwitch_SA31 597;
BA_ "SigType" SG_ 2566844721 CruiseCtrlEnableSwitch 4;
BA_ "SPN" SG_ 2566844721 CruiseCtrlEnableSwitch 596;
BA_ "SigType" SG_ 2566844721 CruiseCtrlActive 4;
BA_ "SPN" SG_ 2566844721 CruiseCtrlActive 595;
BA_ "SigType" SG_ 2566844721 WheelBasedVehicleSpeed 1;
BA_ "SPN" SG_ 2566844721 WheelBasedVehicleSpeed 84;
BA_ "SigType" SG_ 2566844721 CruiseCtrlPauseSwitch 4;
BA_ "SPN" SG_ 2566844721 CruiseCtrlPauseSwitch 1633;
BA_ "SigType" SG_ 2566844721 ParkingBrakeSwitch 4;
BA_ "SPN" SG_ 2566844721 ParkingBrakeSwitch 70;
BA_ "SigType" SG_ 2566844721 TwoSpeedAxleSwitch 4;
BA_ "SPN" SG_ 2566844721 TwoSpeedAxleSwitch 69;
BA_ "SigType" SG_ 2566844711 ParkBrakeReleaseInhibitRq 4;
BA_ "SPN" SG_ 2566844711 ParkBrakeReleaseInhibitRq 3807;
BA_ "SigType" SG_ 2566844711 PTOGovernorState 4;
BA_ "SPN" SG_ 2566844711 PTOGovernorState 976;
BA_ "SigType" SG_ 2566844711 EngShutdownOverrideSwitch 4;
BA_ "SPN" SG_ 2566844711 EngShutdownOverrideSwitch 1237;
BA_ "SigType" SG_ 2566844711 EngTestModeSwitch 4;
BA_ "SPN" SG_ 2566844711 EngTestModeSwitch 966;
BA_ "SigType" SG_ 2566844711 EngIdleDecrementSwitch 4;
BA_ "SPN" SG_ 2566844711 EngIdleDecrementSwitch 967;
BA_ "SigType" SG_ 2566844711 EngIdleIncrementSwitch 4;
BA_ "SPN" SG_ 2566844711 EngIdleIncrementSwitch 968;
BA_ "SPN" SG_ 2566844711 CruiseCtrlStates 527;
BA_ "SigType" SG_ 2566844711 CruiseCtrlSetSpeed 1;
BA_ "SPN" SG_ 2566844711 CruiseCtrlSetSpeed 86;
BA_ "SigType" SG_ 2566844711 CruiseCtrlAccelerateSwitch 4;
BA_ "SPN" SG_ 2566844711 CruiseCtrlAccelerateSwitch 602;
BA_ "SigType" SG_ 2566844711 CruiseCtrlResumeSwitch 4;
BA_ "SPN" SG_ 2566844711 CruiseCtrlResumeSwitch 601;
BA_ "SigType" SG_ 2566844711 CruiseCtrlCoastSwitch 4;
BA_ "SPN" SG_ 2566844711 CruiseCtrlCoastSwitch 600;
BA_ "SigType" SG_ 2566844711 CruiseCtrlSetSwitch 4;
BA_ "SPN" SG_ 2566844711 CruiseCtrlSetSwitch 599;
BA_ "SigType" SG_ 2566844711 ClutchSwitch 4;
BA_ "SPN" SG_ 2566844711 ClutchSwitch 598;
BA_ "SigType" SG_ 2566844711 BrakeSwitch_SA27 4;
BA_ "SPN" SG_ 2566844711 BrakeSwitch_SA27 597;
BA_ "SigType" SG_ 2566844711 CruiseCtrlEnableSwitch 4;
BA_ "SPN" SG_ 2566844711 CruiseCtrlEnableSwitch 596;
BA_ "SigType" SG_ 2566844711 CruiseCtrlActive 4;
BA_ "SPN" SG_ 2566844711 CruiseCtrlActive 595;
BA_ "SigType" SG_ 2566844711 WheelBasedVehicleSpeed 1;
BA_ "SPN" SG_ 2566844711 WheelBasedVehicleSpeed 84;
BA_ "SigType" SG_ 2566844711 CruiseCtrlPauseSwitch 4;
BA_ "SPN" SG_ 2566844711 CruiseCtrlPauseSwitch 1633;
BA_ "SigType" SG_ 2566844711 ParkingBrakeSwitch 4;
BA_ "SPN" SG_ 2566844711 ParkingBrakeSwitch 70;
BA_ "SigType" SG_ 2566844711 TwoSpeedAxleSwitch 4;
BA_ "SPN" SG_ 2566844711 TwoSpeedAxleSwitch 69;
VAL_ 3221225472 TransCoastModeStatus 3 "Not Available" 2 "Error" 1 "Enabled" 0 "Disabled" ;
VAL_ 3221225472 TirePressThresholdDetection 7 "NotAvailable" 6 "ErrorIndicator" 5 "NotDefined" 4 "ExtrmUndrPrssTrPrssrIsAtALvlWhr" 3 "UndrPrssTrPrssrIsLwrThnThPrssrD" 2 "NWrnngPrssTrPrssrIsWthnThThrshl" 1 "OvrPrssTrPrssrIsHghrThnThPrssrD" 0 "ExtrmOvrPrssTrPrssrIsAtALvlWhrT" ;
VAL_ 3221225472 CTIWheelEndElectricalFault 3 "NotSupported" 2 "Error" 1 "NotDefined" 0 "Ok" ;
VAL_ 3221225472 CTITireStatus 3 "NotSupported" 2 "Error" 1 "TireLeakDetected" 0 "Ok" ;
VAL_ 3221225472 CTIWheelSensorStatus 3 "NotSupported" 2 "NotDefined" 1 "On" 0 "Off_IsolatedFromCTIPressCtrl" ;
VAL_ 2565935153 BrakeSwitch2 3 "NotAvailable" 2 "Error" 1 "BrakePedalDepressed" 0 "BrakePedalReleased" ;
VAL_ 2565935127 BrakeSwitch2 3 "NotAvailable" 2 "Error" 1 "BrakePedalDepressed" 0 "BrakePedalReleased" ;
VAL_ 2565935121 BrakeSwitch2 3 "NotAvailable" 2 "Error" 1 "BrakePedalDepressed" 0 "BrakePedalReleased" ;
VAL_ 2565935115 BrakeSwitch2 3 "NotAvailable" 2 "Error" 1 "BrakePedalDepressed" 0 "BrakePedalReleased" ;
VAL_ 2565935104 BrakeSwitch2 3 "NotAvailable" 2 "Error" 1 "BrakePedalDepressed" 0 "BrakePedalReleased" ;
VAL_ 2566705667 DM54FlashMalfuncIndicatorLamp 3 "Unavailable / Do Not Flash" 2 "Reserved" 1 "Fast Flash" 0 "Slow Flash" ;
VAL_ 2566705667 DM54FlashRedStopLamp 3 "Unavailable / Do Not Flash" 2 "Reserved" 1 "Fast Flash" 0 "Slow Flash" ;
VAL_ 2566705667 DM54FlashAmberWarningLamp 3 "Unavailable / Do Not Flash" 2 "Reserved" 1 "Fast Flash" 0 "Slow Flash" ;
VAL_ 2566705667 DM54FlashProtectLamp 3 "Unavailable / Do Not Flash" 2 "Reserved" 1 "Fast Flash" 0 "Slow Flash" ;
VAL_ 2566705667 DM54MalfunctionIndicateLampState 3 "Not available" 2 "Reserved" 1 "Lamp on" 0 "Lamp off" ;
VAL_ 2566705667 DM54RedStopLampState 3 "Not available" 2 "Reserved" 1 "Lamp on" 0 "Lamp off" ;
VAL_ 2566705667 DM54AmberWarningLampStatus 3 "Not available" 2 "Reserved" 1 "Lamp on" 0 "Lamp off" ;
VAL_ 2566705667 DM54ProtectLampStatus 3 "Not available" 2 "Reserved" 1 "Lamp on" 0 "Lamp off" ;
VAL_ 2566705411 DM53FlashMalfuncIndicatorLamp 3 "Unavailable / Do Not Flash" 2 "Reserved" 1 "Fast Flash" 0 "Slow Flash" ;
VAL_ 2566705411 DM53FlashRedStopLamp 3 "Unavailable / Do Not Flash" 2 "Reserved" 1 "Fast Flash" 0 "Slow Flash" ;
VAL_ 2566705411 DM53FlashAmberWarningLamp 3 "Unavailable / Do Not Flash" 2 "Reserved" 1 "Fast Flash" 0 "Slow Flash" ;
VAL_ 2566705411 DM53FlashProtectLamp 3 "Unavailable / Do Not Flash" 2 "Reserved" 1 "Fast Flash" 0 "Slow Flash" ;
VAL_ 2566705411 DM53MalfunctionIndicateLampState 3 "Not available" 2 "Reserved" 1 "Lamp on" 0 "Lamp off" ;
VAL_ 2566705411 DM53RedStopLampState 3 "Not available" 2 "Reserved" 1 "Lamp on" 0 "Lamp off" ;
VAL_ 2566705411 DM53AmberWarningLampStatus 3 "Not available" 2 "Reserved" 1 "Lamp on" 0 "Lamp off" ;
VAL_ 2566705411 DM53ProtectLampStatus 3 "Not available" 2 "Reserved" 1 "Lamp on" 0 "Lamp off" ;
VAL_ 2565935358 BrakeSwitch2 3 "NotAvailable" 2 "Error" 1 "BrakePedalDepressed" 0 "BrakePedalReleased" ;
VAL_ 2566847025 ParkingBrakeRedWarningSignal 3 "TakeNoAction" 2 "Reserved" 1 "On" 0 "Off" ;
VAL_ 2566847025 ParkBrakeReleaseInhibitStatus 3 "Unavailable" 2 "Error" 1 "ParkBrakeReleaseIsInhibited" 0 "ParkBrakeReleaseIsNotInhibited" ;
VAL_ 2566847025 ParkingBrakeActuator 3 "NotAvailable" 2 "Error" 1 "ParkingBrakeActuatorActive" 0 "ParkingBrakeActuatorInactive" ;
VAL_ 2566847009 ParkingBrakeRedWarningSignal 3 "TakeNoAction" 2 "Reserved" 1 "On" 0 "Off" ;
VAL_ 2566847009 ParkBrakeReleaseInhibitStatus 3 "Unavailable" 2 "Error" 1 "ParkBrakeReleaseIsInhibited" 0 "ParkBrakeReleaseIsNotInhibited" ;
VAL_ 2566847009 ParkingBrakeActuator 3 "NotAvailable" 2 "Error" 1 "ParkingBrakeActuatorActive" 0 "ParkingBrakeActuatorInactive" ;
VAL_ 2566846999 ParkingBrakeRedWarningSignal 3 "TakeNoAction" 2 "Reserved" 1 "On" 0 "Off" ;
VAL_ 2566846999 ParkBrakeReleaseInhibitStatus 3 "Unavailable" 2 "Error" 1 "ParkBrakeReleaseIsInhibited" 0 "ParkBrakeReleaseIsNotInhibited" ;
VAL_ 2566846999 ParkingBrakeActuator 3 "NotAvailable" 2 "Error" 1 "ParkingBrakeActuatorActive" 0 "ParkingBrakeActuatorInactive" ;
VAL_ 2566846987 ParkingBrakeRedWarningSignal 3 "TakeNoAction" 2 "Reserved" 1 "On" 0 "Off" ;
VAL_ 2566846987 ParkBrakeReleaseInhibitStatus 3 "Unavailable" 2 "Error" 1 "ParkBrakeReleaseIsInhibited" 0 "ParkBrakeReleaseIsNotInhibited" ;
VAL_ 2566846987 ParkingBrakeActuator 3 "NotAvailable" 2 "Error" 1 "ParkingBrakeActuatorActive" 0 "ParkingBrakeActuatorInactive" ;
VAL_ 2566846976 ParkingBrakeRedWarningSignal 3 "TakeNoAction" 2 "Reserved" 1 "On" 0 "Off" ;
VAL_ 2566846976 ParkBrakeReleaseInhibitStatus 3 "Unavailable" 2 "Error" 1 "ParkBrakeReleaseIsInhibited" 0 "ParkBrakeReleaseIsNotInhibited" ;
VAL_ 2566846976 ParkingBrakeActuator 3 "NotAvailable" 2 "Error" 1 "ParkingBrakeActuatorActive" 0 "ParkingBrakeActuatorInactive" ;
VAL_ 2566827569 AirCompressorStatus 3 "NotAvailable" 2 "ErrorIndicator" 1 "CompressorActive" 0 "CompressorNotActive" ;
VAL_ 2432593706 ForwardCollisionWarning 3 "notAvailable" 2 "ErrorIndicator" 1 "CollisionIsImminent" 0 "NoWarning" ;
VAL_ 2432593706 ACCDistanceAlertSignal 3 "TakeNoAction" 2 "Reserved" 1 "ACCDASActive" 0 "ACCDASNotActive" ;
VAL_ 2432593706 ACCSystemShutoffWarning 3 "TakeNoAction" 2 "Reserved" 1 "ACCSSOWActive" 0 "ACCSSOWNotActive" ;
VAL_ 2432593706 ACCTargetDetected 3 "TakeNoAction" 2 "Reserved" 1 "TargetDetected" 0 "NoTargetsDetected" ;
VAL_ 2432593706 AdptveCruiseCtrlSetDistanceMode 7 "NotAvailable_NotValid" 6 "ErrorCondition" 5 "ConventionalCruiseCtrlMode" 4 "ACCDistanceMode5" 3 "ACCDistanceMode4" 2 "ACCDistanceMode3" 1 "ACCDistanceMode2" 0 "ACCDistanceMode1" ;
VAL_ 2432593706 AdaptiveCruiseCtrlMode 7 "NotAvailable_NotValid" 6 "DsbldErrrCndtnUsdTIndctThtACCIs" 5 "FinishMode" 4 "HldMdUsdTIndctThtACCHsLstThPrvs" 3 "OvertakeMode" 2 "DstncCtrlActvUsdTIndctThtACCIsO" 1 "SpeedCtrlActive" 0 "OffUsdTIndctACCIsEnbldInClbCnfg" ;
VAL_ 2432593675 ForwardCollisionWarning 3 "notAvailable" 2 "ErrorIndicator" 1 "CollisionIsImminent" 0 "NoWarning" ;
VAL_ 2432593675 ACCDistanceAlertSignal 3 "TakeNoAction" 2 "Reserved" 1 "ACCDASActive" 0 "ACCDASNotActive" ;
VAL_ 2432593675 ACCSystemShutoffWarning 3 "TakeNoAction" 2 "Reserved" 1 "ACCSSOWActive" 0 "ACCSSOWNotActive" ;
VAL_ 2432593675 ACCTargetDetected 3 "TakeNoAction" 2 "Reserved" 1 "TargetDetected" 0 "NoTargetsDetected" ;
VAL_ 2432593675 AdptveCruiseCtrlSetDistanceMode 7 "NotAvailable_NotValid" 6 "ErrorCondition" 5 "ConventionalCruiseCtrlMode" 4 "ACCDistanceMode5" 3 "ACCDistanceMode4" 2 "ACCDistanceMode3" 1 "ACCDistanceMode2" 0 "ACCDistanceMode1" ;
VAL_ 2432593675 AdaptiveCruiseCtrlMode 7 "NotAvailable_NotValid" 6 "DsbldErrrCndtnUsdTIndctThtACCIs" 5 "FinishMode" 4 "HldMdUsdTIndctThtACCHsLstThPrvs" 3 "OvertakeMode" 2 "DstncCtrlActvUsdTIndctThtACCIsO" 1 "SpeedCtrlActive" 0 "OffUsdTIndctACCIsEnbldInClbCnfg" ;
VAL_ 2566840617 RetarderLocation 15 "NotAvailable" 14 "Other" 6 "1101NotDefined" 5 "Trailer" 4 "Driveline" 3 "TransOutput" 2 "TransInput" 1 "EngExhaustBrake" 0 "EngCompressionReleaseBrake" ;
VAL_ 2566840617 RetarderType 15 "NotAvailable" 14 "Other" 5 "1101NotDefined" 4 "Exhaust" 3 "CompressionRelease" 2 "CooledFriction" 1 "Hyd" 0 "Electric_Magnetic" ;
VAL_ 2566840591 RetarderLocation 15 "NotAvailable" 14 "Other" 6 "1101NotDefined" 5 "Trailer" 4 "Driveline" 3 "TransOutput" 2 "TransInput" 1 "EngExhaustBrake" 0 "EngCompressionReleaseBrake" ;
VAL_ 2566840591 RetarderType 15 "NotAvailable" 14 "Other" 5 "1101NotDefined" 4 "Exhaust" 3 "CompressionRelease" 2 "CooledFriction" 1 "Hyd" 0 "Electric_Magnetic" ;
VAL_ 2559049726 EngShutdownCommand 3 "Not Available" 2 "Reserved for future SAE use" 1 "Shutdown engine" 0 "Don't shutdown engine" ;
VAL_ 2559049726 TransIdleGovernorFuelingInhibit 3 "Not Supported" 2 "Reserved for future SAE use" 1 "Fuel Inhibit Supported" 0 "Fuel Inhibit Not Supported" ;
VAL_ 2566759473 EnggmntSttusTransInputShaftPTO1 3 "NotAvailable" 2 "Error" 1 "DriveIsEngaged" 0 "DriveNotEngaged" ;
VAL_ 2566759473 EnggmntSttusTransInputShaftPTO2 3 "NotAvailable" 2 "Error" 1 "DriveIsEngaged" 0 "DriveNotEngaged" ;
VAL_ 2566759473 EnggmntSttusTransOutputShaftPTO 3 "NotAvailable" 2 "Error" 1 "DriveIsEngaged" 0 "DriveNotEngaged" ;
VAL_ 2566759473 EnggmntSttsTrnsfrCsOtptShaftPTO 3 "NotAvailable" 2 "Error" 1 "DriveIsEngaged" 0 "DriveNotEngaged" ;
VAL_ 2566759473 EnggmntCnsntTransInputShaftPTO1 3 "NotAvailable" 2 "Error" 1 "CnsentGivenPTODriveMayBeEngaged" 0 "CnsntNtGvnPTODrvShldNtBeEngaged" ;
VAL_ 2566759473 EnggmntCnsntTransInputShaftPTO2 3 "NotAvailable" 2 "Error" 1 "CnsentGivenPTODriveMayBeEngaged" 0 "CnsntNtGvnPTODrvShldNtBeEngaged" ;
VAL_ 2566759473 EnggmntCnsntTransOutputShaftPTO 3 "NotAvailable" 2 "Error" 1 "CnsentGivenPTODriveMayBeEngaged" 0 "CnsntNtGvnPTODrvShldNtBeEngaged" ;
VAL_ 2566759473 EnggmntCnsntTrnsfrCsOtptShftPTO 3 "NotAvailable" 2 "Error" 1 "CnsentGivenPTODriveMayBeEngaged" 0 "CnsntNtGvnPTODrvShldNtBeEngaged" ;
VAL_ 2566759473 EnableSwitchTransInputShaftPTO1 3 "NotAvailable" 2 "Error" 1 "EnblSwtchOffPTOOperationDesired" 0 "EnblSwtchOffPTOOprtonNotDesired" ;
VAL_ 2566759473 EnableSwitchTransInputShaftPTO2 3 "NotAvailable" 2 "Error" 1 "EnblSwtchOffPTOOperationDesired" 0 "EnblSwtchOffPTOOprtonNotDesired" ;
VAL_ 2566759473 EnableSwitchTransOutputShaftPTO 3 "NotAvailable" 2 "Error" 1 "EnblSwtchOffPTOOperationDesired" 0 "EnblSwtchOffPTOOprtonNotDesired" ;
VAL_ 2566759473 EnblSwtchTrnsfrCsOutputShaftPTO 3 "NotAvailable" 2 "Error" 1 "EnblSwtchOffPTOOperationDesired" 0 "EnblSwtchOffPTOOprtonNotDesired" ;
VAL_ 2566759473 EnggmntSttsPTOEngAccssoryDrive2 3 "NotAvailable" 2 "Error" 1 "DriveEngaged" 0 "DriveNotEngaged" ;
VAL_ 2566759473 EnggmntSttsPTOEngAccssoryDrive1 3 "NotAvailable" 2 "Error" 1 "DriveEngaged" 0 "DriveNotEngaged" ;
VAL_ 2566759473 EnggmntCnsntPTOEngAccssryDrive2 3 "NotAvailable" 2 "Error" 1 "CnsentGivenPTODriveMayBeEngaged" 0 "CnsntNtGvnPTODrvMayNotBeEngaged" ;
VAL_ 2566759473 EnggmntCnsntPTOEngAccssryDrive1 3 "NotAvailable" 2 "Error" 1 "CnsentGivenPTODriveMayBeEngaged" 0 "CnsntNtGvnPTODrvMayNotBeEngaged" ;
VAL_ 2566759473 EngagementStatusPTOEngFlywheel 3 "NotAvailable" 2 "Error" 1 "DriveEngaged" 0 "DriveNotEngaged" ;
VAL_ 2566759473 EngagementConsentPTOEngFlywheel 3 "NotAvailable" 2 "Error" 1 "CnsentGivenPTODriveMayBeEngaged" 0 "CnsntNtGvnPTODrvMayNotBeEngaged" ;
VAL_ 2566759473 EnblSwitchPTOEngAccessoryDrive2 3 "NotAvailable" 2 "Error" 1 "EnblSwitchOnPTOOperationDesired" 0 "EnblSwtchOffPTOOprtonNotDesired" ;
VAL_ 2566759473 EnblSwitchPTOEngAccessoryDrive1 3 "NotAvailable" 2 "Error" 1 "EnblSwitchOnPTOOperationDesired" 0 "EnblSwtchOffPTOOprtonNotDesired" ;
VAL_ 2566759473 EnableSwitchPTOEngFlywheel 3 "NotAvailable" 2 "Error" 1 "EnblSwitchOnPTOOperationDesired" 0 "EnblSwtchOffPTOOprtonNotDesired" ;
VAL_ 2566759473 AtLeastOnePTOEngaged 3 "NotAvailable" 2 "Error" 1 "AtLeastOnePTODriveIsEngaged" 0 "NoPTODriveIsEngaged" ;
VAL_ 2566759463 EnggmntSttusTransInputShaftPTO1 3 "NotAvailable" 2 "Error" 1 "DriveIsEngaged" 0 "DriveNotEngaged" ;
VAL_ 2566759463 EnggmntSttusTransInputShaftPTO2 3 "NotAvailable" 2 "Error" 1 "DriveIsEngaged" 0 "DriveNotEngaged" ;
VAL_ 2566759463 EnggmntSttusTransOutputShaftPTO 3 "NotAvailable" 2 "Error" 1 "DriveIsEngaged" 0 "DriveNotEngaged" ;
VAL_ 2566759463 EnggmntSttsTrnsfrCsOtptShaftPTO 3 "NotAvailable" 2 "Error" 1 "DriveIsEngaged" 0 "DriveNotEngaged" ;
VAL_ 2566759463 EnggmntCnsntTransInputShaftPTO1 3 "NotAvailable" 2 "Error" 1 "CnsentGivenPTODriveMayBeEngaged" 0 "CnsntNtGvnPTODrvShldNtBeEngaged" ;
VAL_ 2566759463 EnggmntCnsntTransInputShaftPTO2 3 "NotAvailable" 2 "Error" 1 "CnsentGivenPTODriveMayBeEngaged" 0 "CnsntNtGvnPTODrvShldNtBeEngaged" ;
VAL_ 2566759463 EnggmntCnsntTransOutputShaftPTO 3 "NotAvailable" 2 "Error" 1 "CnsentGivenPTODriveMayBeEngaged" 0 "CnsntNtGvnPTODrvShldNtBeEngaged" ;
VAL_ 2566759463 EnggmntCnsntTrnsfrCsOtptShftPTO 3 "NotAvailable" 2 "Error" 1 "CnsentGivenPTODriveMayBeEngaged" 0 "CnsntNtGvnPTODrvShldNtBeEngaged" ;
VAL_ 2566759463 EnableSwitchTransInputShaftPTO1 3 "NotAvailable" 2 "Error" 1 "EnblSwtchOffPTOOperationDesired" 0 "EnblSwtchOffPTOOprtonNotDesired" ;
VAL_ 2566759463 EnableSwitchTransInputShaftPTO2 3 "NotAvailable" 2 "Error" 1 "EnblSwtchOffPTOOperationDesired" 0 "EnblSwtchOffPTOOprtonNotDesired" ;
VAL_ 2566759463 EnableSwitchTransOutputShaftPTO 3 "NotAvailable" 2 "Error" 1 "EnblSwtchOffPTOOperationDesired" 0 "EnblSwtchOffPTOOprtonNotDesired" ;
VAL_ 2566759463 EnblSwtchTrnsfrCsOutputShaftPTO 3 "NotAvailable" 2 "Error" 1 "EnblSwtchOffPTOOperationDesired" 0 "EnblSwtchOffPTOOprtonNotDesired" ;
VAL_ 2566759463 EnggmntSttsPTOEngAccssoryDrive2 3 "NotAvailable" 2 "Error" 1 "DriveEngaged" 0 "DriveNotEngaged" ;
VAL_ 2566759463 EnggmntSttsPTOEngAccssoryDrive1 3 "NotAvailable" 2 "Error" 1 "DriveEngaged" 0 "DriveNotEngaged" ;
VAL_ 2566759463 EnggmntCnsntPTOEngAccssryDrive2 3 "NotAvailable" 2 "Error" 1 "CnsentGivenPTODriveMayBeEngaged" 0 "CnsntNtGvnPTODrvMayNotBeEngaged" ;
VAL_ 2566759463 EnggmntCnsntPTOEngAccssryDrive1 3 "NotAvailable" 2 "Error" 1 "CnsentGivenPTODriveMayBeEngaged" 0 "CnsntNtGvnPTODrvMayNotBeEngaged" ;
VAL_ 2566759463 EngagementStatusPTOEngFlywheel 3 "NotAvailable" 2 "Error" 1 "DriveEngaged" 0 "DriveNotEngaged" ;
VAL_ 2566759463 EngagementConsentPTOEngFlywheel 3 "NotAvailable" 2 "Error" 1 "CnsentGivenPTODriveMayBeEngaged" 0 "CnsntNtGvnPTODrvMayNotBeEngaged" ;
VAL_ 2566759463 EnblSwitchPTOEngAccessoryDrive2 3 "NotAvailable" 2 "Error" 1 "EnblSwitchOnPTOOperationDesired" 0 "EnblSwtchOffPTOOprtonNotDesired" ;
VAL_ 2566759463 EnblSwitchPTOEngAccessoryDrive1 3 "NotAvailable" 2 "Error" 1 "EnblSwitchOnPTOOperationDesired" 0 "EnblSwtchOffPTOOprtonNotDesired" ;
VAL_ 2566759463 EnableSwitchPTOEngFlywheel 3 "NotAvailable" 2 "Error" 1 "EnblSwitchOnPTOOperationDesired" 0 "EnblSwtchOffPTOOprtonNotDesired" ;
VAL_ 2566759463 AtLeastOnePTOEngaged 3 "NotAvailable" 2 "Error" 1 "AtLeastOnePTODriveIsEngaged" 0 "NoPTODriveIsEngaged" ;
VAL_ 2566759427 EnggmntSttusTransInputShaftPTO1 3 "NotAvailable" 2 "Error" 1 "DriveIsEngaged" 0 "DriveNotEngaged" ;
VAL_ 2566759427 EnggmntSttusTransInputShaftPTO2 3 "NotAvailable" 2 "Error" 1 "DriveIsEngaged" 0 "DriveNotEngaged" ;
VAL_ 2566759427 EnggmntSttusTransOutputShaftPTO 3 "NotAvailable" 2 "Error" 1 "DriveIsEngaged" 0 "DriveNotEngaged" ;
VAL_ 2566759427 EnggmntSttsTrnsfrCsOtptShaftPTO 3 "NotAvailable" 2 "Error" 1 "DriveIsEngaged" 0 "DriveNotEngaged" ;
VAL_ 2566759427 EnggmntCnsntTransInputShaftPTO1 3 "NotAvailable" 2 "Error" 1 "CnsentGivenPTODriveMayBeEngaged" 0 "CnsntNtGvnPTODrvShldNtBeEngaged" ;
VAL_ 2566759427 EnggmntCnsntTransInputShaftPTO2 3 "NotAvailable" 2 "Error" 1 "CnsentGivenPTODriveMayBeEngaged" 0 "CnsntNtGvnPTODrvShldNtBeEngaged" ;
VAL_ 2566759427 EnggmntCnsntTransOutputShaftPTO 3 "NotAvailable" 2 "Error" 1 "CnsentGivenPTODriveMayBeEngaged" 0 "CnsntNtGvnPTODrvShldNtBeEngaged" ;
VAL_ 2566759427 EnggmntCnsntTrnsfrCsOtptShftPTO 3 "NotAvailable" 2 "Error" 1 "CnsentGivenPTODriveMayBeEngaged" 0 "CnsntNtGvnPTODrvShldNtBeEngaged" ;
VAL_ 2566759427 EnableSwitchTransInputShaftPTO1 3 "NotAvailable" 2 "Error" 1 "EnblSwtchOffPTOOperationDesired" 0 "EnblSwtchOffPTOOprtonNotDesired" ;
VAL_ 2566759427 EnableSwitchTransInputShaftPTO2 3 "NotAvailable" 2 "Error" 1 "EnblSwtchOffPTOOperationDesired" 0 "EnblSwtchOffPTOOprtonNotDesired" ;
VAL_ 2566759427 EnableSwitchTransOutputShaftPTO 3 "NotAvailable" 2 "Error" 1 "EnblSwtchOffPTOOperationDesired" 0 "EnblSwtchOffPTOOprtonNotDesired" ;
VAL_ 2566759427 EnblSwtchTrnsfrCsOutputShaftPTO 3 "NotAvailable" 2 "Error" 1 "EnblSwtchOffPTOOperationDesired" 0 "EnblSwtchOffPTOOprtonNotDesired" ;
VAL_ 2566759427 EnggmntSttsPTOEngAccssoryDrive2 3 "NotAvailable" 2 "Error" 1 "DriveEngaged" 0 "DriveNotEngaged" ;
VAL_ 2566759427 EnggmntSttsPTOEngAccssoryDrive1 3 "NotAvailable" 2 "Error" 1 "DriveEngaged" 0 "DriveNotEngaged" ;
VAL_ 2566759427 EnggmntCnsntPTOEngAccssryDrive2 3 "NotAvailable" 2 "Error" 1 "CnsentGivenPTODriveMayBeEngaged" 0 "CnsntNtGvnPTODrvMayNotBeEngaged" ;
VAL_ 2566759427 EnggmntCnsntPTOEngAccssryDrive1 3 "NotAvailable" 2 "Error" 1 "CnsentGivenPTODriveMayBeEngaged" 0 "CnsntNtGvnPTODrvMayNotBeEngaged" ;
VAL_ 2566759427 EngagementStatusPTOEngFlywheel 3 "NotAvailable" 2 "Error" 1 "DriveEngaged" 0 "DriveNotEngaged" ;
VAL_ 2566759427 EngagementConsentPTOEngFlywheel 3 "NotAvailable" 2 "Error" 1 "CnsentGivenPTODriveMayBeEngaged" 0 "CnsntNtGvnPTODrvMayNotBeEngaged" ;
VAL_ 2566759427 EnblSwitchPTOEngAccessoryDrive2 3 "NotAvailable" 2 "Error" 1 "EnblSwitchOnPTOOperationDesired" 0 "EnblSwtchOffPTOOprtonNotDesired" ;
VAL_ 2566759427 EnblSwitchPTOEngAccessoryDrive1 3 "NotAvailable" 2 "Error" 1 "EnblSwitchOnPTOOperationDesired" 0 "EnblSwtchOffPTOOprtonNotDesired" ;
VAL_ 2566759427 EnableSwitchPTOEngFlywheel 3 "NotAvailable" 2 "Error" 1 "EnblSwitchOnPTOOperationDesired" 0 "EnblSwtchOffPTOOprtonNotDesired" ;
VAL_ 2566759427 AtLeastOnePTOEngaged 3 "NotAvailable" 2 "Error" 1 "AtLeastOnePTODriveIsEngaged" 0 "NoPTODriveIsEngaged" ;
VAL_ 2566841088 SupportTSC1CtrlPurposeGroup4 1 "P25ReservedForAssignmentBySAE" ;
VAL_ 2566841088 SupportTSC1CtrlPurposeGroup3 1 "P17ReservedForAssignmentBySAE" ;
VAL_ 2566841088 SupportTSC1CtrlPurposeGroup2 1 "P9ReservedForAssignmentBySAE" ;
VAL_ 2566841088 SupportTSC1CtrlPurposeGroup1 16 "P5EngineProtection" 8 "P4RoadSpeedGov" 4 "P3PTOGovernor" 2 "P2CruiseControl" 1 "P1AccelPedal_OperatorSelection" ;
VAL_ 2566841088 SupportVariableRateTSC1Message 1 "MsTransRate" ;
VAL_ 2566834947 DM2FlashRedStopLamp 3 "Unavailable / Do Not Flash" 2 "Reserved" 1 "Fast Flash" 0 "Slow Flash" ;
VAL_ 2566834947 DM2FlashProtectLamp 3 "Unavailable / Do Not Flash" 2 "Reserved" 1 "Fast Flash" 0 "Slow Flash" ;
VAL_ 2566834947 DM2FlashMalfuncIndicatorLamp 3 "Unavailable / Do Not Flash" 2 "Reserved" 1 "Fast Flash" 0 "Slow Flash" ;
VAL_ 2566834947 DM2FlashAmberWarningLamp 3 "Unavailable / Do Not Flash" 2 "Reserved" 1 "Fast Flash" 0 "Slow Flash" ;
VAL_ 2566834947 DM2MalfunctionIndicatorLampState 3 "Not available" 2 "Reserved" 1 "Lamp on" 0 "Lamp off" ;
VAL_ 2566834947 DM2AmberWarningLampStatus 3 "Not available" 2 "Reserved" 1 "Lamp on" 0 "Lamp off" ;
VAL_ 2566834947 DM2RedStopLampState 3 "Not available" 2 "Reserved" 1 "Lamp on" 0 "Lamp off" ;
VAL_ 2566834947 DM2ProtectLampStatus 3 "Not available" 2 "Reserved" 1 "Lamp on" 0 "Lamp off" ;
VAL_ 2566834691 FlashRedStopLamp 3 "Unavailable / Do Not Flash" 2 "Reserved" 1 "Fast Flash" 0 "Slow Flash" ;
VAL_ 2566834691 FlashProtectLamp 3 "Unavailable / Do Not Flash" 2 "Reserved" 1 "Fast Flash" 0 "Slow Flash" ;
VAL_ 2566834691 FlashMalfuncIndicatorLamp 3 "Unavailable / Do Not Flash" 2 "Reserved" 1 "Fast Flash" 0 "Slow Flash" ;
VAL_ 2566834691 FlashAmberWarningLamp 3 "Unavailable / Do Not Flash" 2 "Reserved" 1 "Fast Flash" 0 "Slow Flash" ;
VAL_ 2566834691 MalfunctionIndicatorLampState 3 "Not available" 2 "Reserved" 1 "Lamp on" 0 "Lamp off" ;
VAL_ 2566834691 AmberWarningLampStatus 3 "Not available" 2 "Reserved" 1 "Lamp on" 0 "Lamp off" ;
VAL_ 2566834691 RedStopLampState 3 "Not available" 2 "Reserved" 1 "Lamp on" 0 "Lamp off" ;
VAL_ 2566834691 ProtectLampStatus 3 "Not available" 2 "Reserved" 1 "Lamp on" 0 "Lamp off" ;
VAL_ 2566834688 FlashRedStopLamp 3 "Unavailable / Do Not Flash" 2 "Reserved" 1 "Fast Flash" 0 "Slow Flash" ;
VAL_ 2566834688 FlashProtectLamp 3 "Unavailable / Do Not Flash" 2 "Reserved" 1 "Fast Flash" 0 "Slow Flash" ;
VAL_ 2566834688 FlashMalfuncIndicatorLamp 3 "Unavailable / Do Not Flash" 2 "Reserved" 1 "Fast Flash" 0 "Slow Flash" ;
VAL_ 2566834688 FlashAmberWarningLamp 3 "Unavailable / Do Not Flash" 2 "Reserved" 1 "Fast Flash" 0 "Slow Flash" ;
VAL_ 2566834688 MalfunctionIndicatorLampStatus 3 "Not available" 2 "Reserved" 1 "Lamp on" 0 "Lamp off" ;
VAL_ 2566834688 AmberWarningLampStatus 3 "Not available" 2 "Reserved" 1 "Lamp on" 0 "Lamp off" ;
VAL_ 2566834688 RedStopLampState 3 "Not available" 2 "Reserved" 1 "Lamp on" 0 "Lamp off" ;
VAL_ 2566834688 ProtectLampStatus 3 "Not available" 2 "Reserved" 1 "Lamp on" 0 "Lamp off" ;
VAL_ 2164211715 CoastModeStatus 3 "Not Available" 2 "Error" 1 "Enabled" 0 "Disabled" ;
VAL_ 2164211715 TransmissionType 15 "Legacy Trans" 0 "Fuel Eco Trans" ;
VAL_ 2164211715 Disable_VGT_Braking 3 "Description for the value '0x3'" 2 "Error" 1 "True" 0 "False" ;
VAL_ 2164151550 EngineCoastModeStatus 3 "Not Available" 2 "Error" 1 "Enabled" 0 "Disabled" ;
VAL_ 2566844721 ParkBrakeReleaseInhibitRq 3 "Unavailable" 2 "SAEReserved" 1 "ParkBrakeReleaseInhibitRqed" 0 "ParkBrakeReleaseInhibitNotRqed" ;
VAL_ 2566844721 PTOGovernorState 31 "NotAvailable" 20 "11110NotDefined" 19 "PTOSetSpeedMemory2" 18 "PTOSetSpeedMemory1" 17 "PreprogrammedSetSpeed8" 16 "PreprogrammedSetSpeed7" 15 "PreprogrammedSetSpeed6" 14 "PreprogrammedSetSpeed5" 13 "PreprogrammedSetSpeed4" 12 "PreprogrammedSetSpeed3" 11 "PreprogrammedSetSpeed2" 10 "PreprogrammedSetSpeed1" 9 "AccelOverride" 8 "Accelerate" 7 "Resume" 6 "Decelerate_Coast" 5 "Set" 4 "RemoteStandby" 3 "Standby" 2 "RemoteHold" 1 "Hold" 0 "Off_Disabled" ;
VAL_ 2566844721 EngShutdownOverrideSwitch 3 "NotAvailable" 2 "Error" 1 "On" 0 "Off" ;
VAL_ 2566844721 EngTestModeSwitch 3 "NotAvailable" 2 "Error" 1 "On" 0 "Off" ;
VAL_ 2566844721 EngIdleDecrementSwitch 3 "NotAvailable" 2 "Error" 1 "On" 0 "Off" ;
VAL_ 2566844721 EngIdleIncrementSwitch 3 "NotAvailable" 2 "Error" 1 "On" 0 "Off" ;
VAL_ 2566844721 CruiseCtrlStates 7 "NotAvailable" 6 "AccelOverride" 5 "Set" 4 "Resume" 3 "Decelerate" 2 "Accelerate" 1 "Hold" 0 "Off_Disabled" ;
VAL_ 2566844721 CruiseCtrlAccelerateSwitch 3 "NotAvailable" 2 "Error" 1 "CrsCtrlActivatorInPosAccelerate" 0 "CrsCtrlActvtrNotInPosAccelerate" ;
VAL_ 2566844721 CruiseCtrlResumeSwitch 3 "NotAvailable" 2 "Error" 1 "CruiseCtrlActivatorInPosResume" 0 "CrseCtrlActivatorNotInPosResume" ;
VAL_ 2566844721 CruiseCtrlCoastSwitch 3 "NotAvailable" 2 "Error" 1 "CruiseCtrlActivatorInPosCoast" 0 "CriseCtrlActivatorNotInPosCoast" ;
VAL_ 2566844721 CruiseCtrlSetSwitch 3 "NotAvailable" 2 "Error" 1 "CruiseCtrlActivatorInPosSet" 0 "CruiseCtrlActivatorNotInPosSet" ;
VAL_ 2566844721 ClutchSwitch 3 "NotAvailable" 2 "Error" 1 "ClutchPedalDepressed" 0 "ClutchPedalReleased" ;
VAL_ 2566844721 BrakeSwitch_SA31 3 "NotAvailable" 2 "Error" 1 "BrakePedalDepressed" 0 "BrakePedalReleased" ;
VAL_ 2566844721 CruiseCtrlEnableSwitch 3 "NotAvailable" 2 "Error" 1 "CruiseCtrlEnabled" 0 "CruiseCtrlDisabled" ;
VAL_ 2566844721 CruiseCtrlActive 3 "NotAvailable" 2 "Error" 1 "CruiseCtrlSwitchedOn" 0 "CruiseCtrlSwitchedOff" ;
VAL_ 2566844721 CruiseCtrlPauseSwitch 3 "TakeNoAction" 2 "ErrorIndicator" 1 "On" 0 "Off" ;
VAL_ 2566844721 ParkingBrakeSwitch 3 "NotAvailable" 2 "Error" 1 "ParkingBrakeSet" 0 "ParkingBrakeNotSet" ;
VAL_ 2566844721 TwoSpeedAxleSwitch 3 "NotAvailable" 2 "Error" 1 "HighSpeedRange" 0 "LowSpeedRange" ;
VAL_ 2566844711 ParkBrakeReleaseInhibitRq 3 "Unavailable" 2 "SAEReserved" 1 "ParkBrakeReleaseInhibitRqed" 0 "ParkBrakeReleaseInhibitNotRqed" ;
VAL_ 2566844711 PTOGovernorState 31 "NotAvailable" 20 "11110NotDefined" 19 "PTOSetSpeedMemory2" 18 "PTOSetSpeedMemory1" 17 "PreprogrammedSetSpeed8" 16 "PreprogrammedSetSpeed7" 15 "PreprogrammedSetSpeed6" 14 "PreprogrammedSetSpeed5" 13 "PreprogrammedSetSpeed4" 12 "PreprogrammedSetSpeed3" 11 "PreprogrammedSetSpeed2" 10 "PreprogrammedSetSpeed1" 9 "AccelOverride" 8 "Accelerate" 7 "Resume" 6 "Decelerate_Coast" 5 "Set" 4 "RemoteStandby" 3 "Standby" 2 "RemoteHold" 1 "Hold" 0 "Off_Disabled" ;
VAL_ 2566844711 EngShutdownOverrideSwitch 3 "NotAvailable" 2 "Error" 1 "On" 0 "Off" ;
VAL_ 2566844711 EngTestModeSwitch 3 "NotAvailable" 2 "Error" 1 "On" 0 "Off" ;
VAL_ 2566844711 EngIdleDecrementSwitch 3 "NotAvailable" 2 "Error" 1 "On" 0 "Off" ;
VAL_ 2566844711 EngIdleIncrementSwitch 3 "NotAvailable" 2 "Error" 1 "On" 0 "Off" ;
VAL_ 2566844711 CruiseCtrlStates 7 "NotAvailable" 6 "AccelOverride" 5 "Set" 4 "Resume" 3 "Decelerate" 2 "Accelerate" 1 "Hold" 0 "Off_Disabled" ;
VAL_ 2566844711 CruiseCtrlAccelerateSwitch 3 "NotAvailable" 2 "Error" 1 "CrsCtrlActivatorInPosAccelerate" 0 "CrsCtrlActvtrNotInPosAccelerate" ;
VAL_ 2566844711 CruiseCtrlResumeSwitch 3 "NotAvailable" 2 "Error" 1 "CruiseCtrlActivatorInPosResume" 0 "CrseCtrlActivatorNotInPosResume" ;
VAL_ 2566844711 CruiseCtrlCoastSwitch 3 "NotAvailable" 2 "Error" 1 "CruiseCtrlActivatorInPosCoast" 0 "CriseCtrlActivatorNotInPosCoast" ;
VAL_ 2566844711 CruiseCtrlSetSwitch 3 "NotAvailable" 2 "Error" 1 "CruiseCtrlActivatorInPosSet" 0 "CruiseCtrlActivatorNotInPosSet" ;
VAL_ 2566844711 ClutchSwitch 3 "NotAvailable" 2 "Error" 1 "ClutchPedalDepressed" 0 "ClutchPedalReleased" ;
VAL_ 2566844711 BrakeSwitch_SA27 3 "NotAvailable" 2 "Error" 1 "BrakePedalDepressed" 0 "BrakePedalReleased" ;
VAL_ 2566844711 CruiseCtrlEnableSwitch 3 "NotAvailable" 2 "Error" 1 "CruiseCtrlEnabled" 0 "CruiseCtrlDisabled" ;
VAL_ 2566844711 CruiseCtrlActive 3 "NotAvailable" 2 "Error" 1 "CruiseCtrlSwitchedOn" 0 "CruiseCtrlSwitchedOff" ;
VAL_ 2566844711 CruiseCtrlPauseSwitch 3 "TakeNoAction" 2 "ErrorIndicator" 1 "On" 0 "Off" ;
VAL_ 2566844711 ParkingBrakeSwitch 3 "NotAvailable" 2 "Error" 1 "ParkingBrakeSet" 0 "ParkingBrakeNotSet" ;
VAL_ 2566844711 TwoSpeedAxleSwitch 3 "NotAvailable" 2 "Error" 1 "HighSpeedRange" 0 "LowSpeedRange" ;
